VERSION ""

NS_ :

BS_:

BU_: CH DIPF DIPR ETH FC HVI HVS PARTY SDCV VEH VIRT

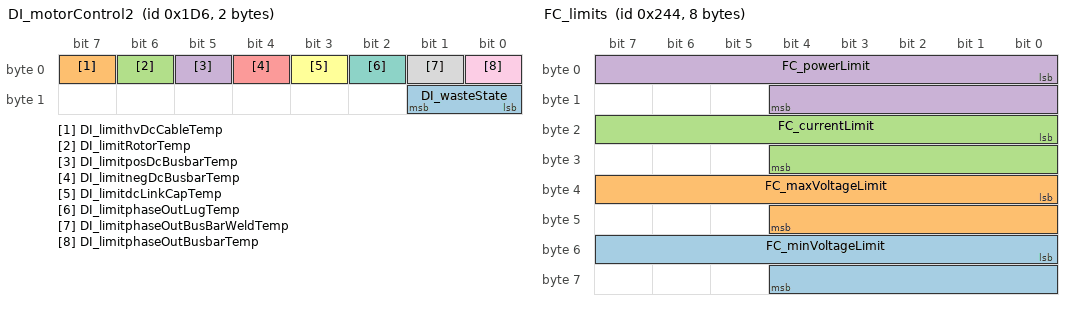
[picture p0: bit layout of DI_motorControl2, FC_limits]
BO_ 470 DI_motorControl2: 2 VEH
 SG_ DI_wasteState : 8|2@1+ (1,0) [0|2] ""  gtw
 SG_ DI_limithvDcCableTemp : 7|1@1+ (1,0) [0|1] ""  gtw
 SG_ DI_limitRotorTemp : 6|1@1+ (1,0) [0|1] ""  gtw
 SG_ DI_limitposDcBusbarTemp : 5|1@1+ (1,0) [0|1] ""  gtw
 SG_ DI_limitnegDcBusbarTemp : 4|1@1+ (1,0) [0|1] ""  gtw
 SG_ DI_limitdcLinkCapTemp : 3|1@1+ (1,0) [0|1] ""  gtw
 SG_ DI_limitphaseOutLugTemp : 2|1@1+ (1,0) [0|1] ""  gtw
 SG_ DI_limitphaseOutBusBarWeldTemp : 1|1@1+ (1,0) [0|1] ""  gtw
 SG_ DI_limitphaseOutBusbarTemp : 0|1@1+ (1,0) [0|1] ""  gtw

BO_ 580 FC_limits: 8 VEH
 SG_ FC_minVoltageLimit : 48|13@1+ (0.0732421875,0) [0|599.92675781] "V"  X
 SG_ FC_maxVoltageLimit : 32|13@1+ (0.07324218755,0) [0|599.92675822] "V"  X
 SG_ FC_currentLimit : 16|13@1+ (0.0732421875,0) [0|599.92675781] "A"  gtw
 SG_ FC_powerLimit : 0|13@1+ (0.062255859376,0) [0|509.93774415] "kW"  dbg

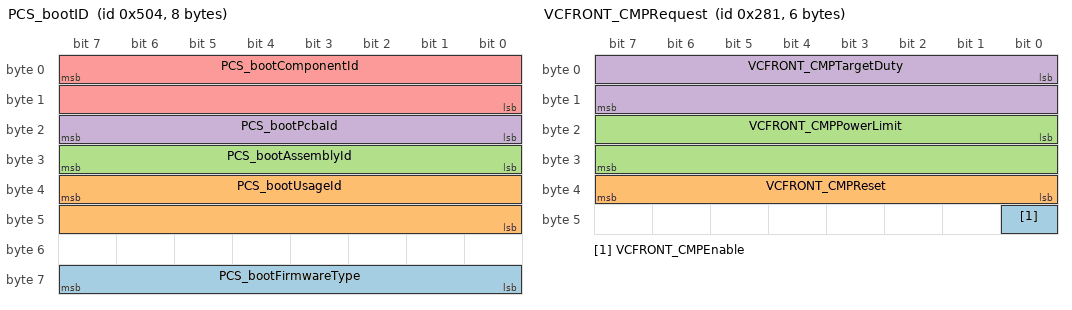
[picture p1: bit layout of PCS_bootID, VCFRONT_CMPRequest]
BO_ 1284 PCS_bootID: 8 VEH
 SG_ PCS_bootFirmwareType : 63|8@0+ (1,0) [0|255] ""  gtwu
 SG_ PCS_bootUsageId : 39|16@0+ (1,0) [0|65535] ""  gtwu
 SG_ PCS_bootAssemblyId : 31|8@0+ (1,0) [0|255] ""  gtwu
 SG_ PCS_bootPcbaId : 23|8@0+ (1,0) [0|255] ""  gtw
 SG_ PCS_bootComponentId : 7|16@0+ (1,0) [0|65535] ""  gtwu

BO_ 641 VCFRONT_CMPRequest: 6 VEH
 SG_ VCFRONT_CMPEnable : 40|1@1+ (1,0) [0|1] ""  cmp
 SG_ VCFRONT_CMPReset : 32|8@1+ (1,0) [0|255] ""  cmp
 SG_ VCFRONT_CMPPowerLimit : 16|16@1+ (1,0) [0|65534] "W"  cmp
 SG_ VCFRONT_CMPTargetDuty : 0|16@1+ (0.1,0) [0|100] "%"  cmp

BO_ 659 UI_chassisControl: 8 VEH
 SG_ UI_chassisControlChecksum : 56|8@1+ (1,0) [0|255] ""  epbl
 SG_ UI_chassisControlCounter : 52|4@1+ (1,0) [0|15] ""  epbl
 SG_ UI_selfParkTune : 48|4@1+ (1,0) [0|15] ""  das
 SG_ UI_redLightStopSignEnable : 46|2@1+ (1,0) [0|3] ""  das
 SG_ UI_pedalSafetyEnable : 44|2@1+ (1,0) [0|3] ""  das
 SG_ UI_ldwEnable : 42|2@1+ (1,0) [0|3] ""  das
 SG_ UI_latControlEnable : 40|2@1+ (1,0) [0|3] ""  das
 SG_ UI_fcwSensitivity : 38|2@1+ (1,0) [0|3] ""  das
 SG_ UI_fcwEnable : 36|2@1+ (1,0) [0|3] ""  das
 SG_ UI_bsdEnable : 34|2@1+ (1,0) [0|3] ""  das
 SG_ UI_autoLaneChangeEnable : 32|2@1+ (1,0) [0|3] ""  das
 SG_ UI_autoParkRequest : 28|4@1+ (1,0) [0|15] ""  das
 SG_ UI_rebootAutopilot : 27|1@1+ (1,0) [0|1] ""  X
 SG_ UI_ahlbEnable : 24|2@1+ (1,0) [0|3] ""  das
 SG_ UI_aesEnable : 22|2@1+ (1,0) [0|3] ""  das
 SG_ UI_aebEnable : 20|2@1+ (1,0) [0|3] ""  das
 SG_ UI_accOvertakeEnable : 18|2@1+ (1,0) [0|3] ""  das
 SG_ UI_dasDebugEnable : 17|1@1+ (1,0) [0|1] ""  das
 SG_ UI_distanceUnits : 16|1@1+ (1,0) [0|1] ""  di
 SG_ UI_suspensionLevelRequest : 13|3@1+ (1,0) [0|7] ""  X
 SG_ UI_trailerMode : 12|1@1+ (1,0) [0|1] ""  das
 SG_ UI_zeroSpeedConfirmed : 10|2@1+ (1,0) [0|3] ""  epbl
 SG_ UI_winchModeRequest : 8|2@1+ (1,0) [0|2] ""  epbl
 SG_ UI_narrowGarages : 7|1@1+ (1,0) [0|1] ""  das
 SG_ UI_parkBrakeRequest : 5|2@1+ (1,0) [0|3] ""  epbl
 SG_ UI_tractionControlMode : 2|3@1+ (1,0) [0|5] ""  di
 SG_ UI_steeringTuneRequest : 0|2@1+ (1,0) [0|2] ""  X

BO_ 504 VCLEFT_intrusionSensorStatus: 4 VEH
 SG_ VCLEFT_intrusionUltraTripped : 26|1@1+ (1,0) [0|1] ""  gtw
 SG_ VCLEFT_intrusionTiltTripped : 25|1@1+ (1,0) [0|1] ""  gtw
 SG_ VCLEFT_sirenMIA : 24|1@1+ (1,0) [0|1] ""  vcfront
 SG_ VCLEFT_DBG_System_Error : 23|1@1+ (1,0) [0|1] ""  gtw
 SG_ VCLEFT_DBG_LM_SelfTest_Status : 22|1@1+ (1,0) [0|1] ""  gtw
 SG_ VCLEFT_DBG_USS_SelfTest_Status : 21|1@1+ (1,0) [0|1] ""  gtw
 SG_ VCLEFT_DBG_Eeprom_ST_Status : 20|1@1+ (1,0) [0|1] ""  gtw
 SG_ VCLEFT_DBG_Reserved_08 : 19|1@1+ (1,0) [0|1] ""  X
 SG_ VCLEFT_DBG_Reserved_07 : 18|1@1+ (1,0) [0|1] ""  X
 SG_ VCLEFT_DBG_Siren_is_sounding : 17|1@1+ (1,0) [0|1] ""  gtw
 SG_ VCLEFT_DBG_Invalid_Parameter : 16|1@1+ (1,0) [0|1] ""  gtw
 SG_ VCLEFT_DBG_Siren_Int_Trigger : 15|1@1+ (1,0) [0|1] ""  gtw
 SG_ VCLEFT_DBG_Siren_ST_Status : 14|1@1+ (1,0) [0|1] ""  gtw
 SG_ VCLEFT_DBG_LM_Alarm_Status : 13|1@1+ (1,0) [0|1] ""  gtw
 SG_ VCLEFT_DBG_USS_Alarm_Status : 12|1@1+ (1,0) [0|1] ""  gtw
 SG_ VCLEFT_DBG_Veh_Settings_Status : 8|4@1+ (1,0) [0|15] ""  gtw
 SG_ VCLEFT_DBG_SelfTest_Status : 7|1@1+ (1,0) [0|1] ""  gtw
 SG_ VCLEFT_DBG_Suspensions_Status : 6|1@1+ (1,0) [0|1] ""  gtw
 SG_ VCLEFT_DBG_Window_Status : 5|1@1+ (1,0) [0|1] ""  gtw
 SG_ VCLEFT_DBG_Heater_Status : 4|1@1+ (1,0) [0|1] ""  gtw
 SG_ VCLEFT_DBG_Air_Cond_Status : 3|1@1+ (1,0) [0|1] ""  gtw
 SG_ VCLEFT_DBG_System_Status : 0|3@1+ (1,0) [0|7] ""  gtw

BO_ 895 FC_alertMatrix3: 8 VEH
 SG_ FC_a187_CA_evseConLockTimeout : 58|1@1+ (1,0) [0|1] ""  gtw
 SG_ FC_a186_CA_fcContOpenTimeout : 57|1@1+ (1,0) [0|1] ""  gtw
 SG_ FC_a185_CA_vehReadyDeasserted : 56|1@1+ (1,0) [0|1] ""  gtw
 SG_ FC_a184_CA_evseBatMalfunc : 55|1@1+ (1,0) [0|1] ""  gtw
 SG_ FC_a183_CA_evseBatIncompat : 54|1@1+ (1,0) [0|1] ""  gtw
 SG_ FC_a182_CA_evseChrMalfunc : 53|1@1+ (1,0) [0|1] ""  gtw
 SG_ FC_a181_CA_vRegBrownout : 52|1@1+ (1,0) [0|1] ""  gtw
 SG_ FC_a180_CA_chargingProblem : 51|1@1+ (1,0) [0|1] ""  gtw
 SG_ FC_a179_CA_startupProblem : 50|1@1+ (1,0) [0|1] ""  gtw
 SG_ FC_a178_CA_evseStartTimeout : 49|1@1+ (1,0) [0|1] ""  gtw
 SG_ FC_a177_CA_bmsCtrCloseTimeout : 48|1@1+ (1,0) [0|1] ""  gtw
 SG_ FC_a176_CA_chargingBusTimeout : 47|1@1+ (1,0) [0|1] ""  gtw
 SG_ FC_a175_CA_evseIsoTestTimeout : 46|1@1+ (1,0) [0|1] ""  gtw
 SG_ FC_a174_CA_vehReadyTimeout : 45|1@1+ (1,0) [0|1] ""  gtw
 SG_ FC_a173_CA_evseDataTimeout : 44|1@1+ (1,0) [0|1] ""  gtw
 SG_ FC_a172_CA_ss2LowTimeout : 43|1@1+ (1,0) [0|1] ""  gtw
 SG_ FC_a171_CA_vehConLockTimeout : 42|1@1+ (1,0) [0|1] ""  gtw
 SG_ FC_a170_CA_vehDataTimeout : 41|1@1+ (1,0) [0|1] ""  gtw
 SG_ FC_a169_CA_pilotAcceptTimeout : 40|1@1+ (1,0) [0|1] ""  gtw
 SG_ FC_a168_CA_proxTimeout : 39|1@1+ (1,0) [0|1] ""  gtw
 SG_ FC_a167_CA_isoVoltageLow : 38|1@1+ (1,0) [0|1] ""  gtw
 SG_ FC_a166_CA_vehConnUnlocked : 37|1@1+ (1,0) [0|1] ""  gtw
 SG_ FC_a165_CA_evseConnUnlocked : 36|1@1+ (1,0) [0|1] ""  gtw
 SG_ FC_a164_CA_proxDisconnected : 35|1@1+ (1,0) [0|1] ""  gtw
 SG_ FC_a163_CA_pcbTempHiFoldBk : 34|1@1+ (1,0) [0|1] ""  gtw
 SG_ FC_a162_CA_evseTempHiFoldBk : 33|1@1+ (1,0) [0|1] ""  gtw
 SG_ FC_a161_CA_vehTempHiFoldBk : 32|1@1+ (1,0) [0|1] ""  gtw
 SG_ FC_a160_CA_ss2Deasserted : 31|1@1+ (1,0) [0|1] ""  gtw
 SG_ FC_a159_CA_wdtExpired : 30|1@1+ (1,0) [0|1] ""  gtw
 SG_ FC_a158_CA_evseOverCurrent : 29|1@1+ (1,0) [0|1] ""  gtw
 SG_ FC_a157_CA_unused : 28|1@1+ (1,0) [0|1] ""  gtw
 SG_ FC_a156_CA_flybackRunTimeout : 27|1@1+ (1,0) [0|1] ""  gtw
 SG_ FC_a155_CA_evseToPcbDeltaLo : 26|1@1+ (1,0) [0|1] ""  gtw
 SG_ FC_a154_CA_vehToPcbDeltaLo : 25|1@1+ (1,0) [0|1] ""  gtw
 SG_ FC_a153_CA_evseToPcbDeltaHi : 24|1@1+ (1,0) [0|1] ""  gtw
 SG_ FC_a152_CA_vehToPcbDeltaHi : 23|1@1+ (1,0) [0|1] ""  gtw
 SG_ FC_a151_CA_vehToEvseDeltaLo : 22|1@1+ (1,0) [0|1] ""  gtw
 SG_ FC_a150_CA_vehToEvseDeltaHi : 21|1@1+ (1,0) [0|1] ""  gtw
 SG_ FC_a149_CA_pcb_UT : 20|1@1+ (1,0) [0|1] ""  gtw
 SG_ FC_a148_CA_evseConn_UT : 19|1@1+ (1,0) [0|1] ""  gtw
 SG_ FC_a147_CA_vehConn_UT : 18|1@1+ (1,0) [0|1] ""  gtw
 SG_ FC_a146_CA_flybackBusLoadHi : 17|1@1+ (1,0) [0|1] ""  gtw
 SG_ FC_a145_CA_flybackDataStale : 16|1@1+ (1,0) [0|1] ""  gtw
 SG_ FC_a144_CA_flybackUnstable : 15|1@1+ (1,0) [0|1] ""  gtw
 SG_ FC_a143_CA_pcb_OT : 14|1@1+ (1,0) [0|1] ""  gtw
 SG_ FC_a142_CA_evseConn_OT : 13|1@1+ (1,0) [0|1] ""  gtw
 SG_ FC_a141_CA_vehConn_OT : 12|1@1+ (1,0) [0|1] ""  gtw
 SG_ FC_a140_CA_bmsIncompatible : 11|1@1+ (1,0) [0|1] ""  gtw
 SG_ FC_a139_CA_ss2NotLow : 10|1@1+ (1,0) [0|1] ""  gtw
 SG_ FC_a138_CA_hwProxTrip : 9|1@1+ (1,0) [0|1] ""  gtw
 SG_ FC_a137_CA_evseRxBufOvf : 8|1@1+ (1,0) [0|1] ""  gtw
 SG_ FC_a136_CA_evseTxBufOvf : 7|1@1+ (1,0) [0|1] ""  gtw
 SG_ FC_a135_CA_vehRxBufOvf : 6|1@1+ (1,0) [0|1] ""  gtw
 SG_ FC_a134_CA_vehTxBufOvf : 5|1@1+ (1,0) [0|1] ""  gtw
 SG_ FC_a133_CA_evseMia : 4|1@1+ (1,0) [0|1] ""  gtw
 SG_ FC_a132_CA_bmsMia : 3|1@1+ (1,0) [0|1] ""  gtw
 SG_ FC_a131_CA_flyback_HW_OV : 2|1@1+ (1,0) [0|1] ""  gtw
 SG_ FC_a130_CA_flyback_SW_OV : 1|1@1+ (1,0) [0|1] ""  gtw
 SG_ FC_a129_CA_flyback_HW_OC : 0|1@1+ (1,0) [0|1] ""  gtw

BO_ 790 PM_info: 8 VEH
 SG_ PM_subUsageId m11 : 48|16@1+ (1,0) [0|65535] ""  gtw
 SG_ PM_componentId m10 : 48|16@1+ (1,0) [0|65535] ""  gtw
 SG_ PM_hardwareId m10 : 32|8@1+ (1,0) [0|252] ""  gtw
 SG_ PM_applicationCrc m13 : 32|32@1+ (1,0) [0|4294967295] ""  gtw
 SG_ PM_bootloaderCrc m20 : 32|32@1+ (1,0) [0|4294967295] ""  gtw
 SG_ PM_diNodeApplicationCrc m21 : 32|32@1+ (1,0) [0|4294967295] ""  gtw
 SG_ PM_usageId m11 : 32|16@1+ (1,0) [0|65535] ""  gtw
 SG_ PM_bootloaderSvnUrlHash m14 : 32|32@1+ (1,0) [0|4294967295] ""  gtw
 SG_ PM_assemblyId m11 : 24|8@1+ (1,0) [0|255] ""  gtw
 SG_ PM_buildConfigurationId m10 : 16|16@1+ (1,0) [0|65535] ""  gtw
 SG_ PM_pcbaId m11 : 16|8@1+ (1,0) [0|255] ""  gtw
 SG_ PM_diNodeBuildConfigurationId m21 : 16|16@1+ (1,0) [0|65535] ""  X
 SG_ PM_diNodeBuildType m21 : 8|8@1+ (1,0) [0|4] ""  gtw
 SG_ PM_bootloaderSvnRevision m14 : 8|24@1+ (1,0) [0|16777215] ""  gtw
 SG_ PM_udsProtocolVersion m20 : 8|8@1+ (1,0) [0|255] ""  gtw
 SG_ PM_appGitHash m17 : 8|56@1+ (1,0) [0|72057594037927935] ""  gtw
 SG_ PM_platformTyp m19 : 8|8@1+ (1,0) [0|255] ""  gtw
 SG_ PM_buildType m10 : 8|8@1+ (1,0) [0|4] ""  gtw
 SG_ PM_bootGitHash m18 : 8|56@1+ (1,0) [0|72057594037927935] ""  gtw
 SG_ PM_infoIndex M : 0|8@1+ (1,0) [0|255] ""  gtw

BO_ 1622 DI_info: 8 VEH
 SG_ DI_subUsageId m11 : 48|16@1+ (1,0) [0|65535] ""  gtw
 SG_ DI_componentId m10 : 48|16@1+ (1,0) [0|65535] ""  gtw
 SG_ DI_hardwareId m10 : 32|8@1+ (1,0) [0|252] ""  X
 SG_ DI_applicationCrc m13 : 32|32@1+ (1,0) [0|4294967295] ""  gtw
 SG_ DI_applicationSvnUrlHash m12 : 32|32@1+ (1,0) [0|4294967295] ""  gtw
 SG_ DI_bootloaderCrc m20 : 32|32@1+ (1,0) [0|4294967295] ""  gtw
 SG_ DI_usageId m11 : 32|16@1+ (1,0) [0|65535] ""  gtw
 SG_ DI_bootloaderSvnUrlHash m14 : 32|32@1+ (1,0) [0|4294967295] ""  gtw
 SG_ DI_assemblyId m11 : 24|8@1+ (1,0) [0|255] ""  gtw
 SG_ DI_buildConfigurationId m10 : 16|16@1+ (1,0) [0|65535] ""  gtw
 SG_ DI_oilPumpAppCrc m16 : 16|32@1+ (1,0) [0|4294967295] ""  gtw
 SG_ DI_pcbaId m11 : 16|8@1+ (1,0) [0|255] ""  gtw
 SG_ DI_applicationSvnRevision m12 : 8|24@1+ (1,0) [0|16777215] ""  X
 SG_ DI_bootloaderSvnRevision m14 : 8|24@1+ (1,0) [0|16777215] ""  gtw
 SG_ DI_infoBootLdUdsProtocolVersion m20 : 8|8@1+ (1,0) [0|255] ""  X
 SG_ DI_subcomponentGitHash m31 : 8|56@1+ (1,0) [0|72057594037927935] ""  X
 SG_ DI_oilPumpBuildType m16 : 8|3@1+ (1,0) [0|4] ""  gtw
 SG_ DI_appGitHash m17 : 8|56@1+ (1,0) [0|72057594037927935] ""  X
 SG_ DI_platformTyp m19 : 8|8@1+ (1,0) [0|255] ""  X
 SG_ DI_bootGitHash m18 : 8|56@1+ (1,0) [0|72057594037927935] ""  gtw
 SG_ DI_buildType m10 : 8|3@1+ (1,0) [0|4] ""  gtw
 SG_ DI_infoIndex M : 0|8@1+ (1,0) [0|255] ""  gtw

BO_ 738 VCLEFT_seatStatus2: 8 VEH
 SG_ VCLEFT_rearRightOccupancyVoltage m2 : 54|10@1+ (0.01,0) [0|10.23] "V"  gtw
 SG_ VCLEFT_frontSeatHeatPowered m0 : 45|1@1+ (1,0) [0|1] ""  X
 SG_ VCLEFT_rearLBackHeatPowered m1 : 45|1@1+ (1,0) [0|1] ""  X
 SG_ VCLEFT_frontSeatHeatInhibited m0 : 44|1@1+ (1,0) [0|1] ""  gtw
 SG_ VCLEFT_rearCenterOccupancyVoltag m2 : 44|10@1+ (0.01,0) [0|10.23] "V"  gtw
 SG_ VCLEFT_rearLBackHeatInhibited m1 : 44|1@1+ (1,0) [0|1] ""  gtw
 SG_ VCLEFT_rearLBackHeatTmpTarget m1 : 36|8@1- (0.5,0) [0|60] "degC"  gtw
 SG_ VCLEFT_frontSeatHeatTmpTarget m0 : 36|8@1- (0.5,0) [0|60] "degC"  gtw
 SG_ VCLEFT_rearLeftOccupancyVoltage m2 : 34|10@1+ (0.01,0) [0|10.23] "V"  gtw
 SG_ VCLEFT_frontSeatHeatTmp m0 : 24|12@1- (0.05,0) [-40|80] "degC"  gtw
 SG_ VCLEFT_rearLBackHeatTmp m1 : 24|12@1- (0.05,0) [-40|80] "degC"  X
 SG_ VCLEFT_rearLeftBuckleVoltage m2 : 24|10@1+ (0.01,0) [0|10.23] "V"  gtw
 SG_ VCLEFT_rearLBackHeatDuty m1 : 16|8@1+ (1,0) [0|255] "%"  gtw
 SG_ VCLEFT_frontSeatHeatDuty m0 : 16|8@1+ (1,0) [0|255] "%"  gtw
 SG_ VCLEFT_frontBuckleVoltage m2 : 14|10@1+ (0.01,0) [0|10.23] "V"  gtw
 SG_ VCLEFT_frontSeatHeatCurrent m0 : 4|12@1+ (0.01,0) [0|40.95] "A"  gtw
 SG_ VCLEFT_rearLBackHeatCurrent m1 : 4|12@1+ (0.01,0) [0|40.95] "A"  gtw
 SG_ VCLEFT_frontOccupancyVoltage m2 : 4|10@1+ (0.01,0) [0|10.23] "V"  gtw
 SG_ VCLEFT_seatStatus2Index M : 0|2@1+ (1,0) [0|3] ""  X

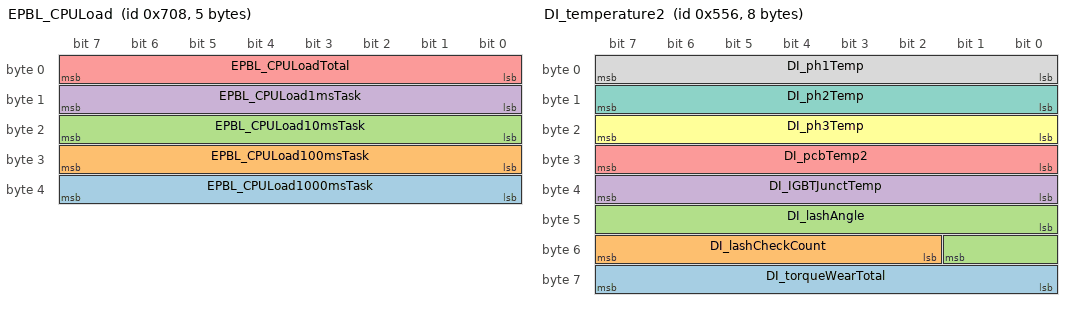
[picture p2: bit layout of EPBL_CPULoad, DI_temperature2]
BO_ 1800 EPBL_CPULoad: 5 VEH
 SG_ EPBL_CPULoad1000msTask : 32|8@1+ (1,0) [0|255] ""  X
 SG_ EPBL_CPULoad100msTask : 24|8@1+ (1,0) [0|255] ""  X
 SG_ EPBL_CPULoad10msTask : 16|8@1+ (1,0) [0|255] ""  X
 SG_ EPBL_CPULoad1msTask : 8|8@1+ (1,0) [0|255] ""  X
 SG_ EPBL_CPULoadTotal : 0|8@1+ (1,0) [0|255] ""  X

BO_ 922 VCSEC_RSSI: 8 VEH
 SG_ VCSEC_BLEDevicePresence3 m1 : 58|5@1+ (1,0) [0|31] ""  gtw
 SG_ VCSEC_BLEDevicePresence0 m0 : 58|5@1+ (1,0) [0|31] ""  gtw
 SG_ VCSEC_UnknownBLEDevicePresent m0 : 57|1@1+ (1,0) [0|1] ""  gtw
 SG_ VCSEC_BLEDevicePresence2 m1 : 53|5@1+ (1,0) [0|31] ""  gtw
 SG_ VCSEC_rearBLEAntennaRSSI1 m0 : 49|8@1- (1,0) [-127|0] ""  gtw
 SG_ VCSEC_BLEDevicePresence1 m1 : 48|5@1+ (1,0) [0|31] ""  gtw
 SG_ VCSEC_rightBLEAntennaRSSI1 m0 : 41|8@1- (1,0) [-127|0] ""  gtw
 SG_ VCSEC_centerBLEAntennaRSSI2 m1 : 40|8@1- (1,0) [-127|0] ""  gtw
 SG_ VCSEC_leftBLEAntennaRSSI1 m0 : 33|8@1- (1,0) [-127|0] ""  gtw
 SG_ VCSEC_rearBLEAntennaRSSI2 m1 : 32|8@1- (1,0) [-127|0] ""  gtw
 SG_ VCSEC_centerBLEAntennaRSSI0 m0 : 25|8@1- (1,0) [-127|0] ""  dbg
 SG_ VCSEC_rightBLEAntennaRSSI2 m1 : 24|8@1- (1,0) [-127|0] ""  gtw
 SG_ VCSEC_rearBLEAntennaRSSI0 m0 : 17|8@1- (1,0) [-127|0] ""  dbg
 SG_ VCSEC_leftBLEAntennaRSSI2 m1 : 16|8@1- (1,0) [-127|0] ""  gtw
 SG_ VCSEC_rightBLEAntennaRSSI0 m0 : 9|8@1- (1,0) [-127|0] ""  dbg
 SG_ VCSEC_centerBLEAntennaRSSI1 m1 : 8|8@1- (1,0) [-127|0] ""  gtw
 SG_ VCSEC_leftBLEAntennaRSSI0 m0 : 1|8@1- (1,0) [-127|0] ""  dbg
 SG_ VCSEC_RSSIChannelIndex M : 0|1@1+ (1,0) [0|1] ""  X

BO_ 1576 UDS_pcsRequest: 8 VEH
 SG_ UDS_pcsRequestData : 7|64@0+ (1,0) [0|18446744073709551615] ""  bms

BO_ 1366 DI_temperature2: 8 VEH
 SG_ DI_torqueWearTotal : 56|8@1+ (0.02,0) [0|5.08] "1"  X
 SG_ DI_lashCheckCount : 50|6@1+ (1,0) [0|63] ""  gtw
 SG_ DI_lashAngle : 40|10@1+ (0.06,0) [0|60] "Deg"  X
 SG_ DI_IGBTJunctTemp : 32|8@1+ (1,-40) [-40|200] "DegC"  X
 SG_ DI_pcbTemp2 : 24|8@1+ (1,-40) [-40|150] "DegC"  X
 SG_ DI_ph3Temp : 16|8@1+ (1,-40) [-40|120] "DegC"  X
 SG_ DI_ph2Temp : 8|8@1+ (1,-40) [-40|120] "DegC"  gtw
 SG_ DI_ph1Temp : 0|8@1+ (1,-40) [-40|120] "DegC"  gtw

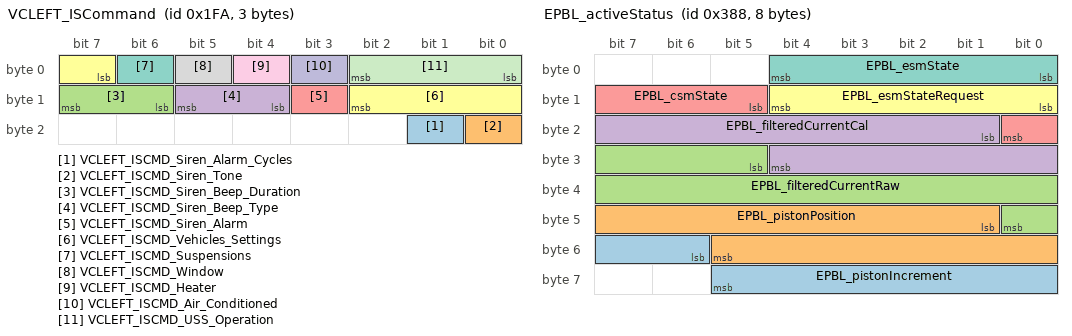
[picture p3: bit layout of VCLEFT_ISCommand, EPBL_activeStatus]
BO_ 506 VCLEFT_ISCommand: 3 VEH
 SG_ VCLEFT_ISCMD_Siren_Alarm_Cycles : 17|1@1+ (1,0) [0|1] ""  gtw
 SG_ VCLEFT_ISCMD_Siren_Tone : 16|1@1+ (1,0) [0|1] ""  gtw
 SG_ VCLEFT_ISCMD_Siren_Beep_Duration : 14|2@1+ (1,0) [0|3] ""  gtw
 SG_ VCLEFT_ISCMD_Siren_Beep_Type : 12|2@1+ (1,0) [0|3] ""  gtw
 SG_ VCLEFT_ISCMD_Siren_Alarm : 11|1@1+ (1,0) [0|1] ""  gtw
 SG_ VCLEFT_ISCMD_Vehicles_Settings : 7|4@1+ (1,0) [0|15] ""  gtw
 SG_ VCLEFT_ISCMD_Suspensions : 6|1@1+ (1,0) [0|1] ""  gtw
 SG_ VCLEFT_ISCMD_Window : 5|1@1+ (1,0) [0|1] ""  gtw
 SG_ VCLEFT_ISCMD_Heater : 4|1@1+ (1,0) [0|1] ""  gtw
 SG_ VCLEFT_ISCMD_Air_Conditioned : 3|1@1+ (1,0) [0|1] ""  gtw
 SG_ VCLEFT_ISCMD_USS_Operation : 0|3@1+ (1,0) [0|7] ""  gtw

BO_ 2024 EPBR_info: 8 VEH
 SG_ EPBR_infoComponentId m10 : 48|16@1+ (1,0) [0|65535] ""  gtw
 SG_ EPBR_infoSubUsageId m11 : 40|16@1+ (1,0) [0|65535] ""  gtw
 SG_ EPBR_infoHardwareId m10 : 32|16@1+ (1,0) [0|65535] ""  gtw
 SG_ EPBR_infoBootCrc m20 : 24|32@1+ (1,0) [0|4294967295] ""  gtw
 SG_ EPBR_infoUsageId m11 : 24|16@1+ (1,0) [0|65535] ""  gtw
 SG_ EPBR_infoAssemblyId m11 : 16|8@1+ (1,0) [0|255] ""  gtw
 SG_ EPBR_infoBuildConfigId m10 : 16|16@1+ (1,0) [0|65535] ""  gtw
 SG_ EPBR_infoPcbaId m11 : 8|8@1+ (1,0) [0|255] ""  gtw
 SG_ EPBR_infoPlatformType m19 : 8|8@1+ (1,0) [0|255] ""  gtw
 SG_ EPBR_infoBootUdsProtoVersion m20 : 8|16@1+ (1,0) [0|65535] ""  gtw
 SG_ EPBR_infoAppGitHash m17 : 8|56@1+ (1,0) [0|72057594037927935] ""  gtw
 SG_ EPBR_infoBuildType m10 : 8|3@1+ (1,0) [0|4] ""  gtw
 SG_ EPBR_infoBootGitHash m18 : 8|56@1+ (1,0) [0|72057594037927935] ""  gtw
 SG_ EPBR_infoAppCrc m13 : 8|32@1+ (1,0) [0|4294967295] ""  gtw
 SG_ EPBR_infoIndex M : 0|8@1+ (1,0) [0|255] ""  gtw

BO_ 533 FC_status2: 1 VEH
 SG_ FC_externalIsolationResistance : 0|8@1+ (40,0) [0|10200] "kOhm"  dbg

BO_ 1359 SCCM_alertMatrix: 8 VEH
 SG_ SCCM_a029_parkButtonMalfunction m0 : 32|1@1+ (1,0) [0|1] ""  gtw
 SG_ SCCM_a028_parkButtonShortToGroun m0 : 31|1@1+ (1,0) [0|1] ""  gtw
 SG_ SCCM_a027_parkButtonOpenCircuit m0 : 30|1@1+ (1,0) [0|1] ""  gtw
 SG_ SCCM_a026_parkButtonInvalidSigna m0 : 29|1@1+ (1,0) [0|1] ""  gtw
 SG_ SCCM_a025_runTimeError m0 : 28|1@1+ (1,0) [0|1] ""  gtw
 SG_ SCCM_a024_gearStalkGenErr m0 : 27|1@1+ (1,0) [0|1] ""  gtw
 SG_ SCCM_a023_gearStalkShortCircuit m0 : 26|1@1+ (1,0) [0|1] ""  gtw
 SG_ SCCM_a022_gearStalkOpenCircuit m0 : 25|1@1+ (1,0) [0|1] ""  gtw
 SG_ SCCM_a021_gearStalkSignalInvalid m0 : 24|1@1+ (1,0) [0|1] ""  gtw
 SG_ SCCM_a020_angleInternalError m0 : 23|1@1+ (1,0) [0|1] ""  gtw
 SG_ SCCM_a019_angleSpeedAboveLimit m0 : 22|1@1+ (1,0) [0|1] ""  gtw
 SG_ SCCM_a018_angleSpeedOutOfRange m0 : 21|1@1+ (1,0) [0|1] ""  gtw
 SG_ SCCM_a017_memoryError m0 : 20|1@1+ (1,0) [0|1] ""  gtw
 SG_ SCCM_a016_hardwareError m0 : 19|1@1+ (1,0) [0|1] ""  gtw
 SG_ SCCM_a015_softwareError m0 : 18|1@1+ (1,0) [0|1] ""  gtw
 SG_ SCCM_a014_voltageLow m0 : 17|1@1+ (1,0) [0|1] ""  gtw
 SG_ SCCM_a013_voltageHigh m0 : 16|1@1+ (1,0) [0|1] ""  gtw
 SG_ SCCM_a012_turnGenErr m0 : 15|1@1+ (1,0) [0|1] ""  gtw
 SG_ SCCM_a011_turnIndHWErr m0 : 14|1@1+ (1,0) [0|1] ""  gtw
 SG_ SCCM_a010_turnIndShortToGnd m0 : 13|1@1+ (1,0) [0|1] ""  gtw
 SG_ SCCM_a009_turnIndOpen m0 : 12|1@1+ (1,0) [0|1] ""  gtw
 SG_ SCCM_a008_turnIndInvalidTrans m0 : 11|1@1+ (1,0) [0|1] ""  gtw
 SG_ SCCM_a007_turnIndComInfo m0 : 10|1@1+ (1,0) [0|1] ""  gtw
 SG_ SCCM_a006_tipWipeShortToGND m0 : 9|1@1+ (1,0) [0|1] ""  gtw
 SG_ SCCM_a005_tipWipeOpen m0 : 8|1@1+ (1,0) [0|1] ""  gtw
 SG_ SCCM_a004_highBeamShortToGND m0 : 7|1@1+ (1,0) [0|1] ""  gtw
 SG_ SCCM_a003_highBeamOpen m0 : 6|1@1+ (1,0) [0|1] ""  gtw
 SG_ SCCM_a002_CANTOut m0 : 5|1@1+ (1,0) [0|1] ""  gtw
 SG_ SCCM_a001_CANBusOff m0 : 4|1@1+ (1,0) [0|1] ""  gtw
 SG_ SCCM_matrixIndex M : 0|4@1+ (1,0) [0|15] ""  gtw

BO_ 904 EPBL_activeStatus: 8 VEH
 SG_ EPBL_pistonIncrement : 54|8@1- (0.05,2.0) [0|4] "vCounts"  X
 SG_ EPBL_pistonPosition : 41|13@1- (9.768009768009769,0.0) [-20000|20000] "vCounts"  X
 SG_ EPBL_filteredCurrentRaw : 29|12@1+ (0.01,0) [0|40.95] "A"  gtw
 SG_ EPBL_filteredCurrentCal : 17|12@1+ (0.01,0) [0|40.95] "A"  gtw
 SG_ EPBL_csmState : 13|4@1+ (1,0) [0|14] ""  gtw
 SG_ EPBL_esmStateRequest : 8|5@1+ (1,0) [0|19] ""  gtw
 SG_ EPBL_esmState : 0|5@1+ (1,0) [0|19] ""  gtw

BO_ 708 PCS_logging: 8 VEH
 SG_ PCS_chg5VL1Enable m5 : 61|1@1+ (1,0) [0|1] ""  gtw
 SG_ PCS_chgPhManOptimalPhsToUse m5 : 59|2@1+ (1,0) [0|3] ""  gtw
 SG_ PCS_chgNgPllLocked m5 : 58|1@1+ (1,0) [0|1] ""  X
 SG_ PCS_chgL1L2PllLocked m5 : 57|1@1+ (1,0) [0|1] ""  gtw
 SG_ PCS_numAlertsSet m9 : 56|7@1+ (1,0) [0|127] ""  X
 SG_ PCS_chgL3NPllLocked m5 : 56|1@1+ (1,0) [0|1] ""  gtw
 SG_ PCS_chgL2NPllLocked m5 : 55|1@1+ (1,0) [0|1] ""  gtw
 SG_ PCS_chgPhBTransientRetryCount m11 : 55|9@1+ (0.1,0) [0|51.1] "-"  gtw
 SG_ PCS_chgPhCTransientRetryCount m12 : 55|9@1+ (0.1,0) [0|51.1] "-"  gtw
 SG_ PCS_chgPhATransientRetryCount m10 : 55|9@1+ (0.1,0) [0|51.1] "-"  gtw
 SG_ PCS_chgL1NPllLocked m5 : 54|1@1+ (1,0) [0|1] ""  gtw
 SG_ PCS_chgInputNGVrms m3 : 53|9@1+ (1,0) [0|511] "V"  gtw
 SG_ PCS_dcdcLvOutputCurrentTempLimit m6 : 52|12@1+ (0.1,0) [0|400] "A"  gtw
 SG_ PCS_chgPhCInputFreqWobble m13 : 48|8@1+ (0.001,0) [0|0.255] "Hz"  gtw
 SG_ PCS_dcdcIntervalMaxLvOutputCurr m18 : 48|12@1+ (1,0) [0|400] "A"  gtw
 SG_ PCS_dcdcIntervalMinLvOutputCurr m19 : 48|12@1+ (1,0) [0|400] "A"  gtw
 SG_ PCS_dLogPhCChannel1Data m14 : 48|16@1- (0.02,0) [-655.36|655.34] "-"  X
 SG_ PCS_dLogPhCChannel4Data m17 : 48|16@1- (0.02,0) [-655.36|655.34] "-"  X
 SG_ PCS_dcdcClaCurrentFreq m7 : 48|12@1+ (0.09765625,0) [0|400] "kHz"  gtw
 SG_ PCS_dLogPhCChannel2Data m15 : 48|16@1- (0.02,0) [-655.36|655.34] "-"  X
 SG_ PCS_chgOutputV m4 : 48|12@1+ (0.146484375,0) [0|600] "V"  gtw
 SG_ PCS_dLogPhCChannel3Data m16 : 48|16@1- (0.02,0) [-655.36|655.34] "-"  X
 SG_ PCS_chgInputNGVdc m21 : 46|10@1- (1,0) [-512|511] "V"  gtw
 SG_ PCS_chgPhManCurrentToDist m5 : 44|10@1+ (0.1,0) [0|100] "A"  gtw
 SG_ PCS_chgInternalPhaseConfig m4 : 44|4@1+ (1,0) [0|8] ""  gtw
 SG_ PCS_1V2Max10s m9 : 43|11@1+ (0.001,0) [0|2.047] "V"  gtw
 SG_ PCS_dcdcPwmEnableLineErrorCount m22 : 42|10@1+ (1,0) [0|1023] ""  gtw
 SG_ PCS_chgRetryCount m5 : 41|3@1+ (1,0) [0|7] ""  gtw
 SG_ PCS_chgInputL1L2Vrms m3 : 41|12@1+ (0.2,0) [0|819] "V"  gtw
 SG_ PCS_chgPhBInputFreqWobble m13 : 40|8@1+ (0.001,0) [0|0.255] "Hz"  gtw
 SG_ PCS_dcdcCurrentLimit m6 : 40|12@1+ (0.1,0) [0|400] "A"  gtw
 SG_ PCS_dcdcHalfPeriodUs m8 : 40|16@1+ (0.00048828125,0) [0|32] "us"  X
 SG_ PCS_chgPhCRetryCount m5 : 38|3@1+ (1,0) [0|7] ""  gtw
 SG_ PCS_dcdcIntervalMaxLvBusVolt m18 : 37|9@1+ (0.1,0) [0|40] "V"  gtw
 SG_ PCS_dcdcTankVoltageTarget m7 : 37|10@1+ (1,0) [0|1024] "V"  gtw
 SG_ PCS_dcdcIntervalMinLvBusVolt m19 : 37|9@1+ (0.1,0) [0|40] "V"  gtw
 SG_ PCS_chgInputL1L2Vdc m21 : 36|10@1- (1,0) [-512|511] "V"  gtw
 SG_ PCS_chgPhBRetryCount m5 : 35|3@1+ (1,0) [0|7] ""  gtw
 SG_ PCS_chgPhARetryCount m5 : 32|3@1+ (1,0) [0|7] ""  gtw
 SG_ PCS_dLogPhBChannel1Data m14 : 32|16@1- (0.02,0) [-655.36|655.34] "-"  X
 SG_ PCS_chgPhCOutputI m2 : 32|8@1+ (0.1,0) [0|25.5] "A"  gtw
 SG_ PCS_chgInputFrequencyL3N m4 : 32|12@1+ (0.01,40) [40|80.95] "Hz"  gtw
 SG_ PCS_chgPwmEnableLineErrorCount m22 : 32|10@1+ (1,0) [0|1023] ""  gtw
 SG_ PCS_chgPhAInputFreqWobble m13 : 32|8@1+ (0.001,0) [0|0.255] "Hz"  gtw
 SG_ PCS_dLogPhBChannel3Data m16 : 32|16@1- (0.02,0) [-655.36|655.34] "-"  X
 SG_ PCS_dLogPhBChannel4Data m17 : 32|16@1- (0.02,0) [-655.36|655.34] "-"  X
 SG_ PCS_1V2Min10s m9 : 32|11@1+ (0.001,0) [0|2.047] "V"  gtw
 SG_ PCS_chgPhBOutputI m1 : 32|8@1+ (0.1,0) [0|25.5] "A"  gtw
 SG_ PCS_chgPhAOutputI m0 : 32|8@1+ (0.1,0) [0|25.5] "A"  gtw
 SG_ PCS_dLogPhBChannel2Data m15 : 32|16@1- (0.02,0) [-655.36|655.34] "-"  X
 SG_ PCS_chgPhBLifetimekWh m11 : 31|24@1+ (0.01,0) [0|167772.15] "kWh"  gtw
 SG_ PCS_chgPhCLifetimekWh m12 : 31|24@1+ (0.01,0) [0|167772.15] "kWh"  gtw
 SG_ PCS_chgPhALifetimekWh m10 : 31|24@1+ (0.01,0) [0|167772.15] "kWh"  gtw
 SG_ PCS_chgInputL3NVrms m3 : 29|12@1+ (0.2,0) [0|819] "V"  gtw
 SG_ PCS_dcdcMaxLvOutputCurrent m6 : 28|12@1+ (0.1,0) [0|400] "A"  gtw
 SG_ PCS_chgPhCLastShutdownReason m5 : 27|5@1+ (1,0) [0|17] ""  gtw
 SG_ PCS_chgInputL3NVdc m21 : 26|10@1- (1,0) [-512|511] "V"  gtw
 SG_ PCS_dcdcTankVoltage m7 : 26|11@1- (1,0) [-1024|1023] "V"  gtw
 SG_ PCS_dcdcIntervalMinHvBusVolt m19 : 24|13@1+ (0.1,0) [0|600] "V"  gtw
 SG_ PCS_dcdcShortTimeUs m8 : 24|16@1+ (0.00048828125,0) [0|32] "us"  X
 SG_ PCS_dcdcIntervalMaxHvBusVolt m18 : 24|13@1+ (0.1,0) [0|600] "V"  gtw
 SG_ PCS_chgPhBIntBusVTarget m1 : 23|9@1+ (1,0) [0|511] "V"  gtw
 SG_ PCS_chgPhAPchgVoltDeltaMax10s m10 : 23|8@1+ (0.5,0) [0|127.5] "V"  gtw
 SG_ PCS_chgPhCNoFlowBucket m20 : 23|9@1+ (0.01,0) [0|5.11] "-"  gtw
 SG_ PCS_chgPhBPchgVoltDeltaMax10s m11 : 23|8@1+ (0.5,0) [0|127.5] "V"  gtw
 SG_ PCS_chgPhAIntBusVTarget m0 : 23|9@1+ (1,0) [0|511] "V"  gtw
 SG_ PCS_chgInputL3NVPeak10s m13 : 23|9@1+ (1,0) [0|511] "V"  gtw
 SG_ PCS_chgPhCPchgVoltDeltaMax10s m12 : 23|8@1+ (0.5,0) [0|127.5] "V"  gtw
 SG_ PCS_chgPhCIntBusVTarget m2 : 23|9@1+ (1,0) [0|511] "V"  gtw
 SG_ PCS_chgPhBLastShutdownReason m5 : 22|5@1+ (1,0) [0|17] ""  gtw
 SG_ PCS_chgInputFrequencyL2N m4 : 20|12@1+ (0.01,40) [40|80.95] "Hz"  gtw
 SG_ PCS_1V5Max10s m9 : 19|11@1+ (0.001,0) [0|2.047] "V"  gtw
 SG_ PCS_chgInputL2NVrms m3 : 17|12@1+ (0.2,0) [0|819] "V"  gtw
 SG_ PCS_chgPhALastShutdownReason m5 : 17|5@1+ (1,0) [0|17] ""  gtw
 SG_ PCS_dLogPhAChannel4Data m17 : 16|16@1- (0.02,0) [-655.36|655.34] "-"  X
 SG_ PCS_dcdcPchgStartHvBusVolt m24 : 16|12@1+ (0.146484375,0) [0|600] "V"  gtw
 SG_ PCS_dcdcCLAControllerOutput m7 : 16|10@1+ (0.001,0) [0|1] "1"  gtw
 SG_ PCS_dLogPhAChannel2Data m15 : 16|16@1- (0.02,0) [-655.36|655.34] "-"  X
 SG_ PCS_dcdcHvBusEstimated_R_kOhm m25 : 16|10@1+ (0.04887585532746823,0) [0|50] "kOhm"  gtw
 SG_ PCS_chgInputL2NVdc m21 : 16|10@1- (1,0) [-512|511] "V"  gtw
 SG_ PCS_dLogPhAChannel3Data m16 : 16|16@1- (0.02,0) [-655.36|655.34] "-"  X
 SG_ PCS_dLogPhAChannel1Data m14 : 16|16@1- (0.02,0) [-655.36|655.34] "-"  X
 SG_ PCS_dcdcHvBusVolt m6 : 16|12@1+ (0.146484375,0) [0|600] "V"  gtw
 SG_ PCS_chgPhCIntBusV m2 : 14|9@1+ (1,0) [0|511] "V"  gtw
 SG_ PCS_chgInputL2NVPeak10s m13 : 14|9@1+ (1,0) [0|511] "V"  gtw
 SG_ PCS_chgPhAIntBusVMax10s m10 : 14|9@1+ (1,0) [0|511] "V"  gtw
 SG_ PCS_chgPhBNoFlowBucket m20 : 14|9@1+ (0.01,0) [0|5.11] "-"  gtw
 SG_ PCS_chgPhBIntBusVMax10s m11 : 14|9@1+ (1,0) [0|511] "V"  gtw
 SG_ PCS_chgPhAIntBusV m0 : 14|9@1+ (1,0) [0|511] "V"  gtw
 SG_ PCS_chgPhBIntBusV m1 : 14|9@1+ (1,0) [0|511] "V"  gtw
 SG_ PCS_chgPhCIntBusVMax10s m12 : 14|9@1+ (1,0) [0|511] "V"  gtw
 SG_ PCS_chgPhCState m5 : 13|4@1+ (1,0) [0|6] ""  gtw
 SG_ PCS_dLogPhCChannel4Content m17 : 10|2@1+ (1,0) [0|3] ""  X
 SG_ PCS_dLogPhCChannel1Content m14 : 10|2@1+ (1,0) [0|3] ""  X
 SG_ PCS_dLogPhCChannel2Content m15 : 10|2@1+ (1,0) [0|3] ""  X
 SG_ PCS_dLogPhCChannel3Content m16 : 10|2@1+ (1,0) [0|3] ""  X
 SG_ PCS_chgPhBState m5 : 9|4@1+ (1,0) [0|6] ""  gtw
 SG_ PCS_dcdcIntervalMinFrequency m19 : 8|12@1+ (1,0) [0|400] "kHz"  gtw
 SG_ PCS_dLogPhBChannel1Content m14 : 8|2@1+ (1,0) [0|3] ""  X
 SG_ PCS_dcdcIntervalMaxFrequency m18 : 8|12@1+ (1,0) [0|400] "kHz"  gtw
 SG_ PCS_chgInputFrequencyL1N m4 : 8|12@1+ (0.01,40) [40|80.95] "Hz"  gtw
 SG_ PCS_dLogPhBChannel3Content m16 : 8|2@1+ (1,0) [0|3] ""  X
 SG_ PCS_dcdcTCommMeasured m8 : 8|16@1- (0.001953125,0) [-64|64] "us"  X
 SG_ PCS_dLogPhBChannel4Content m17 : 8|2@1+ (1,0) [0|3] ""  X
 SG_ PCS_1V5Min10s m9 : 8|11@1+ (0.001,0) [0|2.047] "V"  gtw
 SG_ PCS_dLogPhBChannel2Content m15 : 8|2@1+ (1,0) [0|3] ""  X
 SG_ PCS_dcdc12vSupportLifetimekWh m22 : 8|24@1+ (0.01,0) [0|167772.15] "kWh"  gtw
 SG_ PCS_acChargeSelfTestState m9 : 7|1@1+ (1,0) [0|1] ""  X
 SG_ PCS_chgPhAInputIrms m0 : 5|9@1+ (0.1,0) [0|51.1] "A"  gtw
 SG_ PCS_chgPhCIntBusVMin10s m12 : 5|9@1+ (1,0) [0|511] "V"  gtw
 SG_ PCS_dLogPhAChannel2Content m15 : 5|2@1+ (1,0) [0|3] ""  X
 SG_ PCS_dcdcLvBusVolt m6 : 5|10@1+ (0.0390625,0) [0|40] "V"  gtw
 SG_ PCS_chgPhAState m5 : 5|4@1+ (1,0) [0|6] ""  gtw
 SG_ PCS_cpu2BootState m9 : 5|2@1+ (1,0) [0|3] ""  dbg
 SG_ PCS_chgPhBInputIrms m1 : 5|9@1+ (0.1,0) [0|51.1] "A"  gtw
 SG_ PCS_dLogPhAChannel3Content m16 : 5|2@1+ (1,0) [0|3] ""  X
 SG_ PCS_dcdcHvBusEstimated_C_uF m25 : 5|10@1+ (7.820136852394917,0) [0|8000] "uF"  gtw
 SG_ PCS_chgInputL1NVrms m3 : 5|12@1+ (0.2,0) [0|819] "V"  gtw
 SG_ PCS_dcdcUnifiedCommand m7 : 5|10@1+ (0.001,0) [0|1] "1"  X
 SG_ PCS_chgPhCInputIrms m2 : 5|9@1+ (0.1,0) [0|51.1] "A"  gtw
 SG_ PCS_chgPhAIntBusVMin10s m10 : 5|9@1+ (1,0) [0|511] "V"  gtw
 SG_ PCS_dLogPhAChannel4Content m17 : 5|2@1+ (1,0) [0|3] ""  X
 SG_ PCS_chgPhBIntBusVMin10s m11 : 5|9@1+ (1,0) [0|511] "V"  gtw
 SG_ PCS_chgInputL1NVPeak10s m13 : 5|9@1+ (1,0) [0|511] "V"  gtw
 SG_ PCS_dLogPhAChannel1Content m14 : 5|2@1+ (1,0) [0|3] ""  X
 SG_ PCS_chgInputL1NVdc m21 : 5|10@1- (1,0) [-512|511] "V"  gtw
 SG_ PCS_chgPhANoFlowBucket m20 : 5|9@1+ (0.01,0) [0|5.11] "-"  gtw
 SG_ PCS_dcdcPchgStartLvBusVolt m24 : 5|10@1+ (0.0390625,0) [0|40] "V"  gtw
 SG_ PCS_logMessageSelect M : 0|5@1+ (1,0) [0|26] ""  X

BO_ 864 VCLEFT_alertMatrix: 8 VEH
 SG_ VCLEFT_a180_frontDoorLatchRehome m2 : 63|1@1+ (1,0) [0|1] ""  gtw
 SG_ VCLEFT_a300_swcUnderVoltage m4 : 63|1@1+ (1,0) [0|1] ""  gtw
 SG_ VCLEFT_a240_seatHeatShortFront m3 : 63|1@1+ (1,0) [0|1] ""  gtw
 SG_ VCLEFT_a060_engineeringBuild m0 : 63|1@1+ (1,0) [0|1] ""  gtw
 SG_ VCLEFT_a120_DI_DRIVE_MIA m1 : 63|1@1+ (1,0) [0|1] ""  gtw
 SG_ VCLEFT_a239_seatHeatIFront m3 : 62|1@1+ (1,0) [0|1] ""  gtw
 SG_ VCLEFT_a059_inputResistanceHigh m0 : 62|1@1+ (1,0) [0|1] ""  gtw
 SG_ VCLEFT_a119_SCCM_MIA m1 : 62|1@1+ (1,0) [0|1] ""  gtw
 SG_ VCLEFT_a118_VCFRONT_MIA m1 : 61|1@1+ (1,0) [0|1] ""  gtw
 SG_ VCLEFT_a238_lumbarValveMIA m3 : 61|1@1+ (1,0) [0|1] ""  gtw
 SG_ VCLEFT_a117_VCLEFT_MIA m1 : 60|1@1+ (1,0) [0|1] ""  gtw
 SG_ VCLEFT_a237_lumbarOverPresB m3 : 60|1@1+ (1,0) [0|1] ""  gtw
 SG_ VCLEFT_a116_VCRIGHT_MIA m1 : 59|1@1+ (1,0) [0|1] ""  gtw
 SG_ VCLEFT_a236_lumbarOverPresA m3 : 59|1@1+ (1,0) [0|1] ""  gtw
 SG_ VCLEFT_a115_VCSEC_MIA m1 : 58|1@1+ (1,0) [0|1] ""  gtw
 SG_ VCLEFT_a235_seatCurrUnderLift m3 : 58|1@1+ (1,0) [0|1] ""  gtw
 SG_ VCLEFT_a295_buckleFaultedRearL m4 : 58|1@1+ (1,0) [0|1] ""  gtw
 SG_ VCLEFT_a234_seatCurrUnderTilt m3 : 57|1@1+ (1,0) [0|1] ""  gtw
 SG_ VCLEFT_a294_occupancyFaultedRear m4 : 57|1@1+ (1,0) [0|1] ""  gtw
 SG_ VCLEFT_a114_ESP_MIA m1 : 57|1@1+ (1,0) [0|1] ""  gtw
 SG_ VCLEFT_a233_seatCurrUnderBack m3 : 56|1@1+ (1,0) [0|1] ""  gtw
 SG_ VCLEFT_a113_UI_MIA m1 : 56|1@1+ (1,0) [0|1] ""  gtw
 SG_ VCLEFT_a293_occupancyFaultedRear m4 : 56|1@1+ (1,0) [0|1] ""  gtw
 SG_ VCLEFT_a172_SPI_MIA m2 : 55|1@1+ (1,0) [0|1] ""  gtw
 SG_ VCLEFT_a292_occupancyFaultedRear m4 : 55|1@1+ (1,0) [0|1] ""  gtw
 SG_ VCLEFT_a112_EPBL_MIA m1 : 55|1@1+ (1,0) [0|1] ""  gtw
 SG_ VCLEFT_a232_seatCurrUnderTrack m3 : 55|1@1+ (1,0) [0|1] ""  gtw
 SG_ VCLEFT_a291_buckleFaultedFront m4 : 54|1@1+ (1,0) [0|1] ""  gtw
 SG_ VCLEFT_a111_EPBR_MIA m1 : 54|1@1+ (1,0) [0|1] ""  gtw
 SG_ VCLEFT_a231_seatEncOverLift m3 : 54|1@1+ (1,0) [0|1] ""  gtw
 SG_ VCLEFT_a110_GTW_MIA m1 : 53|1@1+ (1,0) [0|1] ""  gtw
 SG_ VCLEFT_a290_occupancyFaultedFron m4 : 53|1@1+ (1,0) [0|1] ""  gtw
 SG_ VCLEFT_a170_windowCurrentPeakR m2 : 53|1@1+ (1,0) [0|1] ""  gtw
 SG_ VCLEFT_a230_seatEncOverTilt m3 : 53|1@1+ (1,0) [0|1] ""  gtw
 SG_ VCLEFT_a109_RCM_MIA m1 : 52|1@1+ (1,0) [0|1] ""  gtw
 SG_ VCLEFT_a229_seatEncOverBack m3 : 52|1@1+ (1,0) [0|1] ""  gtw
 SG_ VCLEFT_a169_windowCurrentPeakF m2 : 52|1@1+ (1,0) [0|1] ""  gtw
 SG_ VCLEFT_a168_windowDebugPinchR m2 : 51|1@1+ (1,0) [0|1] ""  gtw
 SG_ VCLEFT_a228_seatEncOverTrack m3 : 51|1@1+ (1,0) [0|1] ""  gtw
 SG_ VCLEFT_a108_DIS_MIA m1 : 51|1@1+ (1,0) [0|1] ""  gtw
 SG_ VCLEFT_a167_windowDebugPinchF m2 : 50|1@1+ (1,0) [0|1] ""  gtw
 SG_ VCLEFT_a227_seatEncStallLift m3 : 50|1@1+ (1,0) [0|1] ""  gtw
 SG_ VCLEFT_a287_windowSpeedInvalidR m4 : 50|1@1+ (1,0) [0|1] ""  gtw
 SG_ VCLEFT_a107_BMS_MIA m1 : 50|1@1+ (1,0) [0|1] ""  gtw
 SG_ VCLEFT_a226_seatEncStallTilt m3 : 49|1@1+ (1,0) [0|1] ""  gtw
 SG_ VCLEFT_a166_windowDebug m2 : 49|1@1+ (1,0) [0|1] ""  gtw
 SG_ VCLEFT_a286_windowSpeedInvalidF m4 : 49|1@1+ (1,0) [0|1] ""  gtw
 SG_ VCLEFT_a106_PCS_MIA m1 : 49|1@1+ (1,0) [0|1] ""  gtw
 SG_ VCLEFT_a046_Task1000msError m0 : 49|1@1+ (1,0) [0|1] ""  gtw
 SG_ VCLEFT_a165_windowFactoryTest2 m2 : 48|1@1+ (1,0) [0|1] ""  gtw
 SG_ VCLEFT_a105_TAS_MIA m1 : 48|1@1+ (1,0) [0|1] ""  gtw
 SG_ VCLEFT_a285_blowerChipComms m4 : 48|1@1+ (1,0) [0|1] ""  gtw
 SG_ VCLEFT_a225_seatEncStallBack m3 : 48|1@1+ (1,0) [0|1] ""  gtw
 SG_ VCLEFT_a045_Task100msError m0 : 48|1@1+ (1,0) [0|1] ""  gtw
 SG_ VCLEFT_a224_seatEncStallTrack m3 : 47|1@1+ (1,0) [0|1] ""  gtw
 SG_ VCLEFT_a044_Task10msError m0 : 47|1@1+ (1,0) [0|1] ""  gtw
 SG_ VCLEFT_a164_windowFactoryTest m2 : 47|1@1+ (1,0) [0|1] ""  gtw
 SG_ VCLEFT_a104_DAS_MIA m1 : 47|1@1+ (1,0) [0|1] ""  gtw
 SG_ VCLEFT_a284_blowerFbkSanity m4 : 47|1@1+ (1,0) [0|1] ""  gtw
 SG_ VCLEFT_a223_seatCurrStallLift m3 : 46|1@1+ (1,0) [0|1] ""  gtw
 SG_ VCLEFT_a043_Task1msError m0 : 46|1@1+ (1,0) [0|1] ""  gtw
 SG_ VCLEFT_a103_CP_MIA m1 : 46|1@1+ (1,0) [0|1] ""  gtw
 SG_ VCLEFT_a283_latchUnexpectedArmR m4 : 46|1@1+ (1,0) [0|1] ""  gtw
 SG_ VCLEFT_a163_windowEncoderStallR m2 : 46|1@1+ (1,0) [0|1] ""  gtw
 SG_ VCLEFT_a282_latchUnexpectedArmF m4 : 45|1@1+ (1,0) [0|1] ""  gtw
 SG_ VCLEFT_a162_windowEncoderStallF m2 : 45|1@1+ (1,0) [0|1] ""  gtw
 SG_ VCLEFT_a042_HighStackUsage m0 : 45|1@1+ (1,0) [0|1] ""  gtw
 SG_ VCLEFT_a102_PTC_MIA m1 : 45|1@1+ (1,0) [0|1] ""  gtw
 SG_ VCLEFT_a222_seatCurrStallTilt m3 : 45|1@1+ (1,0) [0|1] ""  gtw
 SG_ VCLEFT_a281_latchDidNotDisarmR m4 : 44|1@1+ (1,0) [0|1] ""  gtw
 SG_ VCLEFT_a041_HighCPULoad m0 : 44|1@1+ (1,0) [0|1] ""  gtw
 SG_ VCLEFT_a161_windowUndercurrentR m2 : 44|1@1+ (1,0) [0|1] ""  gtw
 SG_ VCLEFT_a221_seatCurrStallBack m3 : 44|1@1+ (1,0) [0|1] ""  gtw
 SG_ VCLEFT_a101_PM_MIA m1 : 44|1@1+ (1,0) [0|1] ""  gtw
 SG_ VCLEFT_a280_latchDidNotDisarmF m4 : 43|1@1+ (1,0) [0|1] ""  gtw
 SG_ VCLEFT_a220_seatCurrStallTrack m3 : 43|1@1+ (1,0) [0|1] ""  gtw
 SG_ VCLEFT_a160_windowUndercurrentF m2 : 43|1@1+ (1,0) [0|1] ""  gtw
 SG_ VCLEFT_a100_CANbus_MIA m1 : 43|1@1+ (1,0) [0|1] ""  gtw
 SG_ VCLEFT_a279_VCSECUnderVoltage m4 : 42|1@1+ (1,0) [0|1] ""  gtw
 SG_ VCLEFT_a159_windowPinchOverideR m2 : 42|1@1+ (1,0) [0|1] ""  gtw
 SG_ VCLEFT_a219_motorCurrentDropout m3 : 42|1@1+ (1,0) [0|1] ""  gtw
 SG_ VCLEFT_a099_PARK_MIA m1 : 42|1@1+ (1,0) [0|1] ""  gtw
 SG_ VCLEFT_a218_motorDriverFault m3 : 41|1@1+ (1,0) [0|1] ""  gtw
 SG_ VCLEFT_a098_DI_THERMAL_MIA m1 : 41|1@1+ (1,0) [0|1] ""  gtw
 SG_ VCLEFT_a278_BLERearUnderVoltage m4 : 41|1@1+ (1,0) [0|1] ""  gtw
 SG_ VCLEFT_a158_windowPinchOverideF m2 : 41|1@1+ (1,0) [0|1] ""  gtw
 SG_ VCLEFT_a157_windowNoInputRear m2 : 40|1@1+ (1,0) [0|1] ""  gtw
 SG_ VCLEFT_a097_CMP_MIA m1 : 40|1@1+ (1,0) [0|1] ""  gtw
 SG_ VCLEFT_a217_SPI_MIA_debugData2 m3 : 40|1@1+ (1,0) [0|1] ""  gtw
 SG_ VCLEFT_a277_BLELeftUnderVoltage m4 : 40|1@1+ (1,0) [0|1] ""  gtw
 SG_ VCLEFT_a216_SPI_MIA_debugData1 m3 : 39|1@1+ (1,0) [0|1] ""  gtw
 SG_ VCLEFT_a156_windowNoInputFront m2 : 39|1@1+ (1,0) [0|1] ""  gtw
 SG_ VCLEFT_a276_mirrorDebug m4 : 39|1@1+ (1,0) [0|1] ""  gtw
 SG_ VCLEFT_a155_windowThermalRear m2 : 38|1@1+ (1,0) [0|1] ""  gtw
 SG_ VCLEFT_a275_leftTurnLightFault m4 : 38|1@1+ (1,0) [0|1] ""  gtw
 SG_ VCLEFT_a215_currentDesyncWarning m3 : 38|1@1+ (1,0) [0|1] ""  gtw
 SG_ VCLEFT_a154_windowThermalFront m2 : 37|1@1+ (1,0) [0|1] ""  gtw
 SG_ VCLEFT_a274_handleStuckActiveR m4 : 37|1@1+ (1,0) [0|1] ""  gtw
 SG_ VCLEFT_a214_epbmOverIDynNew m3 : 37|1@1+ (1,0) [0|1] ""  gtw
 SG_ VCLEFT_a213_epbmUnderIDynNew m3 : 36|1@1+ (1,0) [0|1] ""  gtw
 SG_ VCLEFT_a273_handleStuckActiveF m4 : 36|1@1+ (1,0) [0|1] ""  gtw
 SG_ VCLEFT_a153_windowUncalRear m2 : 36|1@1+ (1,0) [0|1] ""  gtw
 SG_ VCLEFT_a212_epbmOverIStaticNew m3 : 35|1@1+ (1,0) [0|1] ""  gtw
 SG_ VCLEFT_a272_vhclPwrStateMsmtch m4 : 35|1@1+ (1,0) [0|1] ""  gtw
 SG_ VCLEFT_a152_windowUncalFront m2 : 35|1@1+ (1,0) [0|1] ""  gtw
 SG_ VCLEFT_a031_UDSActive m0 : 34|1@1+ (1,0) [0|1] ""  gtw
 SG_ VCLEFT_a211_epbmUnderIStaticNew m3 : 34|1@1+ (1,0) [0|1] ""  gtw
 SG_ VCLEFT_a151_windowPinchRear m2 : 34|1@1+ (1,0) [0|1] ""  gtw
 SG_ VCLEFT_a270_seatLiftHCEncStlDbg m4 : 33|1@1+ (1,0) [0|1] ""  gtw
 SG_ VCLEFT_a030_ECULogUploadRequest m0 : 33|1@1+ (1,0) [0|1] ""  gtw
 SG_ VCLEFT_a210_epbStateTime m3 : 33|1@1+ (1,0) [0|1] ""  gtw
 SG_ VCLEFT_a150_windowPinchFront m2 : 33|1@1+ (1,0) [0|1] ""  gtw
 SG_ VCLEFT_a209_epbStateMisTime m3 : 32|1@1+ (1,0) [0|1] ""  gtw
 SG_ VCLEFT_a269_seatTiltHCEncStlDbg m4 : 32|1@1+ (1,0) [0|1] ""  gtw
 SG_ VCLEFT_a208_epbFaulted m3 : 31|1@1+ (1,0) [0|1] ""  gtw
 SG_ VCLEFT_a268_seatBackHCEncStlDbg m4 : 31|1@1+ (1,0) [0|1] ""  gtw
 SG_ VCLEFT_a267_seatTrackHCEncStlDbg m4 : 30|1@1+ (1,0) [0|1] ""  gtw
 SG_ VCLEFT_a207_epbmEnableWrong m3 : 30|1@1+ (1,0) [0|1] ""  gtw
 SG_ VCLEFT_a266_seatLiftStallDebug m4 : 29|1@1+ (1,0) [0|1] ""  gtw
 SG_ VCLEFT_a206_epbWrongDirection m3 : 29|1@1+ (1,0) [0|1] ""  gtw
 SG_ VCLEFT_a265_seatTiltStallDebug m4 : 28|1@1+ (1,0) [0|1] ""  gtw
 SG_ VCLEFT_a205_epbmOverIDyn m3 : 28|1@1+ (1,0) [0|1] ""  gtw
 SG_ VCLEFT_a324_mirrorHeatFault m5 : 27|1@1+ (1,0) [0|1] ""  gtw
 SG_ VCLEFT_a204_epbmUnderIDyn m3 : 27|1@1+ (1,0) [0|1] ""  gtw
 SG_ VCLEFT_a264_seatBackStallDebug m4 : 27|1@1+ (1,0) [0|1] ""  gtw
 SG_ VCLEFT_a263_seatTrackStallDebug m4 : 26|1@1+ (1,0) [0|1] ""  gtw
 SG_ VCLEFT_a143_mirrorManuallyFolded m2 : 26|1@1+ (1,0) [0|1] ""  gtw
 SG_ VCLEFT_a323_windowPwrDeriv2RDBG m5 : 26|1@1+ (1,0) [0|1] ""  gtw
 SG_ VCLEFT_a203_epbmOverIStatic m3 : 26|1@1+ (1,0) [0|1] ""  gtw
 SG_ VCLEFT_a022_TaskInitError m0 : 25|1@1+ (1,0) [0|1] ""  gtw
 SG_ VCLEFT_a322_windowPwrDerivRDBG m5 : 25|1@1+ (1,0) [0|1] ""  gtw
 SG_ VCLEFT_a202_epbmUnderIStatic m3 : 25|1@1+ (1,0) [0|1] ""  gtw
 SG_ VCLEFT_a021_TaskSchedulerError m0 : 24|1@1+ (1,0) [0|1] ""  gtw
 SG_ VCLEFT_a201_motorDutyEncDisabl m3 : 24|1@1+ (1,0) [0|1] ""  gtw
 SG_ VCLEFT_a141_12VAuxPowerTrip m2 : 24|1@1+ (1,0) [0|1] ""  gtw
 SG_ VCLEFT_a321_windowPwrDeriv2FDBG m5 : 24|1@1+ (1,0) [0|1] ""  gtw
 SG_ VCLEFT_a140_BLELeftPowerCycled m2 : 23|1@1+ (1,0) [0|1] ""  gtw
 SG_ VCLEFT_a200_motorPhantomEncoder m3 : 23|1@1+ (1,0) [0|1] ""  gtw
 SG_ VCLEFT_a260_latchDisarmDelayR m4 : 23|1@1+ (1,0) [0|1] ""  gtw
 SG_ VCLEFT_a320_windowPwrDerivFDBG m5 : 23|1@1+ (1,0) [0|1] ""  gtw
 SG_ VCLEFT_a259_latchDisarmDelayF m4 : 22|1@1+ (1,0) [0|1] ""  gtw
 SG_ VCLEFT_a139_BLERearPowerCycled m2 : 22|1@1+ (1,0) [0|1] ""  gtw
 SG_ VCLEFT_a138_consoleDoorAssist m2 : 21|1@1+ (1,0) [0|1] ""  gtw
 SG_ VCLEFT_a137_VCSECPowerCycled m2 : 20|1@1+ (1,0) [0|1] ""  gtw
 SG_ VCLEFT_a197_VEHCANUndertrminate m3 : 20|1@1+ (1,0) [0|1] ""  gtw
 SG_ VCLEFT_a196_VEHCANOverterminate m3 : 19|1@1+ (1,0) [0|1] ""  gtw
 SG_ VCLEFT_a136_brakeSwitchMismatch m2 : 19|1@1+ (1,0) [0|1] ""  gtw
 SG_ VCLEFT_a135_SteerColInOutUnCal m2 : 18|1@1+ (1,0) [0|1] ""  gtw
 SG_ VCLEFT_a015_NVMMAlert m0 : 18|1@1+ (1,0) [0|1] ""  gtw
 SG_ VCLEFT_a134_SteerColUpDownUnCal m2 : 17|1@1+ (1,0) [0|1] ""  gtw
 SG_ VCLEFT_a254_seatUncalLift m4 : 17|1@1+ (1,0) [0|1] ""  gtw
 SG_ VCLEFT_a253_seatUncalTilt m4 : 16|1@1+ (1,0) [0|1] ""  gtw
 SG_ VCLEFT_a133_blowerLowRPMCBang m2 : 16|1@1+ (1,0) [0|1] ""  gtw
 SG_ VCLEFT_a013_AlertManagerFault m0 : 16|1@1+ (1,0) [0|1] ""  gtw
 SG_ VCLEFT_a132_blowerSoftStall m2 : 15|1@1+ (1,0) [0|1] ""  gtw
 SG_ VCLEFT_a252_seatUncalBack m4 : 15|1@1+ (1,0) [0|1] ""  gtw
 SG_ VCLEFT_a012_CPUReset m0 : 15|1@1+ (1,0) [0|1] ""  gtw
 SG_ VCLEFT_a251_seatUncalTrack m4 : 14|1@1+ (1,0) [0|1] ""  gtw
 SG_ VCLEFT_a191_TLCOvercurrent m3 : 14|1@1+ (1,0) [0|1] ""  gtw
 SG_ VCLEFT_a131_blowerICTransFault m2 : 14|1@1+ (1,0) [0|1] ""  gtw
 SG_ VCLEFT_a190_eFuseMgmtVbatFused m3 : 13|1@1+ (1,0) [0|1] ""  gtw
 SG_ VCLEFT_a310_mirrorFoldStall m5 : 13|1@1+ (1,0) [0|1] ""  gtw
 SG_ VCLEFT_a010_ExtSupplyVoltError m0 : 13|1@1+ (1,0) [0|1] ""  gtw
 SG_ VCLEFT_a130_blowerICWarning m2 : 13|1@1+ (1,0) [0|1] ""  gtw
 SG_ VCLEFT_a309_brakeSwitchFaulted m5 : 12|1@1+ (1,0) [0|1] ""  gtw
 SG_ VCLEFT_a129_blowerICLatchFault m2 : 12|1@1+ (1,0) [0|1] ""  gtw
 SG_ VCLEFT_a189_latchUnableToRearmR m3 : 12|1@1+ (1,0) [0|1] ""  gtw
 SG_ VCLEFT_a188_latchUnableToRearmF m3 : 11|1@1+ (1,0) [0|1] ""  gtw
 SG_ VCLEFT_a308_sirenMIA m5 : 11|1@1+ (1,0) [0|1] ""  gtw
 SG_ VCLEFT_a187_latchReleaseFailedR m3 : 10|1@1+ (1,0) [0|1] ""  gtw
 SG_ VCLEFT_a307_handleDisconnectedR m5 : 10|1@1+ (1,0) [0|1] ""  gtw
 SG_ VCLEFT_a186_latchReleaseFailedF m3 : 9|1@1+ (1,0) [0|1] ""  gtw
 SG_ VCLEFT_a306_handleDisconnectedF m5 : 9|1@1+ (1,0) [0|1] ""  gtw
 SG_ VCLEFT_a185_summonAborted m3 : 8|1@1+ (1,0) [0|1] ""  gtw
 SG_ VCLEFT_a305_rearIntHandleShorted m5 : 8|1@1+ (1,0) [0|1] ""  gtw
 SG_ VCLEFT_a304_frontIntHandleShorte m5 : 7|1@1+ (1,0) [0|1] ""  gtw
 SG_ VCLEFT_a064_busSleepReqTimeout m1 : 7|1@1+ (1,0) [0|1] ""  gtw
 SG_ VCLEFT_a244_seatHeatMIARearL m4 : 7|1@1+ (1,0) [0|1] ""  gtw
 SG_ VCLEFT_a003_SWAssertion m0 : 6|1@1+ (1,0) [0|1] ""  gtw
 SG_ VCLEFT_a063_SwitchFault m1 : 6|1@1+ (1,0) [0|1] ""  gtw
 SG_ VCLEFT_a303_eFuseMgmtWindowLift m5 : 6|1@1+ (1,0) [0|1] ""  gtw
 SG_ VCLEFT_a183_doorStateFactoryTest m3 : 6|1@1+ (1,0) [0|1] ""  gtw
 SG_ VCLEFT_a243_seatHeatShortRearL m4 : 6|1@1+ (1,0) [0|1] ""  gtw
 SG_ VCLEFT_a302_blowerGeneralFault m5 : 5|1@1+ (1,0) [0|1] ""  gtw
 SG_ VCLEFT_a182_emergencyLatchRel m3 : 5|1@1+ (1,0) [0|1] ""  gtw
 SG_ VCLEFT_a002_PowerLossReset m0 : 5|1@1+ (1,0) [0|1] ""  gtw
 SG_ VCLEFT_a242_seatHeatIRearL m4 : 5|1@1+ (1,0) [0|1] ""  gtw
 SG_ VCLEFT_a062_XCPWasConnected m1 : 5|1@1+ (1,0) [0|1] ""  gtw
 SG_ VCLEFT_a001_WatchdogReset m0 : 4|1@1+ (1,0) [0|1] ""  gtw
 SG_ VCLEFT_a241_seatHeatMIAFront m4 : 4|1@1+ (1,0) [0|1] ""  gtw
 SG_ VCLEFT_a061_XCPConnected m1 : 4|1@1+ (1,0) [0|1] ""  gtw
 SG_ VCLEFT_a301_swcOverVoltage m5 : 4|1@1+ (1,0) [0|1] ""  gtw
 SG_ VCLEFT_a181_rearDoorLatchRehome m3 : 4|1@1+ (1,0) [0|1] ""  gtw
 SG_ VCLEFT_matrixIndex M : 0|4@1+ (1,0) [0|15] ""  gtw

BO_ 1930 HVP_pyroDeviceDbg: 8 VEH
 SG_ HVP_pyroAoutVst2 m1 : 48|16@1+ (0.001,0) [0|65.535] "V"  dbg
 SG_ HVP_pyroAoutIGH1 m4 : 48|16@1+ (0.001,0) [0|65.535] "V"  dbg
 SG_ HVP_pyroAoutEr2 m3 : 48|16@1+ (0.001,0) [0|65.535] "V"  dbg
 SG_ HVP_pyroAoutRmVoltage m7 : 48|16@1+ (0.001,0) [0|65.535] "V"  dbg
 SG_ HVP_pyroAoutIGL1 m5 : 48|16@1+ (0.001,0) [0|65.535] "V"  dbg
 SG_ HVP_pyroAoutRrefVoltage m8 : 48|16@1+ (0.001,0) [0|65.535] "V"  dbg
 SG_ HVP_pyroAoutVst1 m0 : 48|16@1+ (0.001,0) [0|65.535] "V"  dbg
 SG_ HVP_pyroAoutGnd m6 : 48|16@1+ (0.001,0) [0|65.535] "V"  dbg
 SG_ HVP_pyroAoutEr1 m2 : 48|16@1+ (0.001,0) [0|65.535] "V"  dbg
 SG_ HVP_pyroAoutMultiplexer M : 36|4@1+ (1,0) [0|8] ""  dbg
 SG_ HVP_pyroFiringHandle : 32|4@1+ (1,0) [1|12] ""  dbg
 SG_ HVP_pyroSquibResistance : 16|16@1+ (0.001,0) [0|65.535] "Ohm"  dbg
 SG_ HVP_pyroSquibFired : 9|1@1+ (1,0) [0|1] ""  dbg
 SG_ HVP_pyroTestSquibLeakFailed : 8|1@1+ (1,0) [0|1] ""  dbg
 SG_ HVP_pyroTestLowSideLeakFailed : 7|1@1+ (1,0) [0|1] ""  dbg
 SG_ HVP_pyroTestHighSideLeakFailed : 6|1@1+ (1,0) [0|1] ""  dbg
 SG_ HVP_pyroTestVstFailed : 5|1@1+ (1,0) [0|1] ""  dbg
 SG_ HVP_pyroTestErFailed : 4|1@1+ (1,0) [0|1] ""  dbg
 SG_ HVP_pyroTestSquibResFailed : 3|1@1+ (1,0) [0|1] ""  dbg
 SG_ HVP_pyroTestRefCurrentFailed : 2|1@1+ (1,0) [0|1] ""  dbg
 SG_ HVP_pyroStatus : 0|2@1+ (1,0) [0|3] ""  dbg

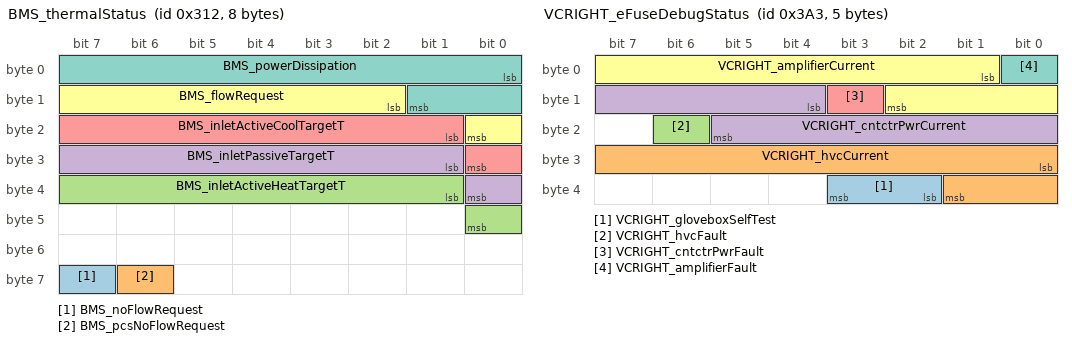
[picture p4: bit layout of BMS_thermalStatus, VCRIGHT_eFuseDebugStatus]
BO_ 786 BMS_thermalStatus: 8 VEH
 SG_ BMS_noFlowRequest : 63|1@1+ (1,0) [0|1] ""  vcfront
 SG_ BMS_pcsNoFlowRequest : 62|1@1+ (1,0) [0|1] ""  vcfront
 SG_ BMS_inletActiveHeatTargetT : 33|8@1+ (0.25,-25) [-25|38.75] "DegC"  gtw
 SG_ BMS_inletPassiveTargetT : 25|8@1+ (0.25,0) [0|63.75] "DegC"  gtw
 SG_ BMS_inletActiveCoolTargetT : 17|8@1+ (0.25,10) [10|73.75] "DegC"  gtw
 SG_ BMS_flowRequest : 10|7@1+ (0.3,0) [0|30] "LPM"  gtw
 SG_ BMS_powerDissipation : 0|10@1+ (0.02,0) [0|20] "kW"  gtw

BO_ 1931 EPBL_xcpResponse: 8 VEH
 SG_ EPBL_xcpResponse : 7|64@0+ (1,0) [0|18446744073709551615] ""  X

BO_ 931 VCRIGHT_eFuseDebugStatus: 5 VEH
 SG_ VCRIGHT_gloveboxSelfTest : 34|2@1+ (1,0) [0|3] ""  gtw
 SG_ VCRIGHT_hvcCurrent : 24|10@1+ (0.1,0) [0|102.3] "A"  X
 SG_ VCRIGHT_hvcFault : 22|1@1+ (1,0) [0|1] ""  X
 SG_ VCRIGHT_cntctrPwrCurrent : 12|10@1+ (0.1,0) [0|102.3] "A"  X
 SG_ VCRIGHT_cntctrPwrFault : 11|1@1+ (1,0) [0|1] ""  X
 SG_ VCRIGHT_amplifierCurrent : 1|10@1+ (0.1,0) [0|102.3] "A"  X
 SG_ VCRIGHT_amplifierFault : 0|1@1+ (1,0) [0|1] ""  X

BO_ 12 UI_status: 7 VEH
 SG_ UI_cameraActive : 49|1@1+ (1,0) [0|1] ""  X
 SG_ UI_developmentCar : 48|1@1+ (1,0) [0|1] ""  bms
 SG_ UI_falseTouchCounter : 40|8@1+ (1,0) [0|255] "1"  X
 SG_ UI_cellReceiverPower : 32|8@1+ (1,-128) [-128|127] "dB"  X
 SG_ UI_cellSignalBars : 24|3@1+ (1,0) [0|7] ""  X
 SG_ UI_cellNetworkTechnology : 19|4@1+ (1,0) [0|15] ""  X
 SG_ UI_radioActive : 18|1@1+ (1,0) [0|1] ""  X
 SG_ UI_screenshotActive : 17|1@1+ (1,0) [0|1] ""  X
 SG_ UI_gpsActive : 16|1@1+ (1,0) [0|1] ""  X
 SG_ UI_factoryReset : 14|2@1+ (1,0) [0|3] ""  X
 SG_ UI_autopilotTrial : 12|2@1+ (1,0) [0|3] ""  X
 SG_ UI_vpnActive : 11|1@1+ (1,0) [0|1] ""  X
 SG_ UI_cellConnected : 10|1@1+ (1,0) [0|1] ""  X
 SG_ UI_readyForDrive : 9|1@1+ (1,0) [0|1] ""  X
 SG_ UI_systemActive : 8|1@1+ (1,0) [0|1] ""  X
 SG_ UI_wifiConnected : 7|1@1+ (1,0) [0|1] ""  X
 SG_ UI_wifiActive : 6|1@1+ (1,0) [0|1] ""  X
 SG_ UI_displayOn : 5|1@1+ (1,0) [0|1] ""  X
 SG_ UI_displayReady : 4|1@1+ (1,0) [0|1] ""  X
 SG_ UI_cellActive : 3|1@1+ (1,0) [0|1] ""  X
 SG_ UI_bluetoothActive : 2|1@1+ (1,0) [0|1] ""  X
 SG_ UI_audioActive : 1|1@1+ (1,0) [0|1] ""  X
 SG_ UI_touchActive : 0|1@1+ (1,0) [0|1] ""  X

BO_ 1023 APS_selfTest: 8 VEH
 SG_ APS_selfTestReserved : 0|64@1+ (1,0) [0|18446744073709551615] ""  X

BO_ 960 VCRIGHT_alertMatrix: 8 VEH
 SG_ VCRIGHT_a180_frontDoorLatchRehom m2 : 63|1@1+ (1,0) [0|1] ""  gtw
 SG_ VCRIGHT_a060_engineeringBuild m0 : 63|1@1+ (1,0) [0|1] ""  gtw
 SG_ VCRIGHT_a120_DI_DRIVE_MIA m1 : 63|1@1+ (1,0) [0|1] ""  gtw
 SG_ VCRIGHT_a240_seatHeatShortFront m3 : 63|1@1+ (1,0) [0|1] ""  gtw
 SG_ VCRIGHT_a059_inputResistanceHigh m0 : 62|1@1+ (1,0) [0|1] ""  gtw
 SG_ VCRIGHT_a239_seatHeatIFront m3 : 62|1@1+ (1,0) [0|1] ""  gtw
 SG_ VCRIGHT_a119_SCCM_MIA m1 : 62|1@1+ (1,0) [0|1] ""  gtw
 SG_ VCRIGHT_a238_lumbarValveMIA m3 : 61|1@1+ (1,0) [0|1] ""  gtw
 SG_ VCRIGHT_a118_VCFRONT_MIA m1 : 61|1@1+ (1,0) [0|1] ""  gtw
 SG_ VCRIGHT_a237_lumbarOverPresB m3 : 60|1@1+ (1,0) [0|1] ""  gtw
 SG_ VCRIGHT_a117_VCLEFT_MIA m1 : 60|1@1+ (1,0) [0|1] ""  gtw
 SG_ VCRIGHT_a116_VCRIGHT_MIA m1 : 59|1@1+ (1,0) [0|1] ""  gtw
 SG_ VCRIGHT_a236_lumbarOverPresA m3 : 59|1@1+ (1,0) [0|1] ""  gtw
 SG_ VCRIGHT_a235_seatCurrUnderLift m3 : 58|1@1+ (1,0) [0|1] ""  gtw
 SG_ VCRIGHT_a115_VCSEC_MIA m1 : 58|1@1+ (1,0) [0|1] ""  gtw
 SG_ VCRIGHT_a174_BLERightPowerCycled m2 : 57|1@1+ (1,0) [0|1] ""  gtw
 SG_ VCRIGHT_a114_ESP_MIA m1 : 57|1@1+ (1,0) [0|1] ""  gtw
 SG_ VCRIGHT_a234_seatCurrUnderTilt m3 : 57|1@1+ (1,0) [0|1] ""  gtw
 SG_ VCRIGHT_a293_buckleFaultedRearR m4 : 56|1@1+ (1,0) [0|1] ""  gtw
 SG_ VCRIGHT_a113_UI_MIA m1 : 56|1@1+ (1,0) [0|1] ""  gtw
 SG_ VCRIGHT_a233_seatCurrUnderBack m3 : 56|1@1+ (1,0) [0|1] ""  gtw
 SG_ VCRIGHT_a232_seatCurrUnderTrack m3 : 55|1@1+ (1,0) [0|1] ""  gtw
 SG_ VCRIGHT_a112_EPBL_MIA m1 : 55|1@1+ (1,0) [0|1] ""  gtw
 SG_ VCRIGHT_a172_SPI_MIA m2 : 55|1@1+ (1,0) [0|1] ""  gtw
 SG_ VCRIGHT_a292_buckleFaultedRearC m4 : 55|1@1+ (1,0) [0|1] ""  gtw
 SG_ VCRIGHT_a291_buckleFaultedFront m4 : 54|1@1+ (1,0) [0|1] ""  gtw
 SG_ VCRIGHT_a231_seatEncOverLift m3 : 54|1@1+ (1,0) [0|1] ""  gtw
 SG_ VCRIGHT_a111_EPBR_MIA m1 : 54|1@1+ (1,0) [0|1] ""  gtw
 SG_ VCRIGHT_a290_occupancyFaultedFro m4 : 53|1@1+ (1,0) [0|1] ""  gtw
 SG_ VCRIGHT_a230_seatEncOverTilt m3 : 53|1@1+ (1,0) [0|1] ""  gtw
 SG_ VCRIGHT_a170_windowCurrentPeakR m2 : 53|1@1+ (1,0) [0|1] ""  gtw
 SG_ VCRIGHT_a110_GTW_MIA m1 : 53|1@1+ (1,0) [0|1] ""  gtw
 SG_ VCRIGHT_a169_windowCurrentPeakF m2 : 52|1@1+ (1,0) [0|1] ""  gtw
 SG_ VCRIGHT_a229_seatEncOverBack m3 : 52|1@1+ (1,0) [0|1] ""  gtw
 SG_ VCRIGHT_a109_RCM_MIA m1 : 52|1@1+ (1,0) [0|1] ""  gtw
 SG_ VCRIGHT_a108_DIS_MIA m1 : 51|1@1+ (1,0) [0|1] ""  gtw
 SG_ VCRIGHT_a228_seatEncOverTrack m3 : 51|1@1+ (1,0) [0|1] ""  gtw
 SG_ VCRIGHT_a168_windowDebugPinchR m2 : 51|1@1+ (1,0) [0|1] ""  gtw
 SG_ VCRIGHT_a287_windowSpeedInvalidR m4 : 50|1@1+ (1,0) [0|1] ""  gtw
 SG_ VCRIGHT_a227_seatEncStallLift m3 : 50|1@1+ (1,0) [0|1] ""  gtw
 SG_ VCRIGHT_a107_BMS_MIA m1 : 50|1@1+ (1,0) [0|1] ""  gtw
 SG_ VCRIGHT_a167_windowDebugPinchF m2 : 50|1@1+ (1,0) [0|1] ""  gtw
 SG_ VCRIGHT_a106_PCS_MIA m1 : 49|1@1+ (1,0) [0|1] ""  gtw
 SG_ VCRIGHT_a226_seatEncStallTilt m3 : 49|1@1+ (1,0) [0|1] ""  gtw
 SG_ VCRIGHT_a046_Task1000msError m0 : 49|1@1+ (1,0) [0|1] ""  gtw
 SG_ VCRIGHT_a166_windowDebug m2 : 49|1@1+ (1,0) [0|1] ""  gtw
 SG_ VCRIGHT_a286_windowSpeedInvalidF m4 : 49|1@1+ (1,0) [0|1] ""  gtw
 SG_ VCRIGHT_a165_windowFactoryTest2 m2 : 48|1@1+ (1,0) [0|1] ""  gtw
 SG_ VCRIGHT_a045_Task100msError m0 : 48|1@1+ (1,0) [0|1] ""  gtw
 SG_ VCRIGHT_a225_seatEncStallBack m3 : 48|1@1+ (1,0) [0|1] ""  gtw
 SG_ VCRIGHT_a105_TAS_MIA m1 : 48|1@1+ (1,0) [0|1] ""  gtw
 SG_ VCRIGHT_a044_Task10msError m0 : 47|1@1+ (1,0) [0|1] ""  gtw
 SG_ VCRIGHT_a164_windowFactoryTest m2 : 47|1@1+ (1,0) [0|1] ""  gtw
 SG_ VCRIGHT_a104_DAS_MIA m1 : 47|1@1+ (1,0) [0|1] ""  gtw
 SG_ VCRIGHT_a224_seatEncStallTrack m3 : 47|1@1+ (1,0) [0|1] ""  gtw
 SG_ VCRIGHT_a043_Task1msError m0 : 46|1@1+ (1,0) [0|1] ""  gtw
 SG_ VCRIGHT_a103_CP_MIA m1 : 46|1@1+ (1,0) [0|1] ""  gtw
 SG_ VCRIGHT_a163_windowEncoderStallR m2 : 46|1@1+ (1,0) [0|1] ""  gtw
 SG_ VCRIGHT_a283_latchUnexpectedArmR m4 : 46|1@1+ (1,0) [0|1] ""  gtw
 SG_ VCRIGHT_a223_seatCurrStallLift m3 : 46|1@1+ (1,0) [0|1] ""  gtw
 SG_ VCRIGHT_a222_seatCurrStallTilt m3 : 45|1@1+ (1,0) [0|1] ""  gtw
 SG_ VCRIGHT_a102_PTC_MIA m1 : 45|1@1+ (1,0) [0|1] ""  gtw
 SG_ VCRIGHT_a042_HighStackUsage m0 : 45|1@1+ (1,0) [0|1] ""  gtw
 SG_ VCRIGHT_a162_windowEncoderStallF m2 : 45|1@1+ (1,0) [0|1] ""  gtw
 SG_ VCRIGHT_a282_latchUnexpectedArmF m4 : 45|1@1+ (1,0) [0|1] ""  gtw
 SG_ VCRIGHT_a281_latchDidNotDisarmR m4 : 44|1@1+ (1,0) [0|1] ""  gtw
 SG_ VCRIGHT_a101_PM_MIA m1 : 44|1@1+ (1,0) [0|1] ""  gtw
 SG_ VCRIGHT_a161_windowUndercurrentR m2 : 44|1@1+ (1,0) [0|1] ""  gtw
 SG_ VCRIGHT_a221_seatCurrStallBack m3 : 44|1@1+ (1,0) [0|1] ""  gtw
 SG_ VCRIGHT_a041_HighCPULoad m0 : 44|1@1+ (1,0) [0|1] ""  gtw
 SG_ VCRIGHT_a160_windowUndercurrentF m2 : 43|1@1+ (1,0) [0|1] ""  gtw
 SG_ VCRIGHT_a280_latchDidNotDisarmF m4 : 43|1@1+ (1,0) [0|1] ""  gtw
 SG_ VCRIGHT_a220_seatCurrStallTrack m3 : 43|1@1+ (1,0) [0|1] ""  gtw
 SG_ VCRIGHT_a100_CANbus_MIA m1 : 43|1@1+ (1,0) [0|1] ""  gtw
 SG_ VCRIGHT_a099_PARK_MIA m1 : 42|1@1+ (1,0) [0|1] ""  gtw
 SG_ VCRIGHT_a219_motorCurrentDropout m3 : 42|1@1+ (1,0) [0|1] ""  gtw
 SG_ VCRIGHT_a159_windowPinchOverideR m2 : 42|1@1+ (1,0) [0|1] ""  gtw
 SG_ VCRIGHT_a278_hvacPtcHeatingUnava m4 : 41|1@1+ (1,0) [0|1] ""  gtw
 SG_ VCRIGHT_a218_motorDriverFault m3 : 41|1@1+ (1,0) [0|1] ""  gtw
 SG_ VCRIGHT_a158_windowPinchOverideF m2 : 41|1@1+ (1,0) [0|1] ""  gtw
 SG_ VCRIGHT_a098_DI_THERMAL_MIA m1 : 41|1@1+ (1,0) [0|1] ""  gtw
 SG_ VCRIGHT_a097_CMP_MIA m1 : 40|1@1+ (1,0) [0|1] ""  gtw
 SG_ VCRIGHT_a277_BLERightUnderVoltag m4 : 40|1@1+ (1,0) [0|1] ""  gtw
 SG_ VCRIGHT_a217_SPI_MIA_debugData2 m3 : 40|1@1+ (1,0) [0|1] ""  gtw
 SG_ VCRIGHT_a157_windowNoInputRear m2 : 40|1@1+ (1,0) [0|1] ""  gtw
 SG_ VCRIGHT_a156_windowNoInputFront m2 : 39|1@1+ (1,0) [0|1] ""  gtw
 SG_ VCRIGHT_a216_SPI_MIA_debugData1 m3 : 39|1@1+ (1,0) [0|1] ""  gtw
 SG_ VCRIGHT_a276_mirrorDebug m4 : 39|1@1+ (1,0) [0|1] ""  gtw
 SG_ VCRIGHT_a155_windowThermalRear m2 : 38|1@1+ (1,0) [0|1] ""  gtw
 SG_ VCRIGHT_a275_rightTurnLightFault m4 : 38|1@1+ (1,0) [0|1] ""  gtw
 SG_ VCRIGHT_a215_currentDesyncWarnin m3 : 38|1@1+ (1,0) [0|1] ""  gtw
 SG_ VCRIGHT_a274_handleStuckActiveR m4 : 37|1@1+ (1,0) [0|1] ""  gtw
 SG_ VCRIGHT_a154_windowThermalFront m2 : 37|1@1+ (1,0) [0|1] ""  gtw
 SG_ VCRIGHT_a214_epbmOverIDynNew m3 : 37|1@1+ (1,0) [0|1] ""  gtw
 SG_ VCRIGHT_a273_handleStuckActiveF m4 : 36|1@1+ (1,0) [0|1] ""  gtw
 SG_ VCRIGHT_a213_epbmUnderIDynNew m3 : 36|1@1+ (1,0) [0|1] ""  gtw
 SG_ VCRIGHT_a153_windowUncalRear m2 : 36|1@1+ (1,0) [0|1] ""  gtw
 SG_ VCRIGHT_a272_vhclPwrStateMsmtch m4 : 35|1@1+ (1,0) [0|1] ""  gtw
 SG_ VCRIGHT_a212_epbmOverIStaticNew m3 : 35|1@1+ (1,0) [0|1] ""  gtw
 SG_ VCRIGHT_a152_windowUncalFront m2 : 35|1@1+ (1,0) [0|1] ""  gtw
 SG_ VCRIGHT_a271_THSSensorFault m4 : 34|1@1+ (1,0) [0|1] ""  gtw
 SG_ VCRIGHT_a211_epbmUnderIStaticNew m3 : 34|1@1+ (1,0) [0|1] ""  gtw
 SG_ VCRIGHT_a031_UDSActive m0 : 34|1@1+ (1,0) [0|1] ""  gtw
 SG_ VCRIGHT_a151_windowPinchRear m2 : 34|1@1+ (1,0) [0|1] ""  gtw
 SG_ VCRIGHT_a030_ECULogUploadRequest m0 : 33|1@1+ (1,0) [0|1] ""  gtw
 SG_ VCRIGHT_a150_windowPinchFront m2 : 33|1@1+ (1,0) [0|1] ""  gtw
 SG_ VCRIGHT_a210_epbStateTime m3 : 33|1@1+ (1,0) [0|1] ""  gtw
 SG_ VCRIGHT_a270_seatLiftHCEncStlDbg m4 : 33|1@1+ (1,0) [0|1] ""  gtw
 SG_ VCRIGHT_a149_incarDeepTempSns m2 : 32|1@1+ (1,0) [0|1] ""  gtw
 SG_ VCRIGHT_a269_seatTiltHCEncStlDbg m4 : 32|1@1+ (1,0) [0|1] ""  gtw
 SG_ VCRIGHT_a209_epbStateMisTime m3 : 32|1@1+ (1,0) [0|1] ""  gtw
 SG_ VCRIGHT_a268_seatBackHCEncStlDbg m4 : 31|1@1+ (1,0) [0|1] ""  gtw
 SG_ VCRIGHT_a208_epbFaulted m3 : 31|1@1+ (1,0) [0|1] ""  gtw
 SG_ VCRIGHT_a148_incarMidTempSns m2 : 31|1@1+ (1,0) [0|1] ""  gtw
 SG_ VCRIGHT_a267_seatTrackHCEncStlDb m4 : 30|1@1+ (1,0) [0|1] ""  gtw
 SG_ VCRIGHT_a147_incarProbeTempSns m2 : 30|1@1+ (1,0) [0|1] ""  gtw
 SG_ VCRIGHT_a207_epbmEnableWrong m3 : 30|1@1+ (1,0) [0|1] ""  gtw
 SG_ VCRIGHT_a206_epbWrongDirection m3 : 29|1@1+ (1,0) [0|1] ""  gtw
 SG_ VCRIGHT_a146_ductRightTempSns m2 : 29|1@1+ (1,0) [0|1] ""  gtw
 SG_ VCRIGHT_a266_seatLiftStallDebug m4 : 29|1@1+ (1,0) [0|1] ""  gtw
 SG_ VCRIGHT_a205_epbmOverIDyn m3 : 28|1@1+ (1,0) [0|1] ""  gtw
 SG_ VCRIGHT_a265_seatTiltStallDebug m4 : 28|1@1+ (1,0) [0|1] ""  gtw
 SG_ VCRIGHT_a145_ductLeftTempSns m2 : 28|1@1+ (1,0) [0|1] ""  gtw
 SG_ VCRIGHT_a204_epbmUnderIDyn m3 : 27|1@1+ (1,0) [0|1] ""  gtw
 SG_ VCRIGHT_a264_seatBackStallDebug m4 : 27|1@1+ (1,0) [0|1] ""  gtw
 SG_ VCRIGHT_a144_evaporatorTempSns m2 : 27|1@1+ (1,0) [0|1] ""  gtw
 SG_ VCRIGHT_a324_mirrorHeatFault m5 : 27|1@1+ (1,0) [0|1] ""  gtw
 SG_ VCRIGHT_a203_epbmOverIStatic m3 : 26|1@1+ (1,0) [0|1] ""  gtw
 SG_ VCRIGHT_a323_windowPwrDeriv2RDBG m5 : 26|1@1+ (1,0) [0|1] ""  gtw
 SG_ VCRIGHT_a143_mirrorManuallyFolde m2 : 26|1@1+ (1,0) [0|1] ""  gtw
 SG_ VCRIGHT_a263_seatTrackStallDebug m4 : 26|1@1+ (1,0) [0|1] ""  gtw
 SG_ VCRIGHT_a322_windowPwrDerivRDBG m5 : 25|1@1+ (1,0) [0|1] ""  gtw
 SG_ VCRIGHT_a262_PTCFaulted m4 : 25|1@1+ (1,0) [0|1] ""  gtw
 SG_ VCRIGHT_a022_TaskInitError m0 : 25|1@1+ (1,0) [0|1] ""  gtw
 SG_ VCRIGHT_a142_hvacLowerModeFault m2 : 25|1@1+ (1,0) [0|1] ""  gtw
 SG_ VCRIGHT_a202_epbmUnderIStatic m3 : 25|1@1+ (1,0) [0|1] ""  gtw
 SG_ VCRIGHT_a201_motorDutyEncDisabl m3 : 24|1@1+ (1,0) [0|1] ""  gtw
 SG_ VCRIGHT_a321_windowPwrDeriv2FDBG m5 : 24|1@1+ (1,0) [0|1] ""  gtw
 SG_ VCRIGHT_a021_TaskSchedulerError m0 : 24|1@1+ (1,0) [0|1] ""  gtw
 SG_ VCRIGHT_a141_hvacUpperModeFault m2 : 24|1@1+ (1,0) [0|1] ""  gtw
 SG_ VCRIGHT_a140_hvacRHVaneFault m2 : 23|1@1+ (1,0) [0|1] ""  gtw
 SG_ VCRIGHT_a200_motorPhantomEncoder m3 : 23|1@1+ (1,0) [0|1] ""  gtw
 SG_ VCRIGHT_a260_latchDisarmDelayR m4 : 23|1@1+ (1,0) [0|1] ""  gtw
 SG_ VCRIGHT_a320_windowPwrDerivFDBG m5 : 23|1@1+ (1,0) [0|1] ""  gtw
 SG_ VCRIGHT_a199_PRVCANUndertrminate m3 : 22|1@1+ (1,0) [0|1] ""  gtw
 SG_ VCRIGHT_a139_hvacLHVaneFault m2 : 22|1@1+ (1,0) [0|1] ""  gtw
 SG_ VCRIGHT_a259_latchDisarmDelayF m4 : 22|1@1+ (1,0) [0|1] ""  gtw
 SG_ VCRIGHT_a198_PRVCANOverterminate m3 : 21|1@1+ (1,0) [0|1] ""  gtw
 SG_ VCRIGHT_a258_PTCStuckInBoot m4 : 21|1@1+ (1,0) [0|1] ""  gtw
 SG_ VCRIGHT_a138_hvacRHBleedFault m2 : 21|1@1+ (1,0) [0|1] ""  gtw
 SG_ VCRIGHT_a137_hvacLHBleedFault m2 : 20|1@1+ (1,0) [0|1] ""  gtw
 SG_ VCRIGHT_a197_VEHCANUndertrminate m3 : 20|1@1+ (1,0) [0|1] ""  gtw
 SG_ VCRIGHT_a257_THSMIA m4 : 20|1@1+ (1,0) [0|1] ""  gtw
 SG_ VCRIGHT_a256_PTCCurrentDrawNoReq m4 : 19|1@1+ (1,0) [0|1] ""  gtw
 SG_ VCRIGHT_a196_VEHCANOverterminate m3 : 19|1@1+ (1,0) [0|1] ""  gtw
 SG_ VCRIGHT_a136_hvacIntakeFault m2 : 19|1@1+ (1,0) [0|1] ""  gtw
 SG_ VCRIGHT_a135_hvacLowrModeUncalib m2 : 18|1@1+ (1,0) [0|1] ""  gtw
 SG_ VCRIGHT_a015_NVMMAlert m0 : 18|1@1+ (1,0) [0|1] ""  gtw
 SG_ VCRIGHT_a195_hvcEFuseFault m3 : 18|1@1+ (1,0) [0|1] ""  gtw
 SG_ VCRIGHT_a255_PTCOverTemp m4 : 18|1@1+ (1,0) [0|1] ""  gtw
 SG_ VCRIGHT_a254_seatUncalLift m4 : 17|1@1+ (1,0) [0|1] ""  gtw
 SG_ VCRIGHT_a194_cntctrPwrEFuseFault m3 : 17|1@1+ (1,0) [0|1] ""  gtw
 SG_ VCRIGHT_a134_hvacUpprModeUncalib m2 : 17|1@1+ (1,0) [0|1] ""  gtw
 SG_ VCRIGHT_a013_AlertManagerFault m0 : 16|1@1+ (1,0) [0|1] ""  gtw
 SG_ VCRIGHT_a133_hvacRHVaneUncalib m2 : 16|1@1+ (1,0) [0|1] ""  gtw
 SG_ VCRIGHT_a253_seatUncalTilt m4 : 16|1@1+ (1,0) [0|1] ""  gtw
 SG_ VCRIGHT_a193_amplifierEFuseFault m3 : 16|1@1+ (1,0) [0|1] ""  gtw
 SG_ VCRIGHT_a132_hvacLHVaneUncalib m2 : 15|1@1+ (1,0) [0|1] ""  gtw
 SG_ VCRIGHT_a252_seatUncalBack m4 : 15|1@1+ (1,0) [0|1] ""  gtw
 SG_ VCRIGHT_a192_gloveboxLatchRel m3 : 15|1@1+ (1,0) [0|1] ""  gtw
 SG_ VCRIGHT_a012_CPUReset m0 : 15|1@1+ (1,0) [0|1] ""  gtw
 SG_ VCRIGHT_a251_seatUncalTrack m4 : 14|1@1+ (1,0) [0|1] ""  gtw
 SG_ VCRIGHT_a191_gloveboxPower m3 : 14|1@1+ (1,0) [0|1] ""  gtw
 SG_ VCRIGHT_a131_hvacRHBleedUncalib m2 : 14|1@1+ (1,0) [0|1] ""  gtw
 SG_ VCRIGHT_a010_ExtSupplyVoltError m0 : 13|1@1+ (1,0) [0|1] ""  gtw
 SG_ VCRIGHT_a250_seatHeatMIARearR m4 : 13|1@1+ (1,0) [0|1] ""  gtw
 SG_ VCRIGHT_a310_mirrorFoldStall m5 : 13|1@1+ (1,0) [0|1] ""  gtw
 SG_ VCRIGHT_a190_eFuseMgmtVbatFused m3 : 13|1@1+ (1,0) [0|1] ""  gtw
 SG_ VCRIGHT_a130_hvacLHBleedUncalib m2 : 13|1@1+ (1,0) [0|1] ""  gtw
 SG_ VCRIGHT_a189_latchUnableToRearmR m3 : 12|1@1+ (1,0) [0|1] ""  gtw
 SG_ VCRIGHT_a249_seatHeatShortRearR m4 : 12|1@1+ (1,0) [0|1] ""  gtw
 SG_ VCRIGHT_a129_hvacIntakeUncalib m2 : 12|1@1+ (1,0) [0|1] ""  gtw
 SG_ VCRIGHT_a248_seatHeatIRearR m4 : 11|1@1+ (1,0) [0|1] ""  gtw
 SG_ VCRIGHT_a188_latchUnableToRearmF m3 : 11|1@1+ (1,0) [0|1] ""  gtw
 SG_ VCRIGHT_a307_handleDisconnectedR m5 : 10|1@1+ (1,0) [0|1] ""  gtw
 SG_ VCRIGHT_a187_latchReleaseFailedR m3 : 10|1@1+ (1,0) [0|1] ""  gtw
 SG_ VCRIGHT_a247_seatHeatMIARearC m4 : 10|1@1+ (1,0) [0|1] ""  gtw
 SG_ VCRIGHT_a186_latchReleaseFailedF m3 : 9|1@1+ (1,0) [0|1] ""  gtw
 SG_ VCRIGHT_a246_seatHeatShortRearC m4 : 9|1@1+ (1,0) [0|1] ""  gtw
 SG_ VCRIGHT_a306_handleDisconnectedF m5 : 9|1@1+ (1,0) [0|1] ""  gtw
 SG_ VCRIGHT_a185_summonAborted m3 : 8|1@1+ (1,0) [0|1] ""  gtw
 SG_ VCRIGHT_a245_seatHeatIRearC m4 : 8|1@1+ (1,0) [0|1] ""  gtw
 SG_ VCRIGHT_a305_rearIntHandleShorte m5 : 8|1@1+ (1,0) [0|1] ""  gtw
 SG_ VCRIGHT_a064_busSleepReqTimeout m1 : 7|1@1+ (1,0) [0|1] ""  gtw
 SG_ VCRIGHT_a244_seatHeatMIARearL m4 : 7|1@1+ (1,0) [0|1] ""  gtw
 SG_ VCRIGHT_a304_frontIntHandleShort m5 : 7|1@1+ (1,0) [0|1] ""  gtw
 SG_ VCRIGHT_a184_trunkFailedOpening m3 : 7|1@1+ (1,0) [0|1] ""  gtw
 SG_ VCRIGHT_a183_doorStateFactoryTes m3 : 6|1@1+ (1,0) [0|1] ""  gtw
 SG_ VCRIGHT_a003_SWAssertion m0 : 6|1@1+ (1,0) [0|1] ""  gtw
 SG_ VCRIGHT_a063_SwitchFault m1 : 6|1@1+ (1,0) [0|1] ""  gtw
 SG_ VCRIGHT_a243_seatHeatShortRearL m4 : 6|1@1+ (1,0) [0|1] ""  gtw
 SG_ VCRIGHT_a062_XCPWasConnected m1 : 5|1@1+ (1,0) [0|1] ""  gtw
 SG_ VCRIGHT_a002_PowerLossReset m0 : 5|1@1+ (1,0) [0|1] ""  gtw
 SG_ VCRIGHT_a242_seatHeatIRearL m4 : 5|1@1+ (1,0) [0|1] ""  gtw
 SG_ VCRIGHT_a182_emergencyLatchRel m3 : 5|1@1+ (1,0) [0|1] ""  gtw
 SG_ VCRIGHT_a001_WatchdogReset m0 : 4|1@1+ (1,0) [0|1] ""  gtw
 SG_ VCRIGHT_a061_XCPConnected m1 : 4|1@1+ (1,0) [0|1] ""  gtw
 SG_ VCRIGHT_a181_rearDoorLatchRehome m3 : 4|1@1+ (1,0) [0|1] ""  gtw
 SG_ VCRIGHT_a241_seatHeatMIAFront m4 : 4|1@1+ (1,0) [0|1] ""  gtw
 SG_ VCRIGHT_matrixIndex M : 0|4@1+ (1,0) [0|15] ""  gtw

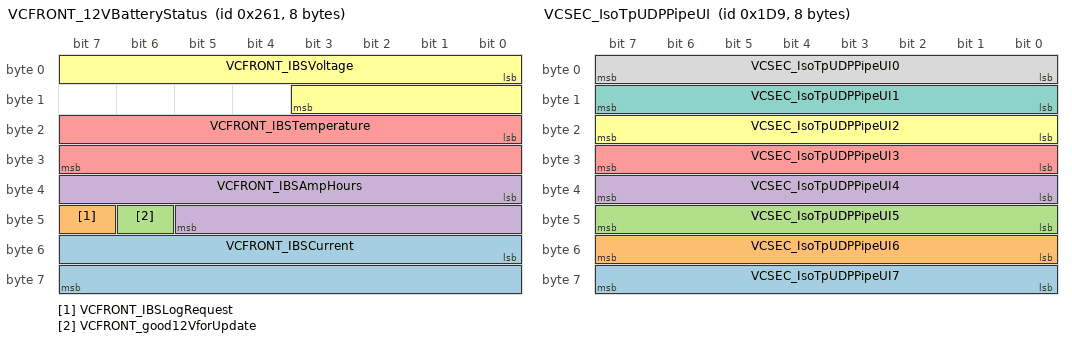
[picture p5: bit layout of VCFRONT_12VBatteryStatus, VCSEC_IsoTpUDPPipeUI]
BO_ 609 VCFRONT_12VBatteryStatus: 8 VEH
 SG_ VCFRONT_IBSCurrent : 48|16@1- (0.005,0) [-163.84|163.835] "A"  gtw
 SG_ VCFRONT_IBSLogRequest : 47|1@1+ (1,0) [0|1] ""  gtw
 SG_ VCFRONT_good12VforUpdate : 46|1@1+ (1,0) [0|1] ""  gtw
 SG_ VCFRONT_IBSAmpHours : 32|14@1- (0.01,0) [-81.92|81.91] "Ah"  gtw
 SG_ VCFRONT_IBSTemperature : 16|16@1- (0.01,0) [-327.68|327.66] "degC"  gtw
 SG_ VCFRONT_IBSVoltage : 0|12@1+ (0.005443676098,0) [0|22.29185] "V"  gtw

BO_ 530 BMS_status: 8 VEH
 SG_ BMS_minPackTemperature : 56|8@1+ (0.5,-40) [-40|87.5] "DegC"  di
 SG_ BMS_smStateRequest : 52|4@1+ (1,0) [0|9] ""  dbg
 SG_ BMS_chargeRetryCount : 49|3@1+ (1,0) [0|7] ""  gtw
 SG_ BMS_chgPowerAvailable : 38|11@1+ (0.125,0) [0|255.75] "kW"  gtw
 SG_ BMS_okToShipByLand : 37|1@1+ (1,0) [0|1] ""  X
 SG_ BMS_okToShipByAir : 36|1@1+ (1,0) [0|1] ""  X
 SG_ BMS_diLimpRequest : 35|1@1+ (1,0) [0|1] ""  di
 SG_ BMS_state : 31|4@1+ (1,0) [0|9] ""  dbg
 SG_ BMS_keepWarmRequest : 30|1@1+ (1,0) [0|1] ""  vcfront
 SG_ BMS_chargeRequest : 29|1@1+ (1,0) [0|1] ""  gtw
 SG_ BMS_isolationResistance : 19|10@1+ (10,0) [0|10000] "kOhm"  gtw
 SG_ BMS_hvState : 16|3@1+ (1,0) [0|6] ""  di
 SG_ BMS_ecuLogUploadRequest : 14|2@1+ (1,0) [0|3] ""  gtw
 SG_ BMS_uiChargeStatus : 11|3@1+ (1,0) [0|5] ""  gtw
 SG_ BMS_contactorState : 8|3@1+ (1,0) [0|6] ""  gtw
 SG_ BMS_pcsPwmEnabled : 7|1@1+ (1,0) [0|1] ""  X
 SG_ BMS_cpMiaOnHvs : 6|1@1+ (1,0) [0|1] ""  gtw
 SG_ BMS_activeHeatingWorthwhile : 5|1@1+ (1,0) [0|1] ""  gtw
 SG_ BMS_updateAllowed : 4|1@1+ (1,0) [0|1] ""  gtw
 SG_ BMS_preconditionAllowed : 3|1@1+ (1,0) [0|1] ""  X
 SG_ BMS_notEnoughPowerForSupport : 2|1@1+ (1,0) [0|1] ""  gtw
 SG_ BMS_notEnoughPowerForDrive : 1|1@1+ (1,0) [0|1] ""  gtw
 SG_ BMS_hvacPowerRequest : 0|1@1+ (1,0) [0|1] ""  vcfront

BO_ 473 VCSEC_IsoTpUDPPipeUI: 8 VEH
 SG_ VCSEC_IsoTpUDPPipeUI7 : 56|8@1+ (1,0) [0|255] ""  gtw
 SG_ VCSEC_IsoTpUDPPipeUI6 : 48|8@1+ (1,0) [0|255] ""  gtw
 SG_ VCSEC_IsoTpUDPPipeUI5 : 40|8@1+ (1,0) [0|255] ""  gtw
 SG_ VCSEC_IsoTpUDPPipeUI4 : 32|8@1+ (1,0) [0|255] ""  gtw
 SG_ VCSEC_IsoTpUDPPipeUI3 : 24|8@1+ (1,0) [0|255] ""  gtw
 SG_ VCSEC_IsoTpUDPPipeUI2 : 16|8@1+ (1,0) [0|255] ""  gtw
 SG_ VCSEC_IsoTpUDPPipeUI1 : 8|8@1+ (1,0) [0|255] ""  gtw
 SG_ VCSEC_IsoTpUDPPipeUI0 : 0|8@1+ (1,0) [0|255] ""  gtw

BO_ 739 VCRIGHT_seatStatus2: 6 VEH
 SG_ VCRIGHT_frontSeatHeatPowered m0 : 45|1@1+ (1,0) [0|1] ""  X
 SG_ VCRIGHT_rearCSeatHeatPowered m2 : 45|1@1+ (1,0) [0|1] ""  X
 SG_ VCRIGHT_rearLSeatHeatPowered m1 : 45|1@1+ (1,0) [0|1] ""  X
 SG_ VCRIGHT_rearRSeatHeatPowered m3 : 45|1@1+ (1,0) [0|1] ""  X
 SG_ VCRIGHT_rearLSeatHeatInhibited m1 : 44|1@1+ (1,0) [0|1] ""  gtw
 SG_ VCRIGHT_rearCSeatHeatInhibited m2 : 44|1@1+ (1,0) [0|1] ""  gtw
 SG_ VCRIGHT_frontSeatHeatInhibited m0 : 44|1@1+ (1,0) [0|1] ""  gtw
 SG_ VCRIGHT_rearRSeatHeatInhibited m3 : 44|1@1+ (1,0) [0|1] ""  gtw
 SG_ VCRIGHT_rearCSeatHeatTmpTarget m2 : 36|8@1- (0.5,0) [0|60] "degC"  gtw
 SG_ VCRIGHT_frontSeatHeatTmpTarget m0 : 36|8@1- (0.5,0) [0|60] "degC"  gtw
 SG_ VCRIGHT_rearRSeatHeatTmpTarget m3 : 36|8@1- (0.5,0) [0|60] "degC"  gtw
 SG_ VCRIGHT_rearLSeatHeatTmpTarget m1 : 36|8@1- (0.5,0) [0|60] "degC"  gtw
 SG_ VCRIGHT_rearRightBuckleVoltage m4 : 34|10@1+ (0.01,0) [0|10.23] "V"  gtw
 SG_ VCRIGHT_rearRSeatHeatTmp m3 : 24|12@1- (0.05,0) [-40|80] "degC"  gtw
 SG_ VCRIGHT_rearLSeatHeatTmp m1 : 24|12@1- (0.05,0) [-40|80] "degC"  gtw
 SG_ VCRIGHT_rearCSeatHeatTmp m2 : 24|12@1- (0.05,0) [-40|80] "degC"  gtw
 SG_ VCRIGHT_rearCenterBuckleVoltage m4 : 24|10@1+ (0.01,0) [0|10.23] "V"  gtw
 SG_ VCRIGHT_frontSeatHeatTmp m0 : 24|12@1- (0.05,0) [-40|80] "degC"  gtw
 SG_ VCRIGHT_rearRSeatHeatDuty m3 : 16|8@1+ (1,0) [0|255] "%"  gtw
 SG_ VCRIGHT_rearCSeatHeatDuty m2 : 16|8@1+ (1,0) [0|255] "%"  gtw
 SG_ VCRIGHT_rearLSeatHeatDuty m1 : 16|8@1+ (1,0) [0|255] "%"  gtw
 SG_ VCRIGHT_frontSeatHeatDuty m0 : 16|8@1+ (1,0) [0|255] "%"  gtw
 SG_ VCRIGHT_frontBuckleVoltage m4 : 14|10@1+ (0.01,0) [0|10.23] "V"  gtw
 SG_ VCRIGHT_rearRSeatHeatCurrent m3 : 4|12@1+ (0.01,0) [0|40.95] "A"  gtw
 SG_ VCRIGHT_frontOccupancyVoltage m4 : 4|10@1+ (0.01,0) [0|10.23] "V"  gtw
 SG_ VCRIGHT_rearLSeatHeatCurrent m1 : 4|12@1+ (0.01,0) [0|40.95] "A"  gtw
 SG_ VCRIGHT_rearCSeatHeatCurrent m2 : 4|12@1+ (0.01,0) [0|40.95] "A"  gtw
 SG_ VCRIGHT_frontSeatHeatCurrent m0 : 4|12@1+ (0.01,0) [0|40.95] "A"  gtw
 SG_ VCRIGHT_seatStatus2Index M : 0|3@1+ (1,0) [0|5] ""  X

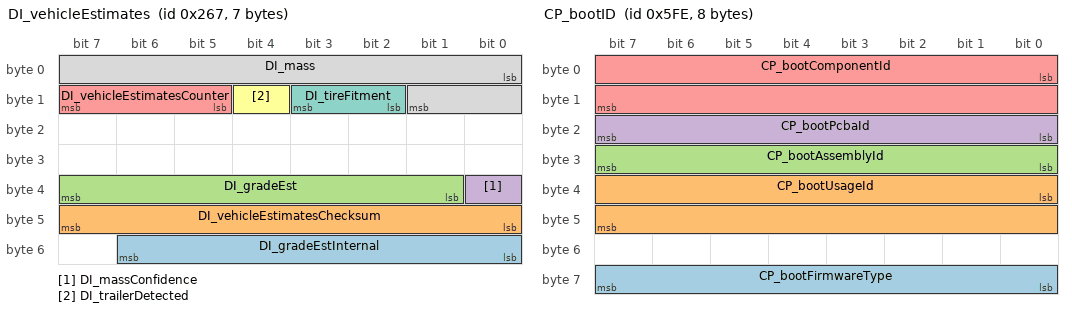
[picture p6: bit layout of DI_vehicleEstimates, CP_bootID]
BO_ 615 DI_vehicleEstimates: 7 VEH
 SG_ DI_gradeEstInternal : 48|7@1- (1,0) [-40|40] "%"  gtw
 SG_ DI_vehicleEstimatesChecksum : 40|8@1+ (1,0) [0|255] ""  X
 SG_ DI_gradeEst : 33|7@1- (1,0) [-40|40] "%"  gtw
 SG_ DI_massConfidence : 32|1@1+ (1,0) [0|1] ""  X
 SG_ DI_vehicleEstimatesCounter : 13|3@1+ (1,0) [0|7] ""  X
 SG_ DI_trailerDetected : 12|1@1+ (1,0) [0|1] ""  X
 SG_ DI_tireFitment : 10|2@1+ (1,0) [0|3] ""  X
 SG_ DI_mass : 0|10@1+ (5,1900) [1900|7010] "kg"  gtw

BO_ 1534 CP_bootID: 8 VEH
 SG_ CP_bootFirmwareType : 56|8@1+ (1,0) [0|255] ""  gtwu
 SG_ CP_bootUsageId : 32|16@1+ (1,0) [0|65535] ""  gtwu
 SG_ CP_bootAssemblyId : 24|8@1+ (1,0) [0|255] ""  gtwu
 SG_ CP_bootPcbaId : 16|8@1+ (1,0) [0|255] ""  gtwu
 SG_ CP_bootComponentId : 0|16@1+ (1,0) [0|65535] ""  gtwu

BO_ 1314 VCLEFT_alertCleared: 2 VEH
 SG_ VCLEFT_alertClearedID : 0|9@1+ (1,0) [0|324] ""  X

BO_ 784 HVP_info: 8 VEH
 SG_ HVP_componentId m10 : 48|16@1+ (1,0) [0|65535] ""  gtw
 SG_ HVP_subUsageId m11 : 48|16@1+ (1,0) [0|65535] ""  gtw
 SG_ HVP_usageId m11 : 32|16@1+ (1,0) [0|65535] ""  gtw
 SG_ HVP_bootCrc m20 : 32|32@1+ (1,0) [0|4294967295] ""  gtw
 SG_ HVP_hardwareId m10 : 32|16@1+ (1,0) [0|65535] ""  gtw
 SG_ HVP_appCrc m13 : 32|32@1+ (1,0) [0|4294967295] ""  gtw
 SG_ HVP_assemblyId m11 : 24|8@1+ (1,0) [0|255] ""  gtw
 SG_ HVP_buildConfigId m10 : 16|16@1+ (1,0) [0|65535] ""  gtw
 SG_ HVP_pcbaId m11 : 16|8@1+ (1,0) [0|255] ""  gtw
 SG_ HVP_bootGitHash m18 : 8|56@1+ (1,0) [0|72057594037927935] ""  gtw
 SG_ HVP_buildType m10 : 8|3@1+ (1,0) [0|4] ""  gtw
 SG_ HVP_bootUdsProtoVersion m20 : 8|8@1+ (1,0) [0|255] ""  gtw
 SG_ HVP_platformType m13 : 8|8@1+ (1,0) [0|255] ""  gtw
 SG_ HVP_appGitHash m17 : 8|56@1+ (1,0) [0|72057594037927935] ""  gtw
 SG_ HVP_infoIndex M : 0|8@1+ (1,0) [0|255] ""  gtw

BO_ 962 VCLEFT_switchStatus: 8 VEH
 SG_ VCLEFT_rearHVACButtonPressed m0 : 61|1@1+ (1,0) [0|1] ""  gtw
 SG_ VCLEFT_brakePressed m0 : 60|1@1+ (1,0) [0|1] ""  di
 SG_ VCLEFT_rearRightOccupancySwitch m0 : 58|2@1+ (1,0) [0|3] ""  gtw
 SG_ VCLEFT_rearLeftOccupancySwitch m0 : 56|2@1+ (1,0) [0|3] ""  gtw
 SG_ VCLEFT_rearCenterOccupancySwitch m0 : 54|2@1+ (1,0) [0|3] ""  gtw
 SG_ VCLEFT_rearLeftBuckleSwitch m0 : 52|2@1+ (1,0) [0|3] ""  gtw
 SG_ VCLEFT_frontOccupancySwitch m0 : 50|2@1+ (1,0) [0|3] ""  gtw
 SG_ VCLEFT_frontBuckleSwitch m0 : 48|2@1+ (1,0) [0|3] ""  gtw
 SG_ VCLEFT_btnWindowSwPackAutoDownRR m0 : 47|1@1+ (1,0) [0|1] ""  gtw
 SG_ VCLEFT_btnWindowSwPackDownRR m0 : 46|1@1+ (1,0) [0|1] ""  gtw
 SG_ VCLEFT_btnWindowSwPackAutoUpRR m0 : 45|1@1+ (1,0) [0|1] ""  gtw
 SG_ VCLEFT_btnWindowSwPackUpRR m0 : 44|1@1+ (1,0) [0|1] ""  gtw
 SG_ VCLEFT_btnWindowSwPackAutoDownRF m0 : 43|1@1+ (1,0) [0|1] ""  gtw
 SG_ VCLEFT_btnWindowSwPackDownRF m0 : 42|1@1+ (1,0) [0|1] ""  gtw
 SG_ VCLEFT_btnWindowSwPackAutoUpRF m0 : 41|1@1+ (1,0) [0|1] ""  gtw
 SG_ VCLEFT_btnWindowSwPackUpRF m0 : 40|1@1+ (1,0) [0|1] ""  gtw
 SG_ VCLEFT_btnWindowSwPackAutoDownLR m0 : 39|1@1+ (1,0) [0|1] ""  gtw
 SG_ VCLEFT_btnWindowSwPackDownLR m0 : 38|1@1+ (1,0) [0|1] ""  gtw
 SG_ VCLEFT_btnWindowSwPackAutoUpLR m0 : 37|1@1+ (1,0) [0|1] ""  gtw
 SG_ VCLEFT_btnWindowSwPackUpLR m0 : 36|1@1+ (1,0) [0|1] ""  gtw
 SG_ VCLEFT_btnWindowAutoDownLR m1 : 35|1@1+ (1,0) [0|1] ""  gtw
 SG_ VCLEFT_btnWindowSwPackAutoDownLF m0 : 35|1@1+ (1,0) [0|1] ""  gtw
 SG_ VCLEFT_btnWindowDownLR m1 : 34|1@1+ (1,0) [0|1] ""  gtw
 SG_ VCLEFT_btnWindowSwPackDownLF m0 : 34|1@1+ (1,0) [0|1] ""  gtw
 SG_ VCLEFT_btnWindowAutoUpLR m1 : 33|1@1+ (1,0) [0|1] ""  gtw
 SG_ VCLEFT_btnWindowSwPackAutoUpLF m0 : 33|1@1+ (1,0) [0|1] ""  gtw
 SG_ VCLEFT_btnWindowUpLR m1 : 32|1@1+ (1,0) [0|1] ""  gtw
 SG_ VCLEFT_btnWindowSwPackUpLF m0 : 32|1@1+ (1,0) [0|1] ""  gtw
 SG_ VCLEFT_frontSeatLumbarOut m0 : 30|2@1+ (1,0) [0|3] ""  gtw
 SG_ VCLEFT_frontSeatLumbarIn m0 : 28|2@1+ (1,0) [0|3] ""  gtw
 SG_ VCLEFT_frontSeatLumbarUp m0 : 26|2@1+ (1,0) [0|3] ""  gtw
 SG_ VCLEFT_swcRightScrollTicks m1 : 24|6@1- (1,0) [-32|31] ""  das
 SG_ VCLEFT_frontSeatLumbarDown m0 : 24|2@1+ (1,0) [0|3] ""  gtw
 SG_ VCLEFT_frontSeatBackrestForward m0 : 22|2@1+ (1,0) [0|3] ""  gtw
 SG_ VCLEFT_frontSeatBackrestBack m0 : 20|2@1+ (1,0) [0|3] ""  gtw
 SG_ VCLEFT_frontSeatLiftUp m0 : 18|2@1+ (1,0) [0|3] ""  gtw
 SG_ VCLEFT_frontSeatLiftDown m0 : 16|2@1+ (1,0) [0|3] ""  gtw
 SG_ VCLEFT_swcLeftScrollTicks m1 : 16|6@1- (1,0) [-32|31] ""  das
 SG_ VCLEFT_frontSeatTiltUp m0 : 14|2@1+ (1,0) [0|3] ""  gtw
 SG_ VCLEFT_swcLeftTiltLeft m1 : 14|2@1+ (1,0) [0|3] ""  das
 SG_ VCLEFT_swcRightPressed m1 : 12|2@1+ (1,0) [0|3] ""  das
 SG_ VCLEFT_frontSeatTiltDown m0 : 12|2@1+ (1,0) [0|3] ""  gtw
 SG_ VCLEFT_frontSeatTrackForward m0 : 10|2@1+ (1,0) [0|3] ""  gtw
 SG_ VCLEFT_swcRightTiltRight m1 : 10|2@1+ (1,0) [0|3] ""  das
 SG_ VCLEFT_swcRightTiltLeft m1 : 8|2@1+ (1,0) [0|3] ""  das
 SG_ VCLEFT_frontSeatTrackBack m0 : 8|2@1+ (1,0) [0|3] ""  gtw
 SG_ VCLEFT_swcLeftPressed m1 : 5|2@1+ (1,0) [0|3] ""  das
 SG_ VCLEFT_rightMirrorTilt m0 : 5|3@1+ (1,0) [0|4] ""  vcright
 SG_ VCLEFT_driverPresent m0 : 4|1@1+ (1,0) [0|1] ""  das
 SG_ VCLEFT_hazardButtonPressed m0 : 3|1@1+ (1,0) [0|1] ""  gtw
 SG_ VCLEFT_swcLeftTiltRight m1 : 3|2@1+ (1,0) [0|3] ""  das
 SG_ VCLEFT_hornSwitchPressed m0 : 2|1@1+ (1,0) [0|1] ""  app
 SG_ VCLEFT_switchStatusIndex M : 0|2@1+ (1,0) [0|2] ""  X

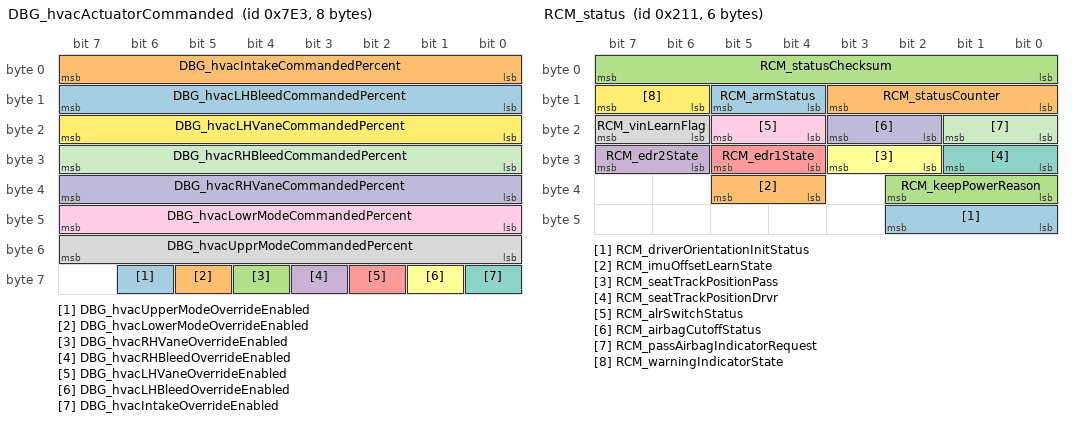
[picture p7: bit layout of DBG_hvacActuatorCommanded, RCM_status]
BO_ 2019 DBG_hvacActuatorCommanded: 8 VEH
 SG_ DBG_hvacUpperModeOverrideEnabled : 62|1@1+ (1,0) [0|1] ""  vcright
 SG_ DBG_hvacLowerModeOverrideEnabled : 61|1@1+ (1,0) [0|1] ""  vcright
 SG_ DBG_hvacRHVaneOverrideEnabled : 60|1@1+ (1,0) [0|1] ""  vcright
 SG_ DBG_hvacRHBleedOverrideEnabled : 59|1@1+ (1,0) [0|1] ""  vcright
 SG_ DBG_hvacLHVaneOverrideEnabled : 58|1@1+ (1,0) [0|1] ""  vcright
 SG_ DBG_hvacLHBleedOverrideEnabled : 57|1@1+ (1,0) [0|1] ""  vcright
 SG_ DBG_hvacIntakeOverrideEnabled : 56|1@1+ (1,0) [0|1] ""  vcright
 SG_ DBG_hvacUpprModeCommandedPercent : 48|8@1+ (0.4,0) [0|100] "%"  vcright
 SG_ DBG_hvacLowrModeCommandedPercent : 40|8@1+ (0.4,0) [0|100] "%"  vcright
 SG_ DBG_hvacRHVaneCommandedPercent : 32|8@1+ (0.4,0) [0|100] "%"  vcright
 SG_ DBG_hvacRHBleedCommandedPercent : 24|8@1+ (0.4,0) [0|100] "%"  vcright
 SG_ DBG_hvacLHVaneCommandedPercent : 16|8@1+ (0.4,0) [0|100] "%"  vcright
 SG_ DBG_hvacLHBleedCommandedPercent : 8|8@1+ (0.4,0) [0|100] "%"  vcright
 SG_ DBG_hvacIntakeCommandedPercent : 0|8@1+ (0.4,0) [0|100] "%"  vcright

BO_ 965 DIS_alertMatrix3: 8 VEH
 SG_ DIS_a161_epas3pMIA : 32|1@1+ (1,0) [0|1] ""  gtw
 SG_ DIS_a160_busVoltageAnomaly : 31|1@1+ (1,0) [0|1] ""  gtw
 SG_ DIS_a158_ibstMIA : 29|1@1+ (1,0) [0|1] ""  gtw
 SG_ DIS_a157_rcmMIA : 28|1@1+ (1,0) [0|1] ""  gtw
 SG_ DIS_a156_currentObserver : 27|1@1+ (1,0) [0|1] ""  gtw
 SG_ DIS_a155_vcfrontMIA : 26|1@1+ (1,0) [0|1] ""  gtw
 SG_ DIS_a154_resolver : 25|1@1+ (1,0) [0|1] ""  gtw
 SG_ DIS_a153_oilPump : 24|1@1+ (1,0) [0|1] ""  gtw
 SG_ DIS_a152_linError : 23|1@1+ (1,0) [0|1] ""  gtw
 SG_ DIS_a151_shockTorqueLimiter : 22|1@1+ (1,0) [0|1] ""  gtw
 SG_ DIS_a150_busVD : 21|1@1+ (1,0) [0|1] ""  gtw
 SG_ DIS_a149_oilPumpFailure : 20|1@1+ (1,0) [0|1] ""  gtw
 SG_ DIS_a148_overtorqueUsed : 19|1@1+ (1,0) [0|1] ""  gtw
 SG_ DIS_a147_highTorqueWearLimit : 18|1@1+ (1,0) [0|1] ""  gtw
 SG_ DIS_a144_configMismatch : 15|1@1+ (1,0) [0|1] ""  gtw
 SG_ DIS_a143_mcuLimitActive : 14|1@1+ (1,0) [0|1] ""  gtw
 SG_ DIS_a142_highLashAngle : 13|1@1+ (1,0) [0|1] ""  gtw
 SG_ DIS_a136_spiError : 7|1@1+ (1,0) [0|1] ""  gtw
 SG_ DIS_a134_wheelSpeedIrrational : 5|1@1+ (1,0) [0|1] ""  gtw
 SG_ DIS_a133_capacitorOT : 4|1@1+ (1,0) [0|1] ""  gtw
 SG_ DIS_a131_highSpeedWearLimit : 2|1@1+ (1,0) [0|1] ""  gtw
 SG_ DIS_a129_epbNotApplied : 0|1@1+ (1,0) [0|1] ""  gtw

BO_ 816 SCCM_info: 8 VEH
 SG_ SCCM_infoSubUsageId m11 : 48|16@1+ (1,0) [0|65535] ""  gtw
 SG_ SCCM_infoComponentId m10 : 48|16@1+ (1,0) [0|65535] ""  X
 SG_ SCCM_infoBootCrc m20 : 32|32@1+ (1,0) [0|4294967295] ""  gtw
 SG_ SCCM_infoUsageId m11 : 32|16@1+ (1,0) [0|65535] ""  gtw
 SG_ SCCM_infoHardwareId m10 : 32|16@1+ (1,0) [0|65535] ""  gtw
 SG_ SCCM_infoBootSvnUrlHash m14 : 32|32@1+ (1,0) [0|4294967295] ""  gtw
 SG_ SCCM_infoAppCrc m13 : 39|32@0+ (1,0) [0|4294967295] ""  gtw
 SG_ SCCM_infoAssemblyId m11 : 24|8@1+ (1,0) [0|255] ""  gtw
 SG_ SCCM_infoPcbaId m11 : 16|8@1+ (1,0) [0|255] ""  gtw
 SG_ SCCM_infoBuildConfigId m10 : 16|16@1+ (1,0) [0|65535] ""  gtw
 SG_ SCCM_infoSubcomponent1Version m16 : 16|32@1+ (1,0) [0|4294967295] ""  gtw
 SG_ SCCM_infoBuildType m10 : 8|8@1+ (1,0) [0|4] ""  gtw
 SG_ SCCM_infoUdsProtoVersion m20 : 8|8@1+ (1,0) [0|255] ""  X
 SG_ SCCM_infoBootSvnRev m14 : 8|24@1+ (1,0) [0|16777215] ""  gtw
 SG_ SCCM_infoPlatformType m13 : 8|8@1+ (1,0) [0|255] ""  gtw
 SG_ SCCM_infoAppSvnHash m17 : 8|56@1+ (1,0) [0|72057594037927935] ""  gtw
 SG_ SCCM_infoBootSvnHash m18 : 8|56@1+ (1,0) [0|72057594037927935] ""  gtw
 SG_ SCCM_infoIndex M : 0|8@1+ (1,0) [10|255] ""  gtw

BO_ 529 RCM_status: 6 VEH
 SG_ RCM_driverOrientationInitStatus : 40|3@1+ (1,0) [0|7] ""  X
 SG_ RCM_imuOffsetLearnState : 36|2@1+ (1,0) [0|3] ""  X
 SG_ RCM_keepPowerReason : 32|3@1+ (1,0) [0|7] ""  vcfront
 SG_ RCM_edr2State : 30|2@1+ (1,0) [0|3] ""  X
 SG_ RCM_edr1State : 28|2@1+ (1,0) [0|3] ""  X
 SG_ RCM_seatTrackPositionPass : 26|2@1+ (1,0) [0|3] ""  X
 SG_ RCM_seatTrackPositionDrvr : 24|2@1+ (1,0) [0|3] ""  X
 SG_ RCM_vinLearnFlag : 22|2@1+ (1,0) [0|3] ""  X
 SG_ RCM_alrSwitchStatus : 20|2@1+ (1,0) [0|3] ""  X
 SG_ RCM_airbagCutoffStatus : 18|2@1+ (1,0) [0|3] ""  X
 SG_ RCM_passAirbagIndicatorRequest : 16|2@1+ (1,0) [0|3] ""  X
 SG_ RCM_warningIndicatorState : 14|2@1+ (1,0) [0|3] ""  X
 SG_ RCM_armStatus : 12|2@1+ (1,0) [0|3] ""  X
 SG_ RCM_statusCounter : 8|4@1+ (1,0) [0|15] ""  X
 SG_ RCM_statusChecksum : 0|8@1+ (1,0) [0|255] ""  X

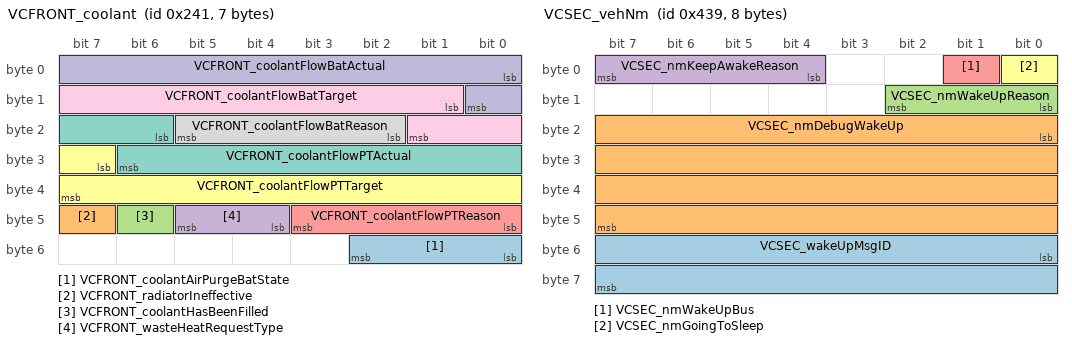
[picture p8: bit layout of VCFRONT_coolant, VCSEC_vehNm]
BO_ 577 VCFRONT_coolant: 7 VEH
 SG_ VCFRONT_coolantAirPurgeBatState : 48|3@1+ (1,0) [0|4] ""  das
 SG_ VCFRONT_radiatorIneffective : 47|1@1+ (1,0) [0|1] ""  gtw
 SG_ VCFRONT_coolantHasBeenFilled : 46|1@1+ (1,0) [0|1] ""  gtw
 SG_ VCFRONT_wasteHeatRequestType : 44|2@1+ (1,0) [0|2] ""  bms
 SG_ VCFRONT_coolantFlowPTReason : 40|4@1+ (1,0) [0|13] ""  gtw
 SG_ VCFRONT_coolantFlowPTTarget : 31|9@1+ (0.1,0) [0|40] "LPM"  gtw
 SG_ VCFRONT_coolantFlowPTActual : 22|9@1+ (0.1,0) [0|40] "LPM"  di
 SG_ VCFRONT_coolantFlowBatReason : 18|4@1+ (1,0) [0|13] ""  gtw
 SG_ VCFRONT_coolantFlowBatTarget : 9|9@1+ (0.1,0) [0|40] "LPM"  gtw
 SG_ VCFRONT_coolantFlowBatActual : 0|9@1+ (0.1,0) [0|40] "LPM"  bms

BO_ 770 VCLEFT_info: 8 VEH
 SG_ VCLEFT_infoComponentId m10 : 48|16@1+ (1,0) [0|65535] ""  gtw
 SG_ VCLEFT_infoSubUsageId m11 : 40|16@1+ (1,0) [0|65535] ""  gtw
 SG_ VCLEFT_infoCBCAppCRC m31 : 32|32@1+ (1,0) [0|4294967295] ""  gtw
 SG_ VCLEFT_infoSubcomponent3 m24 : 32|32@1+ (1,0) [0|4294967295] ""  X
 SG_ VCLEFT_infoHardwareId m10 : 32|16@1+ (1,0) [0|65535] ""  gtw
 SG_ VCLEFT_infoSubcomponent1 m16 : 32|32@1+ (1,0) [0|4294967295] ""  X
 SG_ VCLEFT_swcAppCRC m23 : 32|32@1+ (1,0) [0|4294967295] ""  gtw
 SG_ VCLEFT_infoBootCrc m20 : 24|32@1+ (1,0) [0|4294967295] ""  gtw
 SG_ VCLEFT_infoUsageId m11 : 24|16@1+ (1,0) [0|65535] ""  gtw
 SG_ VCLEFT_infoAssemblyId m11 : 16|8@1+ (1,0) [0|255] ""  gtw
 SG_ VCLEFT_infoBuildConfigId m10 : 16|16@1+ (1,0) [0|65535] ""  gtw
 SG_ VCLEFT_infoBuildType m10 : 8|3@1+ (1,0) [0|4] ""  gtw
 SG_ VCLEFT_infoBootGitHash m18 : 8|56@1+ (1,0) [0|72057594037927935] ""  gtw
 SG_ VCLEFT_infoAppGitHash m17 : 8|56@1+ (1,0) [0|72057594037927935] ""  gtw
 SG_ VCLEFT_infoPlatformType m19 : 8|8@1+ (1,0) [0|255] ""  gtw
 SG_ VCLEFT_infoPcbaId m11 : 8|8@1+ (1,0) [0|255] ""  gtw
 SG_ VCLEFT_infoBootUdsProtoVersion m20 : 8|16@1+ (1,0) [0|65535] ""  gtw
 SG_ VCLEFT_infoAppCrc m13 : 8|32@1+ (1,0) [0|4294967295] ""  gtw
 SG_ VCLEFT_infoIndex M : 0|8@1+ (1,0) [0|255] ""  gtw

BO_ 1572 UDS_epblRequest: 8 VEH
 SG_ UDS_epblRequestData_L : 39|32@0+ (1,0) [0|4294967295] ""  epbl
 SG_ UDS_epblRequestData_H : 7|32@0+ (1,0) [0|4294967295] ""  epbl

BO_ 1081 VCSEC_vehNm: 8 VEH
 SG_ VCSEC_wakeUpMsgID : 48|16@1+ (1,0) [0|65535] ""  gtw
 SG_ VCSEC_nmDebugWakeUp : 16|32@1+ (1,0) [0|4294967295] ""  gtw
 SG_ VCSEC_nmWakeUpReason : 8|3@1+ (1,0) [0|7] ""  gtw
 SG_ VCSEC_nmKeepAwakeReason : 4|4@1+ (1,0) [0|15] ""  gtw
 SG_ VCSEC_nmWakeUpBus : 1|1@1+ (1,0) [0|1] ""  X
 SG_ VCSEC_nmGoingToSleep : 0|1@1+ (1,0) [0|1] ""  X

BO_ 22 DI_bmsRequest: 1 VEH
 SG_ DI_bmsOpenContactorsRequest : 4|1@1+ (1,0) [0|1] ""  bms
 SG_ DI_bmsRequestInterfaceVersion : 0|4@1+ (1,0) [0|15] ""  X

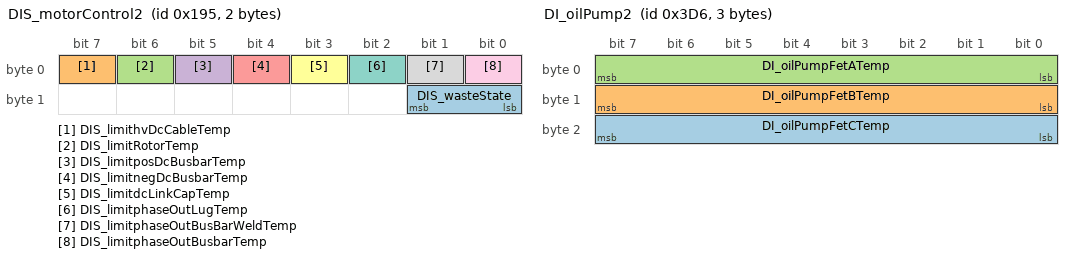
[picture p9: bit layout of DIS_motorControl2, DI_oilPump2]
BO_ 405 DIS_motorControl2: 2 VEH
 SG_ DIS_wasteState : 8|2@1+ (1,0) [0|2] ""  gtw
 SG_ DIS_limithvDcCableTemp : 7|1@1+ (1,0) [0|1] ""  gtw
 SG_ DIS_limitRotorTemp : 6|1@1+ (1,0) [0|1] ""  gtw
 SG_ DIS_limitposDcBusbarTemp : 5|1@1+ (1,0) [0|1] ""  gtw
 SG_ DIS_limitnegDcBusbarTemp : 4|1@1+ (1,0) [0|1] ""  gtw
 SG_ DIS_limitdcLinkCapTemp : 3|1@1+ (1,0) [0|1] ""  gtw
 SG_ DIS_limitphaseOutLugTemp : 2|1@1+ (1,0) [0|1] ""  gtw
 SG_ DIS_limitphaseOutBusBarWeldTemp : 1|1@1+ (1,0) [0|1] ""  gtw
 SG_ DIS_limitphaseOutBusbarTemp : 0|1@1+ (1,0) [0|1] ""  gtw

BO_ 982 DI_oilPump2: 3 VEH
 SG_ DI_oilPumpFetCTemp : 16|8@1+ (1,-40) [-40|214] "DegC"  gtw
 SG_ DI_oilPumpFetBTemp : 8|8@1+ (1,-40) [-40|214] "DegC"  gtw
 SG_ DI_oilPumpFetATemp : 0|8@1+ (1,-40) [-40|214] "DegC"  gtw

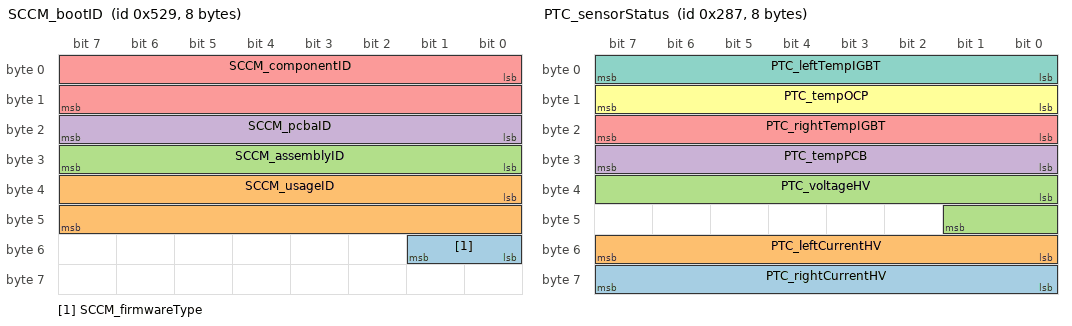
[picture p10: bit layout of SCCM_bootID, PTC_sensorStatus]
BO_ 1321 SCCM_bootID: 8 VEH
 SG_ SCCM_firmwareType : 48|2@1+ (1,0) [0|2] ""  gtwu
 SG_ SCCM_usageID : 32|16@1+ (1,0) [0|65535] ""  gtwu
 SG_ SCCM_assemblyID : 24|8@1+ (1,0) [0|255] ""  gtwu
 SG_ SCCM_pcbaID : 16|8@1+ (1,0) [0|255] ""  gtwu
 SG_ SCCM_componentID : 0|16@1+ (1,0) [0|65535] ""  gtwu

BO_ 647 PTC_sensorStatus: 8 VEH
 SG_ PTC_rightCurrentHV : 56|8@1+ (0.2,0) [0|50] "A"  bms
 SG_ PTC_leftCurrentHV : 48|8@1+ (0.2,0) [0|50] "A"  bms
 SG_ PTC_voltageHV : 32|10@1+ (0.5,0) [0|511.5] "V"  gtw
 SG_ PTC_tempPCB : 24|8@1+ (1,-40) [-40|200] "degC"  gtw
 SG_ PTC_rightTempIGBT : 16|8@1+ (1,-40) [-40|200] "degC"  gtw
 SG_ PTC_tempOCP : 8|8@1+ (1,-40) [-40|200] "degC"  gtw
 SG_ PTC_leftTempIGBT : 0|8@1+ (1,-40) [-40|200] "degC"  gtw

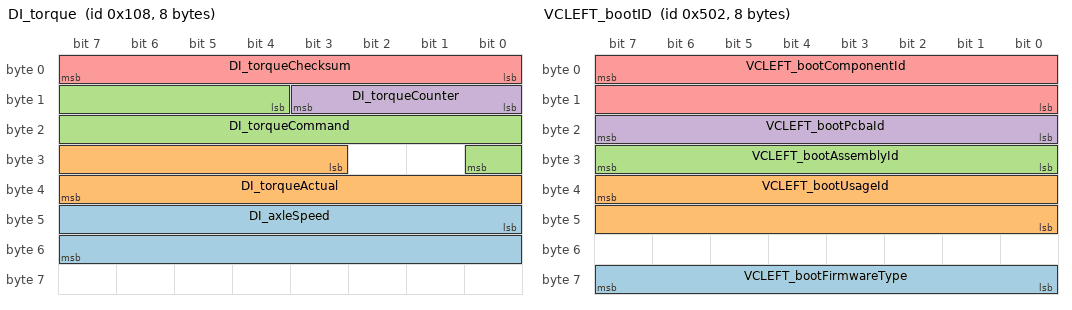
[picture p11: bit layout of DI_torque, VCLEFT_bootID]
BO_ 264 DI_torque: 8 VEH
 SG_ DI_axleSpeed : 40|16@1- (0.1,0.0) [-2750|2750] "RPM"  epbl
 SG_ DI_torqueActual : 27|13@1- (2,0) [-7500|7500] "Nm"  epbl
 SG_ DI_torqueCommand : 12|13@1- (2,0) [-7500|7500] "Nm"  X
 SG_ DI_torqueCounter : 8|4@1+ (1,0) [0|15] ""  X
 SG_ DI_torqueChecksum : 0|8@1+ (1,0) [0|255] ""  X

BO_ 691 VCRIGHT_logging1Hz: 8 VEH
 SG_ VCRIGHT_defrostAirflowBlocked m3 : 57|1@1+ (1,0) [0|1] ""  gtw
 SG_ VCRIGHT_hvacIntakeVoltage m6 : 56|8@1+ (0.02,0) [0|5] "V"  gtw
 SG_ VCRIGHT_floorAirflowBlocked m3 : 56|1@1+ (1,0) [0|1] ""  gtw
 SG_ VCRIGHT_cabinTempBreathLevel m1 : 56|8@1+ (0.5,-40) [-40|80] "degC"  gtw
 SG_ VCRIGHT_solarLoadOnVehicle m4 : 56|8@1+ (4,0) [0|1020] "W/m2"  gtw
 SG_ VCRIGHT_hvacIntakeZeroStop m8 : 56|8@1+ (0.02,0) [0|5] "V"  gtw
 SG_ VCRIGHT_ptcHeaterPwrDemandRight m2 : 56|8@1+ (20,0) [0|5000] "W"  gtw
 SG_ VCRIGHT_cabinTempInteriorSunnyL2 m0 : 56|8@1+ (0.6,-40) [-40|100] "degC"  gtw
 SG_ VCRIGHT_hvacIntakeEndStop m7 : 56|8@1+ (0.02,0) [0|5] "V"  gtw
 SG_ VCRIGHT_RHPanelAirflowBlocked m3 : 55|1@1+ (1,0) [0|1] ""  gtw
 SG_ VCRIGHT_LHPanelAirflowBlocked m3 : 54|1@1+ (1,0) [0|1] ""  gtw
 SG_ VCRIGHT_evapLoadInRecirc m5 : 53|8@1+ (35,0) [0|8000] "W"  gtw
 SG_ VCRIGHT_hvacQdotLimitedRight m3 : 53|1@1+ (1,0) [0|1] ""  gtw
 SG_ VCRIGHT_hvacQdotLimitedLeft m3 : 52|1@1+ (1,0) [0|1] ""  gtw
 SG_ VCRIGHT_cabinTempTopPadAir m9 : 52|8@1+ (0.6,-40) [-40|100] "degC"  gtw
 SG_ VCRIGHT_hvacLowerModeEndStop m7 : 48|8@1+ (0.02,0) [0|5] "V"  gtw
 SG_ VCRIGHT_ptcHeaterPwrDemandLeft m2 : 48|8@1+ (20,0) [0|5000] "W"  gtw
 SG_ VCRIGHT_cabinTempSideGlassRight m1 : 48|8@1+ (0.5,-40) [-40|80] "degC"  gtw
 SG_ VCRIGHT_solarLoadLeftOccupant m4 : 48|7@1+ (2,0) [0|256] "W/m2"  gtw
 SG_ VCRIGHT_cabinTempInteriorL2 m0 : 48|8@1+ (0.5,-40) [-40|80] "degC"  gtw
 SG_ VCRIGHT_hvacLowerModeZeroStop m8 : 48|8@1+ (0.02,0) [0|5] "V"  gtw
 SG_ VCRIGHT_hvacAirflowReason m3 : 48|4@1+ (1,0) [0|13] ""  gtw
 SG_ VCRIGHT_hvacLowerModeVoltage m6 : 48|8@1+ (0.02,0) [0|5] "V"  gtw
 SG_ VCRIGHT_evapLoadInFresh m5 : 45|8@1+ (35,0) [0|8000] "W"  gtw
 SG_ VCRIGHT_cabinTempInteriorSunnyL3 m9 : 44|8@1+ (0.6,-40) [-40|100] "degC"  gtw
 SG_ VCRIGHT_hvacMassflowTarget m3 : 40|8@1+ (1,0) [0|200] "g/s"  gtw
 SG_ VCRIGHT_hvacUpperModeEndStop m7 : 40|8@1+ (0.02,0) [0|5] "V"  gtw
 SG_ VCRIGHT_solarLoadRightOccupant m4 : 40|7@1+ (2,0) [0|256] "W/m2"  gtw
 SG_ VCRIGHT_cabinTempSideGlassLeft m1 : 40|8@1+ (0.5,-40) [-40|80] "degC"  gtw
 SG_ VCRIGHT_hvacUpperModeVoltage m6 : 40|8@1+ (0.02,0) [0|5] "V"  gtw
 SG_ VCRIGHT_hvacUpperModeZeroStop m8 : 40|8@1+ (0.02,0) [0|5] "V"  gtw
 SG_ VCRIGHT_tempIncarCabinDeep m0 : 40|8@1+ (0.5,-40) [-40|85] "degC"  gtw
 SG_ VCRIGHT_wattsHeaterRightTotal m2 : 38|10@1+ (5,0) [0|4000] "W"  gtw
 SG_ VCRIGHT_cabinTempInteriorL3 m9 : 36|8@1+ (0.5,-40) [-40|80] "degC"  gtw
 SG_ VCRIGHT_convectionDeliveredRight m4 : 32|8@1+ (2,-254) [-254|256] "W/m2"  gtw
 SG_ VCRIGHT_hvacAirFlowModeRow2 m3 : 32|3@1+ (1,0) [0|7] ""  gtw
 SG_ VCRIGHT_hvacRHVaneVoltage m6 : 32|8@1+ (0.02,0) [0|5] "V"  gtw
 SG_ VCRIGHT_cabinTempInteriorSunny m1 : 32|8@1+ (0.6,-40) [-40|100] "degC"  gtw
 SG_ VCRIGHT_tempIncarCabinMid m0 : 32|8@1+ (0.5,-40) [-40|85] "degC"  gtw
 SG_ VCRIGHT_hvacRHVaneZeroStop m8 : 32|8@1+ (0.02,0) [0|5] "V"  gtw
 SG_ VCRIGHT_hvacRHVaneEndStop m7 : 32|8@1+ (0.02,0) [0|5] "V"  gtw
 SG_ VCRIGHT_tempHtrSurfaceModeledR m10 : 31|9@1+ (0.3,-40) [-40|105] "degC"  gtw
 SG_ VCRIGHT_hvacQdotFeedforward m5 : 29|16@1+ (1,-32767) [-32767|32767] "W"  gtw
 SG_ VCRIGHT_hvacAirFlowModeRow1 m3 : 29|3@1+ (1,0) [0|7] ""  gtw
 SG_ VCRIGHT_cloudinessProbability m9 : 29|7@1+ (1,0) [0|100] "%"  gtw
 SG_ VCRIGHT_wattsHeaterLeftTotal m2 : 28|10@1+ (5,0) [0|4000] "W"  gtw
 SG_ VCRIGHT_hvacCabOvrheatProtAllowe m9 : 28|1@1+ (1,0) [0|1] ""  gtw
 SG_ VCRIGHT_hvacCabinPurgeAllowed m9 : 27|1@1+ (1,0) [0|1] ""  gtw
 SG_ VCRIGHT_hvacCabOvrheatProtActive m9 : 26|1@1+ (1,0) [0|1] ""  gtw
 SG_ VCRIGHT_hvacCabinPurgeActive m9 : 25|1@1+ (1,0) [0|1] ""  gtw
 SG_ VCRIGHT_hvacLHVaneEndStop m7 : 24|8@1+ (0.02,0) [0|5] "V"  gtw
 SG_ VCRIGHT_hvacAutoTransitionReason m3 : 24|5@1+ (1,0) [0|17] ""  gtw
 SG_ VCRIGHT_hvacLHVaneZeroStop m8 : 24|8@1+ (0.02,0) [0|5] "V"  gtw
 SG_ VCRIGHT_cabinTempInterior m1 : 24|8@1+ (0.5,-40) [-40|80] "degC"  gtw
 SG_ VCRIGHT_convectionDeliveredLeft m4 : 24|8@1+ (2,-254) [-254|256] "W/m2"  gtw
 SG_ VCRIGHT_hvacLHVaneVoltage m6 : 24|8@1+ (0.02,0) [0|5] "V"  gtw
 SG_ VCRIGHT_tempIncarCabinProbe m0 : 24|8@1+ (0.5,-40) [-40|85] "degC"  gtw
 SG_ VCRIGHT_tempHtrSurfaceModeledL m10 : 22|9@1+ (0.3,-40) [-40|105] "degC"  gtw
 SG_ VCRIGHT_hvacDuctTargetRight m5 : 21|8@1+ (0.5,-40) [-40|80] "degC"  gtw
 SG_ VCRIGHT_solarLoadOnVehFiltered m9 : 17|8@1+ (4,0) [0|1020] "W/m2"  gtw
 SG_ VCRIGHT_hvacRHBleedEndStop m7 : 16|8@1+ (0.02,0) [0|5] "V"  gtw
 SG_ VCRIGHT_cabinTempWindshield m1 : 16|8@1+ (0.5,-40) [-40|80] "degC"  gtw
 SG_ VCRIGHT_hvacRHBleedZeroStop m8 : 16|8@1+ (0.02,0) [0|5] "V"  gtw
 SG_ VCRIGHT_hvacSetTempActualRight m3 : 16|8@1+ (0.1,15) [15|28] "degC"  gtw
 SG_ VCRIGHT_convectionTargetRight m4 : 16|8@1+ (2,-254) [-254|256] "W/m2"  gtw
 SG_ VCRIGHT_hvacRHBleedVoltage m6 : 16|8@1+ (0.02,0) [0|5] "V"  gtw
 SG_ VCRIGHT_tempDuctModeledRight m10 : 13|9@1+ (0.3,-40) [-40|105] "degC"  gtw
 SG_ VCRIGHT_tempDuctRight m0 : 13|9@1+ (0.3,-40) [-40|105] "degC"  gtw
 SG_ VCRIGHT_hvacDuctTargetLeft m5 : 13|8@1+ (0.5,-40) [-40|80] "degC"  gtw
 SG_ VCRIGHT_ptcHeaterReqAirpathBlock m5 : 12|1@1+ (1,0) [0|1] ""  gtw
 SG_ VCRIGHT_ptcHeaterRAirPathBlocked m5 : 11|1@1+ (1,0) [0|1] ""  gtw
 SG_ VCRIGHT_ptcHeaterLAirPathBlocked m5 : 10|1@1+ (1,0) [0|1] ""  gtw
 SG_ VCRIGHT_ptcHeaterNoHighVoltage m5 : 9|1@1+ (1,0) [0|1] ""  gtw
 SG_ VCRIGHT_convectionTargetLeft m4 : 8|8@1+ (2,-254) [-254|256] "W/m2"  gtw
 SG_ VCRIGHT_hvacLHBleedVoltage m6 : 8|8@1+ (0.02,0) [0|5] "V"  gtw
 SG_ VCRIGHT_ptcHeaterNoUiRequest m5 : 8|1@1+ (1,0) [0|1] ""  gtw
 SG_ VCRIGHT_hvacSetTempActualLeft m3 : 8|8@1+ (0.1,15) [15|28] "degC"  gtw
 SG_ VCRIGHT_hvacLHBleedZeroStop m8 : 8|8@1+ (0.02,0) [0|5] "V"  gtw
 SG_ VCRIGHT_cabinTempGlassRoof m1 : 8|8@1+ (0.5,-40) [-40|80] "degC"  gtw
 SG_ VCRIGHT_hvacLHBleedEndStop m7 : 8|8@1+ (0.02,0) [0|5] "V"  gtw
 SG_ VCRIGHT_ptcHeaterHvacActNotReady m5 : 7|1@1+ (1,0) [0|1] ""  gtw
 SG_ VCRIGHT_ptcHeaterNoAirflow m5 : 6|1@1+ (1,0) [0|1] ""  gtw
 SG_ VCRIGHT_ptcHeaterTempDuctFault m5 : 5|1@1+ (1,0) [0|1] ""  gtw
 SG_ VCRIGHT_ptcHeaterTempDuctHigh m5 : 4|1@1+ (1,0) [0|1] ""  gtw
 SG_ VCRIGHT_tempDuctLeft m0 : 4|9@1+ (0.3,-40) [-40|105] "degC"  gtw
 SG_ VCRIGHT_tempDuctModeledLeft m10 : 4|9@1+ (0.3,-40) [-40|105] "degC"  gtw
 SG_ VCRIGHT_logging1HzIndex M : 0|4@1+ (1,0) [0|11] ""  X

BO_ 1282 VCLEFT_bootID: 8 VEH
 SG_ VCLEFT_bootFirmwareType : 63|8@0+ (1,0) [0|255] ""  X
 SG_ VCLEFT_bootUsageId : 39|16@0+ (1,0) [0|65535] ""  X
 SG_ VCLEFT_bootAssemblyId : 31|8@0+ (1,0) [0|255] ""  X
 SG_ VCLEFT_bootPcbaId : 23|8@0+ (1,0) [0|255] ""  X
 SG_ VCLEFT_bootComponentId : 7|16@0+ (1,0) [0|65535] ""  X

BO_ 1736 EPBL_statsOutput: 8 VEH
 SG_ EPBL_staticApplyCountsVeryCold m0 : 44|20@1+ (1,0) [0|1048575] ""  X
 SG_ EPBL_staticApplyCountsCold m0 : 24|20@1+ (1,0) [0|1048575] ""  X
 SG_ EPBL_dynamicApplyCounts m1 : 8|32@1+ (1,0) [0|4294967295] ""  X
 SG_ EPBL_staticApplyCounts m0 : 2|20@1+ (1,0) [0|1048575] ""  X
 SG_ EPBL_statsOutput M : 0|2@1+ (1,0) [0|2] ""  X

BO_ 1029 GTW_vin: 8 VEH
 SG_ GTW_vinHigh m16 : 47|24@0+ (1,0) [0|16777215] ""  bms
 SG_ GTW_vinLow m18 : 15|56@0+ (1,0) [0|72057594037927935] ""  bms
 SG_ GTW_vinMid m17 : 15|56@0+ (1,0) [0|72057594037927935] ""  bms
 SG_ GTW_vinIndex M : 7|8@0+ (1,0) [16|18] ""  vcleft

BO_ 1928 EPBL_debugOutput: 8 VEH
 SG_ EPBL_filteredCurrentCalSP m1 : 52|12@1+ (0.01,0) [0|40.95] "A"  X
 SG_ EPBL_pid_error m1 : 40|12@1+ (0.016997132,-37.55274262) [-37.55274|32.05051] "A"  X
 SG_ EPBL_currentVariance m0 : 40|14@1- (3.0517578125e-05,0) [-0.25|0.24997] "A"  X
 SG_ EPBL_atEndStop m0 : 37|1@1+ (1,0) [0|1] ""  X
 SG_ EPBL_learnedBrakeHWType m0 : 35|2@1+ (1,0) [0|2] ""  X
 SG_ EPBL_diBrakeActive m0 : 34|1@1+ (1,0) [0|1] ""  X
 SG_ EPBL_diStandStill m0 : 33|1@1+ (1,0) [0|1] ""  X
 SG_ EPBL_nFault m0 : 32|1@1+ (1,0) [0|1] ""  X
 SG_ EPBL_brakeDiscWipeAccumul m2 : 32|28@1+ (1,0) [0|268435455] ""  X
 SG_ EPBL_ramp m1 : 32|8@1+ (0.392157,0) [0|100.00004] "%"  X
 SG_ EPBL_lockoutCommandDI m2 : 29|1@1+ (1,0) [0|1] ""  gtw
 SG_ EPBL_caliperState m0 : 29|3@1+ (1,0) [0|5] ""  X
 SG_ EPBL_lockoutOutputDI m2 : 28|1@1+ (1,0) [0|1] ""  gtw
 SG_ EPBL_pid_duty m1 : 22|10@1- (0.2,0) [-102.4|102.2] "%"  X
 SG_ EPBL_pvFilt m0 : 20|9@1+ (0.043549408784,0) [0|22.25375] "V"  X
 SG_ EPBL_filteredCurrentPeak m2 : 16|12@1+ (0.01,0) [0|40.95] "A"  gtw
 SG_ EPBL_pid_uI m1 : 12|10@1- (0.2,0) [-102.4|102.2] "A"  X
 SG_ EPBL_nvFilt m0 : 11|9@1+ (0.043549408784,0) [0|22.25375] "V"  X
 SG_ EPBL_currentOffset m2 : 2|12@1+ (0.016997132,-37.55274262) [-37.55274|32.05051] "A"  X
 SG_ EPBL_12VFilt_SW m0 : 2|9@1+ (0.043549408784,0) [0|22.25375] "V"  X
 SG_ EPBL_pid_uP m1 : 2|10@1- (0.2,0) [-102.4|102.2] "A"  X
 SG_ EPBL_debugOutput M : 0|2@1+ (1,0) [0|2] ""  X

BO_ 1552 UDS_hvpRequest: 8 VEH
 SG_ UDS_hvpRequestData : 7|64@0+ (1,0) [0|18446744073709551615] ""  bms

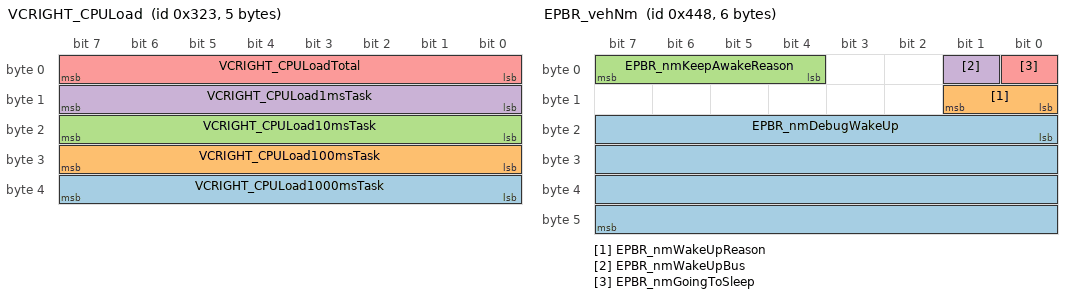
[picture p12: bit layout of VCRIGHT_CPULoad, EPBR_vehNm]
BO_ 803 VCRIGHT_CPULoad: 5 VEH
 SG_ VCRIGHT_CPULoad1000msTask : 32|8@1+ (1,0) [0|255] ""  X
 SG_ VCRIGHT_CPULoad100msTask : 24|8@1+ (1,0) [0|255] ""  X
 SG_ VCRIGHT_CPULoad10msTask : 16|8@1+ (1,0) [0|255] ""  X
 SG_ VCRIGHT_CPULoad1msTask : 8|8@1+ (1,0) [0|255] ""  X
 SG_ VCRIGHT_CPULoadTotal : 0|8@1+ (1,0) [0|255] ""  X

BO_ 1554 BMS_udsResponse: 8 VEH
 SG_ BMS_udsResponseData : 7|64@0+ (1,0) [0|18446744073709551615] ""  gtw

BO_ 1342 CP_info: 8 VEH
 SG_ CP_componentId m10 : 48|16@1+ (1,0) [0|65535] ""  gtw
 SG_ CP_subUsageId m11 : 48|16@1+ (1,0) [0|65535] ""  gtw
 SG_ CP_hardwareId m10 : 32|16@1+ (1,0) [0|65535] ""  gtw
 SG_ CP_bootCrc m20 : 32|32@1+ (1,0) [0|4294967295] ""  gtw
 SG_ CP_appCrc m13 : 32|32@1+ (1,0) [0|4294967295] ""  gtw
 SG_ CP_usageId m11 : 32|16@1+ (1,0) [0|65535] ""  gtw
 SG_ CP_assemblyId m11 : 24|8@1+ (1,0) [0|255] ""  gtw
 SG_ CP_pcbaId m11 : 16|8@1+ (1,0) [0|255] ""  gtw
 SG_ CP_buildConfigId m10 : 16|16@1+ (1,0) [0|65535] ""  gtw
 SG_ CP_platformType m13 : 8|8@1+ (1,0) [0|255] ""  gtw
 SG_ CP_bootUdsProtoVersion m20 : 8|8@1+ (1,0) [0|255] ""  gtw
 SG_ CP_appGitHash m17 : 8|56@1+ (1,0) [0|72057594037927935] ""  gtw
 SG_ CP_buildType m10 : 8|3@1+ (1,0) [0|4] ""  gtw
 SG_ CP_bootGitHash m18 : 8|56@1+ (1,0) [0|72057594037927935] ""  gtw
 SG_ CP_infoIndex M : 0|8@1+ (1,0) [0|255] ""  gtw

BO_ 611 VCRIGHT_logging10Hz: 8 VEH
 SG_ VCRIGHT_hvacFlashFoggingDetected m2 : 63|1@1+ (1,0) [0|1] ""  gtw
 SG_ VCRIGHT_hvacIntakeTarget m0 : 56|8@1+ (0.4,0) [0|100] "%"  gtw
 SG_ VCRIGHT_hvacIntakePosition m1 : 56|8@1+ (0.4,0) [0|100] "%"  gtw
 SG_ VCRIGHT_hvacCabinHumidityLevel m2 : 55|8@1+ (1,0) [0|100] "%"  gtw
 SG_ VCRIGHT_hvacLowerModePosition m1 : 48|8@1+ (0.4,0) [0|100] "%"  gtw
 SG_ VCRIGHT_hvacLowerModeTarget m0 : 48|8@1+ (0.4,0) [0|100] "%"  gtw
 SG_ VCRIGHT_hvacFoggingRiskLevel m2 : 47|8@1+ (1,0) [0|100] "%"  gtw
 SG_ VCRIGHT_hvacUpperModeTarget m0 : 40|8@1+ (0.4,0) [0|100] "%"  gtw
 SG_ VCRIGHT_hvacUpperModePosition m1 : 40|8@1+ (0.4,0) [0|100] "%"  gtw
 SG_ VCRIGHT_hvacEstimateWindshieldRH m2 : 39|8@1+ (1,0) [0|150] "%"  gtw
 SG_ VCRIGHT_hvacRHVaneTarget m0 : 32|8@1+ (0.4,0) [0|100] "%"  gtw
 SG_ VCRIGHT_hvacRHVanePosition m1 : 32|8@1+ (0.4,0) [0|100] "%"  gtw
 SG_ VCRIGHT_timeLeftToCabinModelInit m2 : 32|7@1+ (1,0) [0|127] ""  gtw
 SG_ VCRIGHT_hvacModelInitStatus m2 : 29|3@1+ (1,0) [0|5] ""  gtw
 SG_ VCRIGHT_hvacIntakeActuatorState m2 : 27|2@1+ (1,0) [0|2] ""  gtw
 SG_ VCRIGHT_hvacLowerModeActState m2 : 25|2@1+ (1,0) [0|2] ""  gtw
 SG_ VCRIGHT_hvacLHVanePosition m1 : 24|8@1+ (0.4,0) [0|100] "%"  gtw
 SG_ VCRIGHT_hvacLHVaneTarget m0 : 24|8@1+ (0.4,0) [0|100] "%"  gtw
 SG_ VCRIGHT_hvacUpperModeActState m2 : 23|2@1+ (1,0) [0|2] ""  gtw
 SG_ VCRIGHT_hvacRHVaneActuatorState m2 : 21|2@1+ (1,0) [0|2] ""  gtw
 SG_ VCRIGHT_hvacLHVaneActuatorState m2 : 19|2@1+ (1,0) [0|2] ""  gtw
 SG_ VCRIGHT_hvacRHBleedActuatorState m2 : 17|2@1+ (1,0) [0|2] ""  gtw
 SG_ VCRIGHT_hvacRHBleedPosition m1 : 16|8@1+ (0.4,0) [0|100] "%"  gtw
 SG_ VCRIGHT_hvacRHBleedTarget m0 : 16|8@1+ (0.4,0) [0|100] "%"  gtw
 SG_ VCRIGHT_hvacLHBleedActuatorState m2 : 15|2@1+ (1,0) [0|2] ""  gtw
 SG_ VCRIGHT_hvacIntakeOperationMode m2 : 14|1@1+ (1,0) [0|1] ""  gtw
 SG_ VCRIGHT_hvacLowerModeOpMode m2 : 13|1@1+ (1,0) [0|1] ""  gtw
 SG_ VCRIGHT_hvacUpperModeOpMode m2 : 12|1@1+ (1,0) [0|1] ""  gtw
 SG_ VCRIGHT_hvacRHVaneOperationMode m2 : 11|1@1+ (1,0) [0|1] ""  gtw
 SG_ VCRIGHT_hvacLHVaneOperationMode m2 : 10|1@1+ (1,0) [0|1] ""  gtw
 SG_ VCRIGHT_hvacRHBleedOperationMode m2 : 9|1@1+ (1,0) [0|1] ""  gtw
 SG_ VCRIGHT_hvacLHBleedPosition m1 : 8|8@1+ (0.4,0) [0|100] "%"  gtw
 SG_ VCRIGHT_hvacLHBleedTarget m0 : 8|8@1+ (0.4,0) [0|100] "%"  gtw
 SG_ VCRIGHT_hvacLHBleedOperationMode m2 : 8|1@1+ (1,0) [0|1] ""  gtw
 SG_ VCRIGHT_logging10HzIndex M : 0|2@1+ (1,0) [0|3] ""  X

BO_ 932 PCS_alertMatrix: 8 VEH
 SG_ PCS_a060_chgInputOvPeak m0 : 63|1@1+ (1,0) [0|1] ""  gtw
 SG_ PCS_a059_chgInputOvRms m0 : 62|1@1+ (1,0) [0|1] ""  gtw
 SG_ PCS_a058_chgInputUnderFreq m0 : 61|1@1+ (1,0) [0|1] ""  gtw
 SG_ PCS_a057_chgInputOverFreq m0 : 60|1@1+ (1,0) [0|1] ""  gtw
 SG_ PCS_a056_chgLineImedanceTooHigh m0 : 59|1@1+ (1,0) [0|1] ""  gtw
 SG_ PCS_a055_chgLineImedanceHigh m0 : 58|1@1+ (1,0) [0|1] ""  gtw
 SG_ PCS_a054_chgInputVDropTooHigh m0 : 57|1@1+ (1,0) [0|1] ""  gtw
 SG_ PCS_a053_chgInputVDropHigh m0 : 56|1@1+ (1,0) [0|1] ""  gtw
 SG_ PCS_a052_acVoltageNotPresent m0 : 55|1@1+ (1,0) [0|1] ""  gtw
 SG_ PCS_a051_chgIntBusUv m0 : 54|1@1+ (1,0) [0|1] ""  gtw
 SG_ PCS_a050_dcdc12VsupportFaulted m0 : 53|1@1+ (1,0) [0|1] ""  gtw
 SG_ PCS_a049_dcdcTempRationality m0 : 52|1@1+ (1,0) [0|1] ""  gtw
 SG_ PCS_a048_lvBusHighImpedance m0 : 51|1@1+ (1,0) [0|1] ""  gtw
 SG_ PCS_a047_lvBusLowImpedance m0 : 50|1@1+ (1,0) [0|1] ""  gtw
 SG_ PCS_a046_hvBusHighImpedence m0 : 49|1@1+ (1,0) [0|1] ""  gtw
 SG_ PCS_a045_hvBusLowImpedance m0 : 48|1@1+ (1,0) [0|1] ""  gtw
 SG_ PCS_a044_12vSupportRegulation m0 : 47|1@1+ (1,0) [0|1] ""  gtw
 SG_ PCS_a043_hvBusPrechargeFailure m0 : 46|1@1+ (1,0) [0|1] ""  gtw
 SG_ PCS_a042_dcdcEnableLineMismatch m0 : 45|1@1+ (1,0) [0|1] ""  gtw
 SG_ PCS_a041_dcdcOverTemp m0 : 44|1@1+ (1,0) [0|1] ""  gtw
 SG_ PCS_a040_dcdcMaxPowerReached m0 : 43|1@1+ (1,0) [0|1] ""  gtw
 SG_ PCS_a039_sdModuleClkFault m0 : 42|1@1+ (1,0) [0|1] ""  gtw
 SG_ PCS_a038_claFaulted m0 : 41|1@1+ (1,0) [0|1] ""  gtw
 SG_ PCS_a037_resonantTankOc m0 : 40|1@1+ (1,0) [0|1] ""  gtw
 SG_ PCS_a036_lvBusOv m0 : 39|1@1+ (1,0) [0|1] ""  gtw
 SG_ PCS_a035_lvBusUv m0 : 38|1@1+ (1,0) [0|1] ""  gtw
 SG_ PCS_a034_hvBusOv m0 : 37|1@1+ (1,0) [0|1] ""  gtw
 SG_ PCS_a033_hvBusUv m0 : 36|1@1+ (1,0) [0|1] ""  gtw
 SG_ PCS_a032_unused m0 : 35|1@1+ (1,0) [0|1] ""  gtw
 SG_ PCS_a091_chgIntBusRationality m1 : 34|1@1+ (1,0) [0|1] ""  gtw
 SG_ PCS_a031_uiMia m0 : 34|1@1+ (1,0) [0|1] ""  gtw
 SG_ PCS_a090_expectedAcVoltageSource m1 : 33|1@1+ (1,0) [0|1] ""  gtw
 SG_ PCS_a030_canRationality m0 : 33|1@1+ (1,0) [0|1] ""  gtw
 SG_ PCS_a089_hvBusDischargeIrrationa m1 : 32|1@1+ (1,0) [0|1] ""  gtw
 SG_ PCS_a029_chgPowerRationality m0 : 32|1@1+ (1,0) [0|1] ""  gtw
 SG_ PCS_a088_pchgParameters m1 : 31|1@1+ (1,0) [0|1] ""  gtw
 SG_ PCS_a028_chgOutputUv m0 : 31|1@1+ (1,0) [0|1] ""  gtw
 SG_ PCS_a087_nvramRecordStatusError m1 : 30|1@1+ (1,0) [0|1] ""  gtw
 SG_ PCS_a027_chgInsufficientCooling m0 : 30|1@1+ (1,0) [0|1] ""  gtw
 SG_ PCS_a086_dcdcInsufficientCooling m1 : 29|1@1+ (1,0) [0|1] ""  gtw
 SG_ PCS_a026_watchdogAlarmed m0 : 29|1@1+ (1,0) [0|1] ""  gtw
 SG_ PCS_a025_cpu2Malfunction m0 : 28|1@1+ (1,0) [0|1] ""  gtw
 SG_ PCS_a085_dcdcFetsNotSwitching m1 : 28|1@1+ (1,0) [0|1] ""  gtw
 SG_ PCS_a084_unused m1 : 27|1@1+ (1,0) [0|1] ""  gtw
 SG_ PCS_a024_vcfrontMia m0 : 27|1@1+ (1,0) [0|1] ""  gtw
 SG_ PCS_a023_cpMia m0 : 26|1@1+ (1,0) [0|1] ""  gtw
 SG_ PCS_a083_triggerOdin m1 : 26|1@1+ (1,0) [0|1] ""  gtw
 SG_ PCS_a022_bmsMia m0 : 25|1@1+ (1,0) [0|1] ""  gtw
 SG_ PCS_a082_dcdcPchgUnsafeDiVoltage m1 : 25|1@1+ (1,0) [0|1] ""  gtw
 SG_ PCS_a021_hvpMia m0 : 24|1@1+ (1,0) [0|1] ""  gtw
 SG_ PCS_a081_dcdcPchgTimeout m1 : 24|1@1+ (1,0) [0|1] ""  gtw
 SG_ PCS_a080_damagedPhaseDetected m1 : 23|1@1+ (1,0) [0|1] ""  gtw
 SG_ PCS_a020_chgEnableLineMismatch m0 : 23|1@1+ (1,0) [0|1] ""  gtw
 SG_ PCS_a019_acChargePowerLimited m0 : 22|1@1+ (1,0) [0|1] ""  gtw
 SG_ PCS_a079_eepromOperationError m1 : 22|1@1+ (1,0) [0|1] ""  gtw
 SG_ PCS_a018_chgUnknownGridConfig m0 : 21|1@1+ (1,0) [0|1] ""  gtw
 SG_ PCS_a078_chgStopDcdcTooHot m1 : 21|1@1+ (1,0) [0|1] ""  gtw
 SG_ PCS_a077_microGridEnergyLow m1 : 20|1@1+ (1,0) [0|1] ""  gtw
 SG_ PCS_a017_chgWallPowerRemoval m0 : 20|1@1+ (1,0) [0|1] ""  gtw
 SG_ PCS_a016_chgAllPhasesFaulted m0 : 19|1@1+ (1,0) [0|1] ""  gtw
 SG_ PCS_a076_dcdcEnDeassertedErr m1 : 19|1@1+ (1,0) [0|1] ""  gtw
 SG_ PCS_a075_hvBusDischargeTimeout m1 : 18|1@1+ (1,0) [0|1] ""  gtw
 SG_ PCS_a015_chg12vUv m0 : 18|1@1+ (1,0) [0|1] ""  gtw
 SG_ PCS_a014_chgTempRationality m0 : 17|1@1+ (1,0) [0|1] ""  gtw
 SG_ PCS_a074_hvBusDischargeFailure m1 : 17|1@1+ (1,0) [0|1] ""  gtw
 SG_ PCS_a073_unexpectedAcInputVoltag m1 : 16|1@1+ (1,0) [0|1] ""  gtw
 SG_ PCS_a013_chgPrechargeFailedBoost m0 : 16|1@1+ (1,0) [0|1] ""  gtw
 SG_ PCS_a012_chgPfcIBandTracerFault m0 : 15|1@1+ (1,0) [0|1] ""  gtw
 SG_ PCS_a072_cpu2ClaStopped m1 : 15|1@1+ (1,0) [0|1] ""  gtw
 SG_ PCS_a011_chgLlcCurrentRegulation m0 : 14|1@1+ (1,0) [0|1] ""  gtw
 SG_ PCS_a071_chgPfcILoopRationality m1 : 14|1@1+ (1,0) [0|1] ""  gtw
 SG_ PCS_a070_chgPfcLineDvdt m1 : 13|1@1+ (1,0) [0|1] ""  gtw
 SG_ PCS_a010_chgIntBusVRegulation m0 : 13|1@1+ (1,0) [0|1] ""  gtw
 SG_ PCS_a009_chgPfcCurrentRegulation m0 : 12|1@1+ (1,0) [0|1] ""  gtw
 SG_ PCS_a069_chgPfcLineDidt m1 : 12|1@1+ (1,0) [0|1] ""  gtw
 SG_ PCS_a008_chgPhaseOverTemp m0 : 11|1@1+ (1,0) [0|1] ""  gtw
 SG_ PCS_a068_dcdcTankvRationality m1 : 11|1@1+ (1,0) [0|1] ""  gtw
 SG_ PCS_a007_chgPhaseTempHot m0 : 10|1@1+ (1,0) [0|1] ""  gtw
 SG_ PCS_a067_dcdcLvRationality m1 : 10|1@1+ (1,0) [0|1] ""  gtw
 SG_ PCS_a006_chgPrechargeFailedScr m0 : 9|1@1+ (1,0) [0|1] ""  gtw
 SG_ PCS_a066_dcdcHvRationality m1 : 9|1@1+ (1,0) [0|1] ""  gtw
 SG_ PCS_a065_chgPllNotLocked m1 : 8|1@1+ (1,0) [0|1] ""  gtw
 SG_ PCS_a005_chgOutputOv m0 : 8|1@1+ (1,0) [0|1] ""  gtw
 SG_ PCS_a064_chgIOutRationality m1 : 7|1@1+ (1,0) [0|1] ""  gtw
 SG_ PCS_a004_chgHwIntBusOv m0 : 7|1@1+ (1,0) [0|1] ""  gtw
 SG_ PCS_a063_chgVOutRationality m1 : 6|1@1+ (1,0) [0|1] ""  gtw
 SG_ PCS_a003_chgHwInputOv m0 : 6|1@1+ (1,0) [0|1] ""  gtw
 SG_ PCS_a002_chgHwOutputOc m0 : 5|1@1+ (1,0) [0|1] ""  gtw
 SG_ PCS_a062_chgILineRationality m1 : 5|1@1+ (1,0) [0|1] ""  gtw
 SG_ PCS_a001_chgHwInputOc m0 : 4|1@1+ (1,0) [0|1] ""  gtw
 SG_ PCS_a061_chgVLineRationality m1 : 4|1@1+ (1,0) [0|1] ""  gtw
 SG_ PCS_matrixIndex M : 0|4@1+ (1,0) [0|15] ""  gtw

BO_ 1925 DBG_dynoOpenLoop: 8 VEH
 SG_ DBG_dynoOLGeneric8BitSignal7 m8 : 56|8@1+ (0.0039215687,0) [0|1] "1"  di
 SG_ DBG_dynoOLGeneric14BitSignal4 m7 : 50|14@1+ (6.1038881768e-05,0) [0|1] "1"  di
 SG_ DBG_dynoOLsineIAngleOffset m2 : 48|16@1- (9.58737992428526e-05,0) [-3.14159|3.1415] "rad"  di
 SG_ DBG_dynoOLsineVAngleOffset m4 : 48|16@1- (9.58737992428526e-05,0) [-3.14159|3.1415] "rad"  di
 SG_ DBG_dynoOLsineMAngleOffset m3 : 48|16@1- (9.58737992428526e-05,0) [-3.14159|3.1415] "rad"  di
 SG_ DBG_dynoOLParamScaleFactor3 m6 : 48|16@1+ (3.0517578125e-05,0) [0|2] "1"  di
 SG_ DBG_dynoOLGeneric8BitSignal6 m8 : 48|8@1+ (0.0039215687,0) [0|1] "1"  di
 SG_ DBG_dynoOLGeneric8BitSignal5 m8 : 40|8@1+ (0.0039215687,0) [0|1] "1"  di
 SG_ DBG_dynoOLGeneric14BitSignal3 m7 : 36|14@1+ (6.1038881768e-05,0) [0|1] "1"  di
 SG_ DBG_dynoOLsineMModIndexMag m3 : 32|16@1+ (1.52587890625e-05,0) [0|0.99998] "mindex"  di
 SG_ DBG_dynoOLGeneric8BitSignal4 m8 : 32|8@1+ (0.0039215687,0) [0|1] "1"  di
 SG_ DBG_dynoOLsineVVoltageMag m4 : 32|16@1+ (0.00762939453125,0) [0|499.99237] "V"  di
 SG_ DBG_dynoOLsineTTorqueMag m1 : 32|16@1+ (0.01068115234375,0) [0|700] "Nm"  di
 SG_ DBG_dynoOLParamScaleFactor2 m6 : 32|16@1+ (3.0517578125e-05,0) [0|2] "1"  di
 SG_ DBG_dynoOLsineICurrentMag m2 : 32|16@1+ (0.0274658203125,0) [0|1799.97253] "A"  di
 SG_ DBG_dynoOLGeneric8BitSignal3 m8 : 24|8@1+ (0.0039215687,0) [0|1] "1"  di
 SG_ DBG_dynoOLGeneric14BitSignal2 m7 : 22|14@1+ (6.1038881768e-05,0) [0|1] "1"  di
 SG_ DBG_dynoOLIQmaxTableOffset m5 : 16|16@1- (0.054931640625,0) [-1800|1799.94507] "A"  di
 SG_ DBG_dynoOLGeneric8BitSignal2 m8 : 16|8@1+ (0.0039215687,0) [0|1] "1"  di
 SG_ DBG_dynoOLParamScaleFactor1 m6 : 16|16@1+ (3.0517578125e-05,0) [0|2] "1"  di
 SG_ DBG_dynoOLsineTFrequency m1 : 16|16@1+ (0.00762939453125,0) [0|500] "Hz"  di
 SG_ DBG_dynoOLParamTuneSelector3 m6 : 13|3@1+ (1,0) [0|5] ""  di
 SG_ DBG_dynoOLParamTuneSelector2 m6 : 10|3@1+ (1,0) [0|5] ""  di
 SG_ DBG_dynoOLGeneric14BitSignal1 m7 : 8|14@1+ (6.1038881768e-05,0) [0|1] "1"  di
 SG_ DBG_dynoOLsineIFrequency m2 : 8|22@1- (0.00473804920399432,0) [-9936.40936|9936.40463] "Hz"  di
 SG_ DBG_dynoOLsineVFrequency m4 : 8|22@1- (0.00473804920399432,0) [-9936.40936|9936.40463] "Hz"  di
 SG_ DBG_dynoOLsineMFrequency m3 : 8|22@1- (0.00473804920399432,0) [-9936.40936|9936.40463] "Hz"  di
 SG_ DBG_dynoOLGeneric8BitSignal1 m8 : 8|8@1+ (0.0039215687,0) [0|1] "1"  di
 SG_ DBG_dynoOLParamTuneSelector1 m6 : 7|3@1+ (1,0) [0|5] ""  di
 SG_ DBG_dynoOLsineMPolarInputFlag m3 : 7|1@1+ (1,0) [0|1] ""  di
 SG_ DBG_dynoOLGeneric14BitFlag2 m7 : 7|1@1+ (1,0) [0|1] ""  di
 SG_ DBG_dynoOLsineVPolarInputFlag m4 : 7|1@1+ (1,0) [0|1] ""  di
 SG_ DBG_dynoOLGeneric8BitFlag2 m8 : 7|1@1+ (1,0) [0|1] ""  di
 SG_ DBG_dynoOLsineINoRotorSync m2 : 7|1@1+ (1,0) [0|1] ""  di
 SG_ DBG_dynoOLGeneric8BitFlag1 m8 : 6|1@1+ (1,0) [0|1] ""  di
 SG_ DBG_dynoOLsineMNoRotorSync m3 : 6|1@1+ (1,0) [0|1] ""  di
 SG_ DBG_dynoOLGenSineTFlag m1 : 6|1@1+ (1,0) [0|1] ""  di
 SG_ DBG_dynoOLsineIPolarInputFlag m2 : 6|1@1+ (1,0) [0|1] ""  di
 SG_ DBG_dynoOLIQmaxTuneFlag m5 : 6|1@1+ (1,0) [0|1] ""  di
 SG_ DBG_dynoOLNoParamSatFlag m6 : 6|1@1+ (1,0) [0|1] ""  di
 SG_ DBG_dynoOLGeneric14BitFlag1 m7 : 6|1@1+ (1,0) [0|1] ""  di
 SG_ DBG_dynoOLsineVNoRotorSync m4 : 6|1@1+ (1,0) [0|1] ""  di
 SG_ DBG_dynoOLSelector M : 0|4@1+ (1,0) [0|8] ""  di

BO_ 1885 CP_sensorData: 8 VEH
 SG_ CP_proxEn m8 : 57|1@1+ (1,0) [0|1] ""  gtw
 SG_ CP_proxConn1Sense m8 : 56|1@1+ (1,0) [0|1] ""  gtw
 SG_ CP_UHF_selfTestRssi m6 : 40|8@1+ (1,0) [0|255] ""  gtw
 SG_ CP_proximityV_intervalMax10s m8 : 40|16@1+ (0.0001,0) [0|6.5535] "V"  gtw
 SG_ CP_pilotHighValue m9 : 40|12@1- (0.01,0) [-20.48|20.47] "V"  X
 SG_ CP_pilotHighValue_intervalMin10s m10 : 40|12@1- (0.01,0) [-20.48|20.47] "V"  gtw
 SG_ CP_UHF_fifoData m6 : 32|8@1+ (1,0) [0|255] ""  X
 SG_ CP_pilotHighValue_intervalMax10s m10 : 28|12@1- (0.01,0) [-20.48|20.47] "V"  gtw
 SG_ CP_pilotLowValue m9 : 28|12@1- (0.01,0) [-20.48|20.47] "V"  X
 SG_ CP_doorLastRequestMaxI m2 : 28|12@1+ (0.0025,0) [0|10.2375] "A"  gtw
 SG_ CP_doorCountsDebounced m0 : 24|16@1+ (0.00152590219,0) [0|100.00000002165] "%"  X
 SG_ CP_pinTemperature3 m1 : 24|8@1+ (0.8039215686,-55) [-55|150] "C"  dbg
 SG_ CP_UHF_rxNumBytes m6 : 24|8@1+ (1,0) [0|255] ""  X
 SG_ CP_proximityV_intervalMin10s m8 : 24|16@1+ (0.0001,0) [0|6.5535] "V"  gtw
 SG_ CP_pinTemperature2 m1 : 16|8@1+ (0.8039215686,-55) [-55|150] "C"  dbg
 SG_ CP_latch2I m3 : 16|12@1+ (0.0025,0) [0|10.2375] "A"  X
 SG_ CP_pilotPeriod m9 : 16|12@1+ (1,0) [0|4095] ""  gtw
 SG_ CP_UHF_rxOverflow m6 : 16|1@1+ (1,0) [0|1] ""  X
 SG_ CP_doorI m2 : 16|12@1+ (0.0025,0) [0|10.2375] "A"  X
 SG_ CP_pilotLowValue_intervalMin10s m10 : 16|12@1- (0.01,0) [-20.48|20.47] "V"  X
 SG_ CP_pinTemperature1 m1 : 8|8@1+ (0.8039215686,-55) [-55|150] "C"  dbg
 SG_ CP_UHF_rssi m6 : 8|8@1+ (1,0) [0|255] ""  gtw
 SG_ CP_doorCountsFiltered m0 : 8|16@1+ (0.00152590219,0) [0|100.00000002165] "%"  X
 SG_ CP_refVoltage m7 : 8|8@1+ (0.0070588235,0) [0|1.8] "V"  X
 SG_ CP_proximityV m8 : 8|16@1+ (0.0001,0) [0|6.5535] "V"  X
 SG_ CP_faultLineV m5 : 4|12@1+ (0.00114,0) [0|4.65524] "V"  X
 SG_ CP_pilotLowValue_intervalMax10s m10 : 4|12@1- (0.01,0) [-20.48|20.47] "V"  gtw
 SG_ CP_UHF_chipState m6 : 4|3@1+ (1,0) [0|7] ""  X
 SG_ CP_inductiveSensor_raw m4 : 4|28@1+ (1,0) [0|268435455] ""  gtw
 SG_ CP_doorPot m2 : 4|12@1+ (0.025,0) [0|100] "%"  dbg
 SG_ CP_pilotPulseWidth m9 : 4|12@1+ (1,0) [0|4095] ""  gtw
 SG_ CP_latchI m3 : 4|12@1+ (0.0025,0) [0|10.2375] "A"  X
 SG_ CP_sensorDataSelect M : 0|4@1+ (1,0) [0|10] ""  dbg

BO_ 626 VCLEFT_epbmDebug: 8 VEH
 SG_ VCLEFT_epbFaultStatus m0 : 61|2@1+ (1,0) [0|3] ""  gtw
 SG_ VCLEFT_epbmFaultStatus m0 : 59|2@1+ (1,0) [0|3] ""  gtw
 SG_ VCLEFT_epbUnitStatus m0 : 54|5@1+ (1,0) [0|21] ""  gtw
 SG_ VCLEFT_epbmUnitStatus m0 : 49|5@1+ (1,0) [0|21] ""  gtw
 SG_ VCLEFT_epbmSummonState m0 : 46|3@1+ (1,0) [0|6] ""  gtw
 SG_ VCLEFT_epbSummonState m0 : 43|3@1+ (1,0) [0|6] ""  gtw
 SG_ VCLEFT_summonFaultReason m0 : 38|5@1+ (1,0) [0|28] ""  gtw
 SG_ VCLEFT_epbmReleaseVoltage m0 : 27|11@1+ (0.01,0) [0|20.47] "A"  X
 SG_ VCLEFT_cdpEnumDummy m1 : 24|2@1+ (1,0) [0|2] ""  X
 SG_ VCLEFT_summonUnavailableAllowed m1 : 22|1@1+ (1,0) [0|1] ""  X
 SG_ VCLEFT_summonFaultAllowed m1 : 21|1@1+ (1,0) [0|1] ""  X
 SG_ VCLEFT_summonCompleteAllowed m1 : 20|1@1+ (1,0) [0|1] ""  X
 SG_ VCLEFT_summonActiveAllowed m1 : 19|1@1+ (1,0) [0|1] ""  X
 SG_ VCLEFT_summonArmedAllowed m1 : 18|1@1+ (1,0) [0|1] ""  X
 SG_ VCLEFT_summonIdleAllowed m1 : 17|1@1+ (1,0) [0|1] ""  X
 SG_ VCLEFT_epbmApplyVoltage m0 : 16|11@1+ (0.01,0) [0|20.47] "A"  X
 SG_ VCLEFT_epbmUnknownAllowed m1 : 16|1@1+ (1,0) [0|1] ""  X
 SG_ VCLEFT_summonInitAllowed m1 : 15|1@1+ (1,0) [0|1] ""  X
 SG_ VCLEFT_epbmSummonReleaseAllowed m1 : 14|1@1+ (1,0) [0|1] ""  X
 SG_ VCLEFT_epbmSummonParkAllowed m1 : 13|1@1+ (1,0) [0|1] ""  X
 SG_ VCLEFT_epbmSummonAllowed m1 : 12|1@1+ (1,0) [0|1] ""  X
 SG_ VCLEFT_epbmFaultAllowed m1 : 11|1@1+ (1,0) [0|1] ""  X
 SG_ VCLEFT_epbmReleasingAllowed m1 : 10|1@1+ (1,0) [0|1] ""  X
 SG_ VCLEFT_epbmDynApplyingAllowed m1 : 9|1@1+ (1,0) [0|1] ""  X
 SG_ VCLEFT_epbmParkingAllowed m1 : 8|1@1+ (1,0) [0|1] ""  X
 SG_ VCLEFT_epbmWinchReleaseAllowed m1 : 7|1@1+ (1,0) [0|1] ""  X
 SG_ VCLEFT_epbmWinchAllowed m1 : 6|1@1+ (1,0) [0|1] ""  X
 SG_ VCLEFT_epbmServiceAllowed m1 : 5|1@1+ (1,0) [0|1] ""  X
 SG_ VCLEFT_epbMotorCurrent m0 : 5|11@1+ (0.01,0) [0|20.47] "A"  X
 SG_ VCLEFT_epbmStartAllowed m1 : 4|1@1+ (1,0) [0|1] ""  X
 SG_ VCLEFT_epbmMotorEnabled m0 : 4|1@1+ (1,0) [0|1] ""  X
 SG_ VCLEFT_epbmParkAllowed m1 : 3|1@1+ (1,0) [0|1] ""  X
 SG_ VCLEFT_epbmDynamicAllowed m1 : 2|1@1+ (1,0) [0|1] ""  X
 SG_ VCLEFT_epbmOpenAllowed m1 : 1|1@1+ (1,0) [0|1] ""  X
 SG_ VCLEFT_epbmCaliperState m0 : 1|3@1+ (1,0) [0|5] ""  X
 SG_ VCLEFT_epbmDebugIndex M : 0|1@1+ (1,0) [0|1] ""  X

BO_ 958 FC_alertMatrix5: 8 VEH
 SG_ FC_a312_GB_evseLimitsTimeout : 55|1@1+ (1,0) [0|1] ""  gtw
 SG_ FC_a311_GB_battParamsTimeout : 54|1@1+ (1,0) [0|1] ""  gtw
 SG_ FC_a310_GB_vehicleIdTimeout : 53|1@1+ (1,0) [0|1] ""  gtw
 SG_ FC_a309_GB_unused : 52|1@1+ (1,0) [0|1] ""  gtw
 SG_ FC_a308_GB_evseConLockTimeout : 51|1@1+ (1,0) [0|1] ""  gtw
 SG_ FC_a307_GB_fcContOpenTimeout : 50|1@1+ (1,0) [0|1] ""  gtw
 SG_ FC_a306_GB_vehReadyDeasserted : 49|1@1+ (1,0) [0|1] ""  gtw
 SG_ FC_a305_GB_posRecogTimeout : 48|1@1+ (1,0) [0|1] ""  gtw
 SG_ FC_a304_GB_evseIncompatible : 47|1@1+ (1,0) [0|1] ""  gtw
 SG_ FC_a303_GB_negRecogTimeout : 46|1@1+ (1,0) [0|1] ""  gtw
 SG_ FC_a302_GB_vRegBrownout : 45|1@1+ (1,0) [0|1] ""  gtw
 SG_ FC_a301_GB_chargingProblem : 44|1@1+ (1,0) [0|1] ""  gtw
 SG_ FC_a300_GB_startupProblem : 43|1@1+ (1,0) [0|1] ""  gtw
 SG_ FC_a299_GB_evseReadyTimeout : 42|1@1+ (1,0) [0|1] ""  gtw
 SG_ FC_a298_GB_bmsCtrCloseTimeout : 41|1@1+ (1,0) [0|1] ""  gtw
 SG_ FC_a297_GB_chargingBusTimeout : 40|1@1+ (1,0) [0|1] ""  gtw
 SG_ FC_a296_GB_evseIsoTestTimeout : 39|1@1+ (1,0) [0|1] ""  gtw
 SG_ FC_a295_GB_vehReadyTimeout : 38|1@1+ (1,0) [0|1] ""  gtw
 SG_ FC_a294_GB_evseDataTimeout : 37|1@1+ (1,0) [0|1] ""  gtw
 SG_ FC_a293_GB_ss2LowTimeout : 36|1@1+ (1,0) [0|1] ""  gtw
 SG_ FC_a292_GB_vehConLockTimeout : 35|1@1+ (1,0) [0|1] ""  gtw
 SG_ FC_a291_GB_vehDataTimeout : 34|1@1+ (1,0) [0|1] ""  gtw
 SG_ FC_a290_GB_pilotAcceptTimeout : 33|1@1+ (1,0) [0|1] ""  gtw
 SG_ FC_a289_GB_proxTimeout : 32|1@1+ (1,0) [0|1] ""  gtw
 SG_ FC_a288_GB_isoVoltageLow : 31|1@1+ (1,0) [0|1] ""  gtw
 SG_ FC_a287_GB_vehConnUnlocked : 30|1@1+ (1,0) [0|1] ""  gtw
 SG_ FC_a286_GB_evseConnUnlocked : 29|1@1+ (1,0) [0|1] ""  gtw
 SG_ FC_a285_GB_proxDisconnected : 28|1@1+ (1,0) [0|1] ""  gtw
 SG_ FC_a284_GB_pcbTempHiFoldBk : 27|1@1+ (1,0) [0|1] ""  gtw
 SG_ FC_a283_GB_posTempHiFoldBk : 26|1@1+ (1,0) [0|1] ""  gtw
 SG_ FC_a282_GB_negTempHiFoldBk : 25|1@1+ (1,0) [0|1] ""  gtw
 SG_ FC_a281_GB_ss2Deasserted : 24|1@1+ (1,0) [0|1] ""  gtw
 SG_ FC_a280_GB_unused : 23|1@1+ (1,0) [0|1] ""  gtw
 SG_ FC_a279_GB_evseOverCurrent : 22|1@1+ (1,0) [0|1] ""  gtw
 SG_ FC_a278_GB_unused : 21|1@1+ (1,0) [0|1] ""  gtw
 SG_ FC_a277_GB_posToPcbDeltaLo : 20|1@1+ (1,0) [0|1] ""  gtw
 SG_ FC_a276_GB_negToPcbDeltaLo : 19|1@1+ (1,0) [0|1] ""  gtw
 SG_ FC_a275_GB_posToPcbDeltaHi : 18|1@1+ (1,0) [0|1] ""  gtw
 SG_ FC_a274_GB_negToPcbDeltaHi : 17|1@1+ (1,0) [0|1] ""  gtw
 SG_ FC_a273_GB_negToPosDeltaLo : 16|1@1+ (1,0) [0|1] ""  gtw
 SG_ FC_a272_GB_negToPosDeltaHi : 15|1@1+ (1,0) [0|1] ""  gtw
 SG_ FC_a271_GB_unused : 14|1@1+ (1,0) [0|1] ""  gtw
 SG_ FC_a270_GB_unused : 13|1@1+ (1,0) [0|1] ""  gtw
 SG_ FC_a269_GB_unused : 12|1@1+ (1,0) [0|1] ""  gtw
 SG_ FC_a268_GB_pcb_OT : 11|1@1+ (1,0) [0|1] ""  gtw
 SG_ FC_a267_GB_posPin_OT : 10|1@1+ (1,0) [0|1] ""  gtw
 SG_ FC_a266_GB_negPin_OT : 9|1@1+ (1,0) [0|1] ""  gtw
 SG_ FC_a265_GB_bmsIncompatible : 8|1@1+ (1,0) [0|1] ""  gtw
 SG_ FC_a264_GB_ss2NotLow : 7|1@1+ (1,0) [0|1] ""  gtw
 SG_ FC_a263_GB_hwProxTrip : 6|1@1+ (1,0) [0|1] ""  gtw
 SG_ FC_a262_GB_evseRxBufOvf : 5|1@1+ (1,0) [0|1] ""  gtw
 SG_ FC_a261_GB_evseTxBufOvf : 4|1@1+ (1,0) [0|1] ""  gtw
 SG_ FC_a260_GB_vehRxBufOvf : 3|1@1+ (1,0) [0|1] ""  gtw
 SG_ FC_a259_GB_vehTxBufOvf : 2|1@1+ (1,0) [0|1] ""  gtw
 SG_ FC_a258_GB_evseMia : 1|1@1+ (1,0) [0|1] ""  gtw
 SG_ FC_a257_GB_bmsMia : 0|1@1+ (1,0) [0|1] ""  gtw

BO_ 1096 EPBR_vehNm: 6 VEH
 SG_ EPBR_nmDebugWakeUp : 16|32@1+ (1,0) [0|4294967295] ""  gtw
 SG_ EPBR_nmWakeUpReason : 8|2@1+ (1,0) [0|3] ""  gtw
 SG_ EPBR_nmKeepAwakeReason : 4|4@1+ (1,0) [0|15] ""  gtw
 SG_ EPBR_nmWakeUpBus : 1|1@1+ (1,0) [0|1] ""  X
 SG_ EPBR_nmGoingToSleep : 0|1@1+ (1,0) [0|1] ""  X

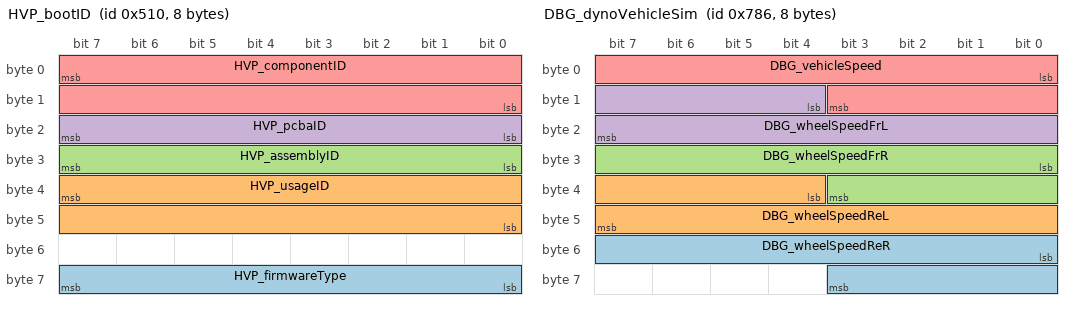
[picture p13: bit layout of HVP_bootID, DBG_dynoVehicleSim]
BO_ 1296 HVP_bootID: 8 VEH
 SG_ HVP_firmwareType : 56|8@1+ (1,0) [0|255] ""  gtwu
 SG_ HVP_usageID : 39|16@0+ (1,0) [0|65535] ""  gtwu
 SG_ HVP_assemblyID : 24|8@1+ (1,0) [0|255] ""  gtwu
 SG_ HVP_pcbaID : 16|8@1+ (1,0) [0|255] ""  gtw
 SG_ HVP_componentID : 7|16@0+ (1,0) [0|65535] ""  gtwu

BO_ 1891 VCRIGHT_xcpResponse: 8 VEH
 SG_ VCRIGHT_xcpResponseData : 0|64@1+ (1,0) [0|18446744073709551615] ""  X

BO_ 421 DIS_motorControl: 8 VEH
 SG_ DIS_limitClutch : 61|1@1+ (1,0) [0|1] ""  gtw
 SG_ DIS_limitStatorFrequency : 60|1@1+ (1,0) [0|1] ""  X
 SG_ DIS_limitOilPumpFluidTemp : 59|1@1+ (1,0) [0|1] ""  X
 SG_ DIS_limitShockTorque : 57|1@1+ (1,0) [0|1] ""  gtw
 SG_ DIS_limitIGBTJunctTemp : 56|1@1+ (1,0) [0|1] ""  gtw
 SG_ DIS_limitGracefulPowerOff : 55|1@1+ (1,0) [0|1] ""  X
 SG_ DIS_limitDiff : 54|1@1+ (1,0) [0|1] ""  gtw
 SG_ DIS_limitMotorSpeed : 52|1@1+ (1,0) [0|1] ""  gtw
 SG_ DIS_limitDcCapTemp : 49|1@1+ (1,0) [0|1] ""  X
 SG_ DIS_limitBaseSpeed : 47|1@1+ (1,0) [0|1] ""  X
 SG_ DIS_limitTCRegen : 45|1@1+ (1,0) [0|1] ""  gtw
 SG_ DIS_limitTCDrive : 44|1@1+ (1,0) [0|1] ""  gtw
 SG_ DIS_limitMotorVoltage : 41|1@1+ (1,0) [0|1] ""  X
 SG_ DIS_limitMotorCurrent : 40|1@1+ (1,0) [0|1] ""  gtw
 SG_ DIS_limitDischargePower : 38|1@1+ (1,0) [0|1] ""  gtw
 SG_ DIS_limitDeltaFluidTemp : 37|1@1+ (1,0) [0|1] ""  X
 SG_ DIS_limitLimpMode : 36|1@1+ (1,0) [0|1] ""  X
 SG_ DIS_limitPoleTemp : 35|1@1+ (1,0) [0|1] ""  gtw
 SG_ DIS_limitStatorTemp : 34|1@1+ (1,0) [0|1] ""  gtw
 SG_ DIS_limitInverterTemp : 33|1@1+ (1,0) [0|1] ""  gtw
 SG_ DIS_limitPCBTemp : 32|1@1+ (1,0) [0|1] ""  X
 SG_ DIS_motorCurrent : 16|11@1+ (1,0) [0|2047] "A"  gtw
 SG_ DIS_vBat : 0|10@1+ (0.5,0) [0|500] "V"  gtw

BO_ 1926 DBG_dynoVehicleSim: 8 VEH
 SG_ DBG_wheelSpeedReR : 48|12@1+ (0.08,-40) [-40|285] "km/h"  di
 SG_ DBG_wheelSpeedReL : 36|12@1+ (0.08,-40) [-40|285] "km/h"  di
 SG_ DBG_wheelSpeedFrR : 24|12@1+ (0.08,-40) [-40|285] "km/h"  di
 SG_ DBG_wheelSpeedFrL : 12|12@1+ (0.08,-40) [-40|285] "km/h"  di
 SG_ DBG_vehicleSpeed : 0|12@1+ (0.08,-40) [-40|285] "km/h"  di

BO_ 642 VCLEFT_hvacBlowerFeedback: 8 VEH
 SG_ VCLEFT_hvacBlowerSpiError m0 : 62|1@1+ (1,0) [0|1] ""  X
 SG_ VCLEFT_hvacBlowerPowerOn m0 : 61|1@1+ (1,0) [0|1] ""  gtw
 SG_ VCLEFT_hvacBlowerLimitFETTemps m0 : 60|1@1+ (1,0) [0|1] ""  gtw
 SG_ VCLEFT_hvacBlowerFault m0 : 59|1@1+ (1,0) [0|1] ""  gtw
 SG_ VCLEFT_hvacBlowerCBCCtrlState m1 : 58|3@1+ (1,0) [0|4] ""  gtw
 SG_ VCLEFT_hvacBlowerInitd m0 : 58|1@1+ (1,0) [0|1] ""  gtw
 SG_ VCLEFT_hvacBlowerCBCEstState m1 : 54|4@1+ (1,0) [0|14] ""  gtw
 SG_ VCLEFT_hvacBlowerITerm m0 : 51|7@1+ (0.05,-1.5) [-1.5|4.5] "Nm"  X
 SG_ VCLEFT_hvacBlower_IO_CBC_numUart m1 : 46|8@1+ (1,0) [0|255] ""  gtw
 SG_ VCLEFT_hvacBlowerFETTemp m0 : 44|7@1+ (1.5,-40) [-40|149] "degC"  gtw
 SG_ VCLEFT_hvacBlower_IO_CBC_Status m1 : 43|1@1+ (1,0) [0|1] ""  gtw
 SG_ VCLEFT_hvacBlower_IO_CBC_TAIL_va m1 : 42|1@1+ (1,0) [0|1] ""  gtw
 SG_ VCLEFT_hvacBlower_IO_CBC_TAIL m1 : 38|4@1+ (1,0) [0|15] ""  gtw
 SG_ VCLEFT_hvacBlower_IO_CBC_HEAD m1 : 34|4@1+ (1,0) [0|15] ""  gtw
 SG_ VCLEFT_hvacBlowerTorque m0 : 34|10@1+ (0.006,-1.5) [-1.5|4.5] "Nm"  gtw
 SG_ VCLEFT_hvacBlowerIPhase2 m1 : 26|8@1+ (0.2,0) [0|50] "A"  gtw
 SG_ VCLEFT_hvacBlowerRPMActual m0 : 20|10@1+ (10,0) [0|10000] "rpm"  gtw
 SG_ VCLEFT_hvacBlowerIPhase1 m1 : 18|8@1+ (0.2,0) [0|50] "A"  gtw
 SG_ VCLEFT_hvacBlowerIPhase0 m1 : 10|8@1+ (0.2,0) [0|50] "A"  gtw
 SG_ VCLEFT_hvacBlowerRPMTarget m0 : 10|10@1+ (10,0) [0|10000] "rpm"  gtw
 SG_ VCLEFT_hvacBlowerOutputDuty m0 : 3|7@1+ (1,0) [0|100] "%"  gtw
 SG_ VCLEFT_hvacBlowerEnabled m0 : 2|1@1+ (1,0) [0|1] ""  gtw
 SG_ VCLEFT_hvacBlowerRs m1 : 2|8@1+ (0.0025,0) [0|0.6] "Ohm"  gtw
 SG_ VCLEFT_blowerIndex M : 0|2@1+ (1,0) [0|1] ""  X

BO_ 525 TAS_states: 8 VEH
 SG_ TAS_statesChecksum : 56|8@1+ (1,0) [0|255] ""  vcfront
 SG_ TAS_statesCounter : 52|4@1+ (1,0) [0|15] ""  vcfront
 SG_ TAS_limpHomeMode : 48|3@1+ (1,0) [0|4] ""  X
 SG_ TAS_targetLevel : 45|3@1+ (1,0) [0|4] ""  X
 SG_ TAS_currentLevel : 42|3@1+ (1,0) [0|4] ""  X
 SG_ TAS_spinnerUI : 41|1@1+ (1,0) [0|1] ""  X
 SG_ TAS_redWarningLamp : 40|1@1+ (1,0) [0|1] ""  X
 SG_ TAS_yellowWarningLamp : 39|1@1+ (1,0) [0|1] ""  X
 SG_ TAS_jackMode : 38|1@1+ (1,0) [0|1] ""  X
 SG_ TAS_veryHighAllowed : 37|1@1+ (1,0) [0|1] ""  X
 SG_ TAS_highAllowed : 36|1@1+ (1,0) [0|1] ""  X
 SG_ TAS_standardAllowed : 35|1@1+ (1,0) [0|1] ""  X
 SG_ TAS_lowAllowed : 34|1@1+ (1,0) [0|1] ""  X
 SG_ TAS_veryLowAllowed : 33|1@1+ (1,0) [0|1] ""  X
 SG_ TAS_leanDetected : 32|1@1+ (1,0) [0|1] ""  X
 SG_ TAS_twistDetected : 31|1@1+ (1,0) [0|1] ""  X
 SG_ TAS_compressorRun : 30|1@1+ (1,0) [0|1] ""  vcfront
 SG_ TAS_filterMode : 27|3@1+ (1,0) [0|7] ""  X
 SG_ TAS_runMode : 24|3@1+ (1,0) [0|6] ""  X
 SG_ TAS_pressureReservoir : 16|8@1+ (0.1,0) [0|25.5] "bar"  X
 SG_ TAS_pressureGallery : 8|8@1+ (0.1,0) [0|25.5] "bar"  X
 SG_ TAS_levelingType : 4|4@1+ (1,0) [0|15] ""  X
 SG_ TAS_levelingState : 0|4@1+ (1,0) [0|12] ""  X

BO_ 986 VCSEC_BLEUnexpectedEvent: 8 VEH
 SG_ VCSEC_BLEUnexpectedEventBytes : 0|64@1+ (1,0) [0|18446744073709551615] ""  gtw

BO_ 1906 BMS_bmbDebugInfo_10Hz: 8 VEH
 SG_ BMS_dieTemperature3 m0 : 48|16@1- (0.01,0) [-327.68|327.67] "C"  dbg
 SG_ BMS_dieTemperature6 m1 : 48|16@1- (0.01,0) [-327.68|327.67] "C"  dbg
 SG_ BMS_BMBHostErrorCount4 m3 : 40|16@1+ (1,0) [0|65535] ""  dbg
 SG_ BMS_BMBDeviceErrorCount5 m6 : 40|16@1+ (1,0) [0|65535] ""  dbg
 SG_ BMS_BMBDeviceErrorCount8 m7 : 40|16@1+ (1,0) [0|65535] ""  dbg
 SG_ BMS_BMBHostErrorCount7 m4 : 40|16@1+ (1,0) [0|65535] ""  dbg
 SG_ BMS_BMBDeviceErrorCount2 m5 : 40|16@1+ (1,0) [0|65535] ""  dbg
 SG_ BMS_BMBHostErrorCount1 m2 : 40|16@1+ (1,0) [0|65535] ""  dbg
 SG_ BMS_dieTemperature2 m0 : 32|16@1- (0.01,0) [-327.68|327.67] "C"  dbg
 SG_ BMS_dieTemperature5 m1 : 32|16@1- (0.01,0) [-327.68|327.67] "C"  dbg
 SG_ BMS_BMBDeviceErrorCount7 m7 : 24|16@1+ (1,0) [0|65535] ""  dbg
 SG_ BMS_dieTemperature8 m2 : 24|16@1- (0.01,0) [-327.68|327.67] "C"  dbg
 SG_ BMS_BMBDeviceErrorCount1 m5 : 24|16@1+ (1,0) [0|65535] ""  dbg
 SG_ BMS_BMBDeviceErrorCount4 m6 : 24|16@1+ (1,0) [0|65535] ""  dbg
 SG_ BMS_BMBHostErrorCount3 m3 : 24|16@1+ (1,0) [0|65535] ""  dbg
 SG_ BMS_BMBHostErrorCount6 m4 : 24|16@1+ (1,0) [0|65535] ""  dbg
 SG_ BMS_dieTemperature1 m0 : 16|16@1- (0.01,0) [-327.68|327.67] "C"  dbg
 SG_ BMS_dieTemperature4 m1 : 16|16@1- (0.01,0) [-327.68|327.67] "C"  dbg
 SG_ BMS_BMBDeviceErrorCount3 m6 : 8|16@1+ (1,0) [0|65535] ""  dbg
 SG_ BMS_BMBDeviceErrorCount6 m7 : 8|16@1+ (1,0) [0|65535] ""  dbg
 SG_ BMS_BMBHostErrorCount5 m4 : 8|16@1+ (1,0) [0|65535] ""  dbg
 SG_ BMS_dieTemperatureStatus3 m0 : 8|2@1+ (1,0) [0|3] ""  dbg
 SG_ BMS_BMBHostErrorCount8 m5 : 8|16@1+ (1,0) [0|65535] ""  dbg
 SG_ BMS_BMBHostErrorCount2 m3 : 8|16@1+ (1,0) [0|65535] ""  dbg
 SG_ BMS_dieTemperature7 m2 : 8|16@1- (0.01,0) [-327.68|327.67] "C"  dbg
 SG_ BMS_dieTemperatureStatus6 m1 : 8|2@1+ (1,0) [0|3] ""  dbg
 SG_ BMS_dieTemperatureStatus2 m0 : 6|2@1+ (1,0) [0|3] ""  dbg
 SG_ BMS_dieTemperatureStatus8 m2 : 6|2@1+ (1,0) [0|3] ""  dbg
 SG_ BMS_dieTemperatureStatus5 m1 : 6|2@1+ (1,0) [0|3] ""  dbg
 SG_ BMS_dieTemperatureStatus4 m1 : 4|2@1+ (1,0) [0|3] ""  dbg
 SG_ BMS_dieTemperatureStatus1 m0 : 4|2@1+ (1,0) [0|3] ""  dbg
 SG_ BMS_dieTemperatureStatus7 m2 : 4|2@1+ (1,0) [0|3] ""  dbg
 SG_ BMS_10HzBmbDebug_Id M : 0|4@1+ (1,0) [0|8] ""  dbg

BO_ 1074 BMS_hvsNm: 2 VEH
 SG_ BMS_nmHeartbeatCounter : 1|4@1+ (1,0) [0|15] ""  X
 SG_ BMS_hvsGoToSleep : 0|1@1+ (1,0) [0|1] ""  gtw

BO_ 842 VCSEC_NFCDebug: 8 VEH
 SG_ VCSEC_CenterNFCStateReason m3 : 60|4@1+ (1,0) [0|10] ""  gtw
 SG_ VCSEC_BPillarNFCStateReason m0 : 60|3@1+ (1,0) [0|6] ""  gtw
 SG_ VCSEC_BPillarNFCReaderIdentity m0 : 52|8@1+ (1,0) [0|255] ""  gtw
 SG_ VCSEC_CenterNFCReaderIdentity m3 : 52|8@1+ (1,0) [0|255] ""  gtw
 SG_ VCSEC_CenterNFCDevLayerState m3 : 44|8@1+ (1,0) [0|255] ""  gtw
 SG_ VCSEC_BPillarNFCDevLayerState m0 : 44|8@1+ (1,0) [0|255] ""  gtw
 SG_ VCSEC_CenterNFCAmplitude m3 : 36|8@1+ (1,0) [0|255] ""  gtw
 SG_ VCSEC_BPillarNFCAmplitude m0 : 36|8@1+ (1,0) [0|255] ""  gtw
 SG_ VCSEC_BPillarNFCReaderState m0 : 28|2@1+ (1,0) [0|3] ""  gtw
 SG_ VCSEC_CenterNFCReaderState m3 : 28|2@1+ (1,0) [0|3] ""  gtw
 SG_ VCSEC_CenterNFCCardATQa m3 : 12|16@1+ (1,0) [0|65535] ""  X
 SG_ VCSEC_BPillarNFCWakeUpCounter m0 : 12|16@1+ (1,0) [0|65535] ""  gtw
 SG_ VCSEC_CenterNFCCardUIDSize m3 : 4|8@1+ (1,0) [0|255] ""  X
 SG_ VCSEC_BPillarNFCCardUIDSize m0 : 4|8@1+ (1,0) [0|255] ""  X
 SG_ VCSEC_BPillarNFCCardCollision m0 : 3|1@1+ (1,0) [0|1] ""  gtw
 SG_ VCSEC_CenterNFCCardCollision m3 : 3|1@1+ (1,0) [0|1] ""  gtw
 SG_ VCSEC_NFCReaderIndexDebug M : 0|2@1+ (1,0) [0|3] ""  X

BO_ 930 VCLEFT_status: 8 VEH
 SG_ VCLEFT_swcPCBATemperature m0 : 55|8@1- (1,-40) [-40|150] "degC"  gtw
 SG_ VCLEFT_swcInputVoltage m0 : 47|8@1+ (0.1,0) [0|25.4] "V"  gtw
 SG_ VCLEFT_footwellLightCurrent m0 : 35|12@1- (0.1,0) [-204.8|204.7] "mA"  X
 SG_ VCLEFT_tlcPCBATemperature m1 : 32|8@1- (1,-40) [-40|150] "degC"  gtw
 SG_ VCLEFT_DIeFuseFault m1 : 24|1@1+ (1,0) [0|1] ""  gtw
 SG_ VCLEFT_vbatProt m0 : 23|12@1+ (0.005443676098,0) [0|22.29185] "V"  gtw
 SG_ VCLEFT_5AVoltage m0 : 13|10@1+ (0.005443676098,0) [0|5.56888] "V"  gtw
 SG_ VCLEFT_DIeFuseCurrent m1 : 12|12@1- (0.1,0) [-204.8|204.7] "A"  X
 SG_ VCLEFT_OTAState m0 : 12|1@1+ (1,0) [0|1] ""  gtw
 SG_ VCLEFT_consoleDoorAssist m0 : 11|1@1+ (1,0) [0|1] ""  X
 SG_ VCLEFT_vehiclePowerStateDBG m0 : 9|2@1+ (1,0) [0|3] ""  gtw
 SG_ VCLEFT_loadShedPriority m0 : 1|8@1+ (1,0) [0|255] ""  X
 SG_ VCLEFT_pcbaTemperature m1 : 1|11@1+ (0.125,-40) [-40|150] "degC"  gtw
 SG_ VCLEFT_statusIndex M : 0|1@1+ (1,0) [0|1] ""  X

BO_ 1862 DBG_dynoControl: 8 VEH
 SG_ DBG_dynoTorqueCmd : 48|16@1+ (0.035,-1025.01) [-1025|1250] "Nm"  di
 SG_ DBG_dynoTorquePMT m1 : 47|1@1+ (1,0) [0|1] ""  di
 SG_ DBG_dynoSpeedCmd m2 : 32|16@1- (2.000030518509476,0.0) [-32768|32767] "RPM"  di
 SG_ DBG_dynoManualFluxRef m3 : 32|16@1+ (2e-05,0) [0|1] "Wb"  di
 SG_ DBG_dynoTorqueCmdLimit m2 : 16|16@1+ (0.035,0) [0|1250] "Nm"  di
 SG_ DBG_dynoCtrlSelector M : 8|2@1+ (1,0) [0|3] ""  di
 SG_ DBG_dynoSoptBypass : 7|1@1+ (1,0) [0|1] ""  di
 SG_ DBG_dynoIBatLimit : 6|1@1+ (1,0) [0|1] ""  di
 SG_ DBG_dynoTorqueCtrlFlag m1 : 5|1@1+ (1,0) [0|1] ""  di
 SG_ DBG_dynoSpeedCtrlFlag m2 : 5|1@1+ (1,0) [0|1] ""  di
 SG_ DBG_dynoManFluxRefFlag m3 : 5|1@1+ (1,0) [0|1] ""  di
 SG_ DBG_dynoTorqueCmdLimitFlag m2 : 4|1@1+ (1,0) [0|1] ""  di
 SG_ DBG_dynoStateRequest : 0|3@1+ (1,0) [0|4] ""  di

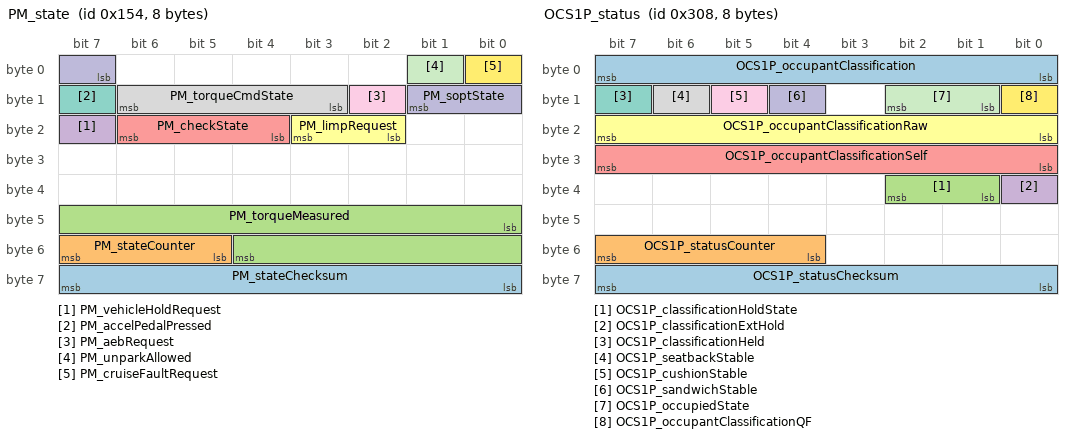
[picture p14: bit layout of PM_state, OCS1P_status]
BO_ 340 PM_state: 8 VEH
 SG_ PM_stateChecksum : 56|8@1+ (1,0) [0|255] ""  dbg
 SG_ PM_stateCounter : 53|3@1+ (1,0) [0|7] ""  dbg
 SG_ PM_torqueMeasured : 40|13@1- (0.25,0) [-1024|1023.75] "Nm"  di
 SG_ PM_vehicleHoldRequest : 23|1@1+ (1,0) [0|1] ""  di
 SG_ PM_checkState : 20|3@1+ (1,0) [0|4] ""  dbg
 SG_ PM_limpRequest : 18|2@1+ (1,0) [0|2] ""  di
 SG_ PM_accelPedalPressed : 15|1@1+ (1,0) [0|1] ""  gtw
 SG_ PM_torqueCmdState : 11|4@1+ (1,0) [0|8] ""  dis
 SG_ PM_aebRequest : 10|1@1+ (1,0) [0|1] ""  di
 SG_ PM_soptState : 7|3@1+ (1,0) [0|7] ""  di
 SG_ PM_unparkAllowed : 1|1@1+ (1,0) [0|1] ""  epbl
 SG_ PM_cruiseFaultRequest : 0|1@1+ (1,0) [0|1] ""  di

BO_ 776 OCS1P_status: 8 VEH
 SG_ OCS1P_statusChecksum : 56|8@1+ (1,0) [0|255] ""  X
 SG_ OCS1P_statusCounter : 52|4@1+ (1,0) [0|15] ""  X
 SG_ OCS1P_classificationHoldState : 33|2@1+ (1,0) [0|3] ""  X
 SG_ OCS1P_classificationExtHold : 32|1@1+ (1,0) [0|1] ""  X
 SG_ OCS1P_occupantClassificationSelf : 24|8@1+ (1,0) [0|255] ""  X
 SG_ OCS1P_occupantClassificationRaw : 16|8@1+ (1,0) [0|255] ""  X
 SG_ OCS1P_classificationHeld : 15|1@1+ (1,0) [0|1] ""  X
 SG_ OCS1P_seatbackStable : 14|1@1+ (1,0) [0|1] ""  X
 SG_ OCS1P_cushionStable : 13|1@1+ (1,0) [0|1] ""  X
 SG_ OCS1P_sandwichStable : 12|1@1+ (1,0) [0|1] ""  X
 SG_ OCS1P_occupiedState : 9|2@1+ (1,0) [0|3] ""  vcfront
 SG_ OCS1P_occupantClassificationQF : 8|1@1+ (1,0) [0|1] ""  X
 SG_ OCS1P_occupantClassification : 0|8@1+ (1,0) [0|255] ""  vcfront

BO_ 535 FC_status3: 8 VEH
 SG_ FC_uiStopType m0 : 24|4@1+ (1,0) [0|2] ""  gtw
 SG_ FC_coolingType m0 : 20|4@1+ (1,0) [0|2] ""  gtw
 SG_ FC_brand m0 : 16|4@1+ (1,0) [0|1] ""  gtw
 SG_ FC_class m0 : 8|8@1+ (1,0) [0|2] ""  gtw
 SG_ FC_status3DummySig : 7|1@1+ (1,0) [0|1] ""  X
 SG_ FC_status3DataSelect M : 0|7@1+ (1,0) [0|0] ""  X

BO_ 513 VCFRONT_loggingAndVitals10Hz: 8 VEH
 SG_ VCFRONT_fiveWayValveMode m1 : 59|1@1+ (1,0) [0|1] ""  gtw
 SG_ VCFRONT_exvFlowTarget m0 : 53|10@1+ (0.1,0) [0|100] "%"  gtw
 SG_ VCFRONT_pressureRefrigDischargeV m1 : 51|8@1+ (0.125,0) [0|31.75] "bar"  gtw
 SG_ VCFRONT_tempSuperheatTarget m0 : 43|10@1+ (0.1,0) [0|60] "degC"  gtw
 SG_ VCFRONT_pressureRefrigSuctionVit m1 : 43|7@1+ (0.125,0) [0|11.5] "bar"  gtw
 SG_ VCFRONT_compDemandChiller m1 : 35|7@1+ (1,0) [0|100] "%"  gtw
 SG_ VCFRONT_solenoidEvapState m1 : 33|2@1+ (1,0) [0|3] ""  gtw
 SG_ VCFRONT_tempSuperheatActual m0 : 33|10@1+ (0.1,-20) [-20|80] "degC"  gtw
 SG_ VCFRONT_exvState m1 : 30|3@1+ (1,0) [0|5] ""  dbg
 SG_ VCFRONT_compDemandEvap m1 : 23|7@1+ (1,0) [0|100] "%"  gtw
 SG_ VCFRONT_radiatorFanRPMActual m0 : 23|10@1+ (10,0) [0|10000] "rpm"  gtw
 SG_ VCFRONT_compressorState m1 : 21|2@1+ (1,0) [0|3] ""  gtw
 SG_ VCFRONT_fanDemand m1 : 14|7@1+ (1,0) [0|100] "%"  gtw
 SG_ VCFRONT_pumpPowertrainRPMActual m0 : 13|10@1+ (10,0) [0|10000] "rpm"  gtw
 SG_ VCFRONT_tempRefrigDischarge m1 : 3|11@1+ (0.125,-40) [-40|150] "degC"  gtw
 SG_ VCFRONT_pumpBatteryRPMActual m0 : 3|10@1+ (10,0) [0|10000] "rpm"  gtw
 SG_ VCFRONT_loggingAndVitals10HzInde M : 0|2@1+ (1,0) [0|2] ""  X

BO_ 1573 EPBL_udsResponse: 8 VEH
 SG_ EPBL_udsResponseData_L : 39|32@0+ (1,0) [0|4294967295] ""  gtw
 SG_ EPBL_udsResponseData_H : 7|32@0+ (1,0) [0|4294967295] ""  gtw

BO_ 1877 XCP_vcsecRequest: 8 VEH
 SG_ XCP_vcsecRequestData : 7|64@0+ (1,0) [0|18446744073709551615] ""  vcsec

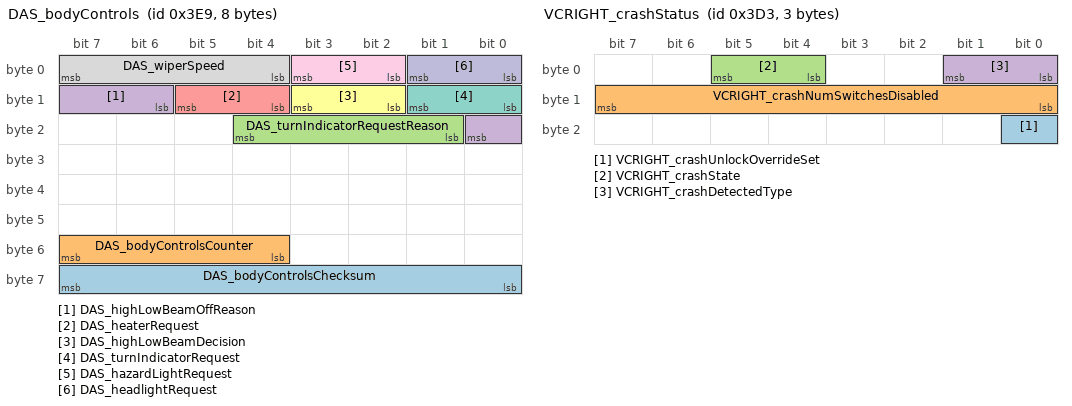
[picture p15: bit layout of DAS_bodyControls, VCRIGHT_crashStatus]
BO_ 1001 DAS_bodyControls: 8 VEH
 SG_ DAS_bodyControlsChecksum : 56|8@1+ (1,0) [0|255] ""  aps
 SG_ DAS_bodyControlsCounter : 52|4@1+ (1,0) [0|15] ""  aps
 SG_ DAS_turnIndicatorRequestReason : 17|4@1+ (1,0) [0|8] ""  aps
 SG_ DAS_highLowBeamOffReason : 14|3@1+ (1,0) [0|5] ""  aps
 SG_ DAS_heaterRequest : 12|2@1+ (1,0) [0|2] ""  aps
 SG_ DAS_highLowBeamDecision : 10|2@1+ (1,0) [0|3] ""  aps
 SG_ DAS_turnIndicatorRequest : 8|2@1+ (1,0) [0|3] ""  aps
 SG_ DAS_wiperSpeed : 4|4@1+ (1,0) [0|15] ""  aps
 SG_ DAS_hazardLightRequest : 2|2@1+ (1,0) [0|3] ""  aps
 SG_ DAS_headlightRequest : 0|2@1+ (1,0) [0|3] ""  aps

BO_ 979 VCRIGHT_crashStatus: 3 VEH
 SG_ VCRIGHT_crashUnlockOverrideSet : 16|1@1+ (1,0) [0|1] ""  gtw
 SG_ VCRIGHT_crashNumSwitchesDisabled : 8|8@1+ (1,0) [0|255] ""  gtw
 SG_ VCRIGHT_crashState : 4|2@1+ (1,0) [0|2] ""  gtw
 SG_ VCRIGHT_crashDetectedType : 0|2@1+ (1,0) [0|2] ""  gtw

BA_DEF_ SG_  "SystemSignalLongSymbol" STRING ;
BA_DEF_DEF_  "SystemSignalLongSymbol" "";
BA_ "SystemSignalLongSymbol" SG_ 738 VCLEFT_rearCenterOccupancyVoltag "VCLEFT_rearCenterOccupancyVoltage";
BA_ "SystemSignalLongSymbol" SG_ 1359 SCCM_a028_parkButtonShortToGroun "SCCM_a028_parkButtonShortToGround";
BA_ "SystemSignalLongSymbol" SG_ 1359 SCCM_a026_parkButtonInvalidSigna "SCCM_a026_parkButtonInvalidSignal";
BA_ "SystemSignalLongSymbol" SG_ 864 VCLEFT_a294_occupancyFaultedRear "VCLEFT_a294_occupancyFaultedRearR";
BA_ "SystemSignalLongSymbol" SG_ 864 VCLEFT_a293_occupancyFaultedRear "VCLEFT_a293_occupancyFaultedRearC";
BA_ "SystemSignalLongSymbol" SG_ 864 VCLEFT_a292_occupancyFaultedRear "VCLEFT_a292_occupancyFaultedRearL";
BA_ "SystemSignalLongSymbol" SG_ 864 VCLEFT_a290_occupancyFaultedFron "VCLEFT_a290_occupancyFaultedFront";
BA_ "SystemSignalLongSymbol" SG_ 864 VCLEFT_a304_frontIntHandleShorte "VCLEFT_a304_frontIntHandleShorted";
BA_ "SystemSignalLongSymbol" SG_ 960 VCRIGHT_a180_frontDoorLatchRehom "VCRIGHT_a180_frontDoorLatchRehome";
BA_ "SystemSignalLongSymbol" SG_ 960 VCRIGHT_a290_occupancyFaultedFro "VCRIGHT_a290_occupancyFaultedFront";
BA_ "SystemSignalLongSymbol" SG_ 960 VCRIGHT_a278_hvacPtcHeatingUnava "VCRIGHT_a278_hvacPtcHeatingUnavailable";
BA_ "SystemSignalLongSymbol" SG_ 960 VCRIGHT_a277_BLERightUnderVoltag "VCRIGHT_a277_BLERightUnderVoltage";
BA_ "SystemSignalLongSymbol" SG_ 960 VCRIGHT_a215_currentDesyncWarnin "VCRIGHT_a215_currentDesyncWarning";
BA_ "SystemSignalLongSymbol" SG_ 960 VCRIGHT_a267_seatTrackHCEncStlDb "VCRIGHT_a267_seatTrackHCEncStlDbg";
BA_ "SystemSignalLongSymbol" SG_ 960 VCRIGHT_a143_mirrorManuallyFolde "VCRIGHT_a143_mirrorManuallyFolded";
BA_ "SystemSignalLongSymbol" SG_ 960 VCRIGHT_a305_rearIntHandleShorte "VCRIGHT_a305_rearIntHandleShorted";
BA_ "SystemSignalLongSymbol" SG_ 960 VCRIGHT_a304_frontIntHandleShort "VCRIGHT_a304_frontIntHandleShorted";
BA_ "SystemSignalLongSymbol" SG_ 960 VCRIGHT_a183_doorStateFactoryTes "VCRIGHT_a183_doorStateFactoryTest";
BA_ "SystemSignalLongSymbol" SG_ 691 VCRIGHT_hvacCabOvrheatProtAllowe "VCRIGHT_hvacCabOvrheatProtAllowed";
BA_ "SystemSignalLongSymbol" SG_ 691 VCRIGHT_ptcHeaterReqAirpathBlock "VCRIGHT_ptcHeaterReqAirpathBlocked";
BA_ "SystemSignalLongSymbol" SG_ 932 PCS_a090_expectedAcVoltageSource "PCS_a090_expectedAcVoltageSourceMissing";
BA_ "SystemSignalLongSymbol" SG_ 932 PCS_a089_hvBusDischargeIrrationa "PCS_a089_hvBusDischargeIrrational";
BA_ "SystemSignalLongSymbol" SG_ 932 PCS_a073_unexpectedAcInputVoltag "PCS_a073_unexpectedAcInputVoltage";
BA_ "SystemSignalLongSymbol" SG_ 642 VCLEFT_hvacBlower_IO_CBC_numUart "VCLEFT_hvacBlower_IO_CBC_numUartErr";
BA_ "SystemSignalLongSymbol" SG_ 642 VCLEFT_hvacBlower_IO_CBC_TAIL_va "VCLEFT_hvacBlower_IO_CBC_TAIL_valid";
BA_ "SystemSignalLongSymbol" SG_ 513 VCFRONT_pressureRefrigDischargeV "VCFRONT_pressureRefrigDischargeVitals";
BA_ "SystemSignalLongSymbol" SG_ 513 VCFRONT_pressureRefrigSuctionVit "VCFRONT_pressureRefrigSuctionVitals";
BA_ "SystemSignalLongSymbol" SG_ 513 VCFRONT_loggingAndVitals10HzInde "VCFRONT_loggingAndVitals10HzIndex";
VAL_ 470 DI_wasteState 2 "DI_WASTE_ON" 1 "DI_WASTE_AVAILABLE" 0 "DI_WASTE_UNAVAILABLE" ;
VAL_ 659 UI_selfParkTune 15 "SNA" ;
VAL_ 659 UI_redLightStopSignEnable 3 "SNA" 1 "RLSSW_ON" 0 "RLSSW_OFF" ;
VAL_ 659 UI_pedalSafetyEnable 3 "SNA" 0 "PEDAL_SAFETY_OFF" 1 "PEDAL_SAFETY_ON" ;
VAL_ 659 UI_ldwEnable 3 "SNA" 1 "LDW_TRIGGERS_HAPTIC" 0 "NO_HAPTIC" ;
VAL_ 659 UI_latControlEnable 3 "LATERAL_CONTROL_SNA" 2 "LATERAL_CONTROL_UNAVAILABLE" 1 "LATERAL_CONTROL_ON" 0 "LATERAL_CONTROL_OFF" ;
VAL_ 659 UI_fcwSensitivity 3 "SNA" 2 "AEB_SENSITIVITY_LATE" 1 "AEB_SENSITIVITY_AVERAGE" 0 "AEB_SENSITIVITY_EARLY" ;
VAL_ 659 UI_fcwEnable 3 "SNA" 1 "FCW_ON" 0 "FCW_OFF" ;
VAL_ 659 UI_bsdEnable 3 "SNA" 0 "BSD_OFF" 1 "BSD_ON" ;
VAL_ 659 UI_autoLaneChangeEnable 3 "SNA" 0 "OFF" 1 "ON" ;
VAL_ 659 UI_autoParkRequest 15 "SNA" 7 "ABORT" 0 "NONE" 2 "PARK_LEFT_CROSS" 1 "PARK_LEFT_PARALLEL" 5 "PARALLEL_PULL_OUT_TO_LEFT" 6 "PARALLEL_PULL_OUT_TO_RIGHT" 10 "PAUSE" 3 "PARK_RIGHT_PARALLEL" 9 "SEARCH" 4 "PARK_RIGHT_CROSS" 8 "COMPLETE" 11 "RESUME" ;
VAL_ 659 UI_ahlbEnable 3 "SNA" 0 "AHLB_OFF" 1 "AHLB_ON" ;
VAL_ 659 UI_aesEnable 3 "SNA" 0 "AES_OFF" 1 "AES_ON" ;
VAL_ 659 UI_aebEnable 3 "SNA" 1 "AEB_ON" 0 "AEB_OFF" ;
VAL_ 659 UI_accOvertakeEnable 3 "SNA" 1 "ACC_OVERTAKE_ON" 0 "ACC_OVERTAKE_OFF" ;
VAL_ 659 UI_distanceUnits 0 "DISTANCEUNITS_KM" 1 "DISTANCEUNITS_MILES" ;
VAL_ 659 UI_suspensionLevelRequest 7 "REQUEST_VERY_LOW_LEVEL" 5 "TOGGLE_JACK_MODE" 4 "REQUEST_VERY_HIGH_LEVEL" 2 "REQUEST_NORMAL_LEVEL" 6 "SWITCH_DEFECT" 0 "NO_CHANGE_SNA" 1 "REQUEST_LOW_LEVEL" 3 "REQUEST_HIGH_LEVEL" ;
VAL_ 659 UI_trailerMode 1 "TRAILER_MODE_ON" 0 "TRAILER_MODE_OFF" ;
VAL_ 659 UI_zeroSpeedConfirmed 0 "ZERO_SPEED_CANCELED" 1 "ZERO_SPEED_CONFIRMED" 3 "ZERO_SPEED_SNA" 2 "ZERO_SPEED_UNUSED" ;
VAL_ 659 UI_winchModeRequest 0 "WINCH_MODE_IDLE" 2 "WINCH_MODE_EXIT" 1 "WINCH_MODE_ENTER" ;
VAL_ 659 UI_parkBrakeRequest 1 "PARK_BRAKE_REQUEST_PRESSED" 3 "PARK_BRAKE_REQUEST_SNA" 0 "PARK_BRAKE_REQUEST_IDLE" ;
VAL_ 659 UI_tractionControlMode 4 "TC_ROLLS_MODE_SELECTED" 1 "TC_SLIP_START_SELECTED" 0 "TC_NORMAL_SELECTED" 3 "TC_DEV_MODE_2_SELECTED" 2 "TC_DEV_MODE_1_SELECTED" 5 "TC_DYNO_MODE_SELECTED" ;
VAL_ 659 UI_steeringTuneRequest 1 "STEERING_TUNE_STANDARD" 2 "STEERING_TUNE_SPORT" 0 "STEERING_TUNE_COMFORT" ;
VAL_ 790 PM_hardwareId 252 "CONFIGURABLE_HWID_PLACEHOLDER" ;
VAL_ 790 PM_diNodeBuildType 1 "INFO_PLATFORM_BUILD" 3 "INFO_TRACEABLE_CI_BUILD" 4 "INFO_MFG_BUILD" 2 "INFO_LOCAL_BUILD" 0 "INFO_UNKNOWN_BUILD" ;
VAL_ 790 PM_buildType 1 "INFO_PLATFORM_BUILD" 3 "INFO_TRACEABLE_CI_BUILD" 4 "INFO_MFG_BUILD" 2 "INFO_LOCAL_BUILD" 0 "INFO_UNKNOWN_BUILD" ;
VAL_ 790 PM_infoIndex 1 "PM_INFO_DEPRECATED_1" 19 "PM_INFO_VERSION_DEPRECATED" 7 "PM_INFO_DEPRECATED_7" 10 "PM_INFO_BUILD_HWID_COMPONENTID" 0 "PM_INFO_DEPRECATED_0" 14 "PM_INFO_BOOTLOADER_SVN" 21 "PM_INFO_DI_BUILD_DATA" 6 "PM_INFO_DEPRECATED_6" 20 "PM_INFO_UDS_PROTOCOL_BOOTCRC" 3 "PM_INFO_DEPRECATED_3" 255 "PM_INFO_END" 9 "PM_INFO_DEPRECATED_9" 2 "PM_INFO_DEPRECATED_2" 13 "PM_INFO_APP_CRC" 8 "PM_INFO_DEPRECATED_8" 17 "PM_INFO_APP_GITHASH" 5 "PM_INFO_DEPRECATED_5" 16 "PM_INFO_SUBCOMPONENT" 18 "PM_INFO_BOOTLOADER_GITHASH" 11 "PM_INFO_PCBAID_ASSYID_USAGEID" 4 "PM_INFO_DEPRECATED_4" 15 "PM_INFO_BOOTLOADER_CRC" ;
VAL_ 1622 DI_hardwareId 252 "CONFIGURABLE_HWID_PLACEHOLDER" ;
VAL_ 1622 DI_oilPumpBuildType 1 "INFO_PLATFORM_BUILD" 3 "INFO_TRACEABLE_CI_BUILD" 4 "INFO_MFG_BUILD" 2 "INFO_LOCAL_BUILD" 0 "INFO_UNKNOWN_BUILD" ;
VAL_ 1622 DI_buildType 1 "INFO_PLATFORM_BUILD" 3 "INFO_TRACEABLE_CI_BUILD" 4 "INFO_MFG_BUILD" 2 "INFO_LOCAL_BUILD" 0 "INFO_UNKNOWN_BUILD" ;
VAL_ 1622 DI_infoIndex 25 "INFO_PACKAGE_PN_1_7" 30 "INFO_PACKAGE_SN_8_14" 27 "INFO_PACKAGE_PN_15_20" 0 "INFO_DEPRECATED_0" 29 "INFO_PACKAGE_SN_1_7" 10 "INFO_BUILD_HWID_COMPONENTID" 14 "INFO_BOOTLOADER_SVN" 31 "INFO_SUBCOMPONENT_GITHASH" 19 "INFO_VERSION_DEPRECATED" 7 "INFO_DEPRECATED_7" 255 "INFO_END" 9 "INFO_DEPRECATED_9" 6 "INFO_DEPRECATED_6" 20 "INFO_UDS_PROTOCOL_BOOTCRC" 3 "INFO_DEPRECATED_3" 22 "INFO_VARIANTCRC" 17 "INFO_APP_GITHASH" 8 "INFO_DEPRECATED_8" 26 "INFO_PACKAGE_PN_8_14" 5 "INFO_DEPRECATED_5" 16 "INFO_SUBCOMPONENT" 13 "INFO_APP_CRC" 2 "INFO_DEPRECATED_2" 4 "INFO_DEPRECATED_4" 15 "INFO_BOOTLOADER_CRC" 1 "INFO_DEPRECATED_1" 11 "INFO_PCBAID_ASSYID_USAGEID" 18 "INFO_BOOTLOADER_GITHASH" ;
VAL_ 738 VCLEFT_seatStatus2Index 0 "VCLEFT_SEAT_HEAT_FRONT" 1 "VCLEFT_SEAT_HEAT_REARL_BACKREST" 2 "VCLEFT_OCCUPANCY" 3 "VCLEFT_SEAT_STATUS_2_INDEX_COUNT" ;
VAL_ 1800 EPBL_CPULoad1000msTask 255 "SNA" ;
VAL_ 1800 EPBL_CPULoad100msTask 255 "SNA" ;
VAL_ 1800 EPBL_CPULoad10msTask 255 "SNA" ;
VAL_ 1800 EPBL_CPULoad1msTask 255 "SNA" ;
VAL_ 1800 EPBL_CPULoadTotal 255 "SNA" ;
VAL_ 922 VCSEC_RSSIChannelIndex 0 "Mux0" 1 "Mux1" ;
VAL_ 1366 DI_torqueWearTotal 255 "SNA" ;
VAL_ 1366 DI_IGBTJunctTemp 255 "SNA" ;
VAL_ 2024 EPBR_infoAssemblyId 1 "ASSEMBLY1" 255 "ASSEMBLY_SNA" ;
VAL_ 2024 EPBR_infoBuildType 1 "INFO_PLATFORM_BUILD" 3 "INFO_TRACEABLE_CI_BUILD" 4 "INFO_MFG_BUILD" 2 "INFO_LOCAL_BUILD" 0 "INFO_UNKNOWN_BUILD" ;
VAL_ 2024 EPBR_infoIndex 14 "BC_INFO_BOOTLOADER_SVN" 6 "BC_INFO_DEPRECATED_6" 20 "BC_INFO_UDS_PROTOCOL_BOOTCRC" 24 "BC_INFO_SUBCOMPONENT3" 1 "BC_INFO_DEPRECATED_1" 31 "BC_INFO_SUBCOMPONENT4" 19 "BC_INFO_VERSION_DEPRECATED" 10 "BC_INFO_BUILD_HWID_COMPONENTID" 0 "BC_INFO_DEPRECATED_0" 5 "BC_INFO_DEPRECATED_5" 11 "BC_INFO_PCBAID_ASSYID_USAGEID" 18 "BC_INFO_BOOTLOADER_GITHASH" 3 "BC_INFO_DEPRECATED_3" 15 "BC_INFO_BOOTLOADER_CRC" 4 "BC_INFO_DEPRECATED_4" 16 "BC_INFO_SUBCOMPONENT1" 255 "BC_INFO_END" 9 "BC_INFO_DEPRECATED_9" 13 "BC_INFO_APP_CRC" 2 "BC_INFO_DEPRECATED_2" 23 "BC_INFO_SUBCOMPONENT2" 7 "BC_INFO_DEPRECATED_7" 8 "BC_INFO_DEPRECATED_8" 17 "BC_INFO_APP_GITHASH" ;
VAL_ 533 FC_externalIsolationResistance 255 "SNA" ;
VAL_ 1359 SCCM_matrixIndex 0 "SCCM_AlertMatrix0" ;
VAL_ 904 EPBL_csmState 8 "CSM_WAIT_FOR_ENDSTOP" 9 "CSM_RELEASE_COMPLETE" 12 "CSM_FAULT" 5 "CSM_APPLY_COMPLETE" 7 "CSM_RELEASE_NOLOAD" 14 "CSM_HOLD_CLAMP" 4 "CSM_WAIT_FOR_CLAMP" 6 "CSM_RELEASE_INRUSH" 13 "CSM_STATIONARY_FAULT" 2 "CSM_APPLY_INRUSH" 10 "CSM_CALIBRATE" 1 "CSM_STANDBY" 0 "CSM_INIT" 11 "CSM_HALT" 3 "CSM_APPLY_NOLOAD" ;
VAL_ 904 EPBL_esmStateRequest 11 "ESM_PARK_PENDING" 1 "ESM_PARK" 3 "ESM_OPEN" 5 "ESM_SUMMON" 0 "ESM_INIT" 6 "ESM_WINCHMODE" 13 "ESM_SUMMON_PARK" 18 "ESM_DYNAMIC_EXTERNAL_EXIT" 19 "ESM_UNKNOWN" 12 "ESM_WINCHMODE_PENDING" 8 "ESM_DIAGNOSTIC_PARK" 16 "ESM_LATCHED_DYNAMIC_EXTERNAL" 2 "ESM_REAPPLY" 9 "ESM_DIAGNOSTIC_OPEN" 14 "ESM_DYNAMIC_EXTERNAL" 10 "ESM_DYNAMIC_PARK" 17 "ESM_SERVICE_PENDING" 15 "ESM_DYNAMIC_PENDING" 7 "ESM_SERVICE" 4 "ESM_DYNAMIC" ;
VAL_ 904 EPBL_esmState 11 "ESM_PARK_PENDING" 1 "ESM_PARK" 3 "ESM_OPEN" 5 "ESM_SUMMON" 0 "ESM_INIT" 6 "ESM_WINCHMODE" 13 "ESM_SUMMON_PARK" 18 "ESM_DYNAMIC_EXTERNAL_EXIT" 19 "ESM_UNKNOWN" 12 "ESM_WINCHMODE_PENDING" 8 "ESM_DIAGNOSTIC_PARK" 16 "ESM_LATCHED_DYNAMIC_EXTERNAL" 2 "ESM_REAPPLY" 9 "ESM_DIAGNOSTIC_OPEN" 14 "ESM_DYNAMIC_EXTERNAL" 10 "ESM_DYNAMIC_PARK" 17 "ESM_SERVICE_PENDING" 15 "ESM_DYNAMIC_PENDING" 7 "ESM_SERVICE" 4 "ESM_DYNAMIC" ;
VAL_ 708 PCS_chgPhCInputFreqWobble 0 "FREQUENCY_UNKNOWN" ;
VAL_ 708 PCS_chgInternalPhaseConfig 3 "PHASE_CONFIG_THREE_PHASE_DELTA" 1 "PHASE_CONFIG_SINGLE_PHASE" 4 "PHASE_CONFIG_SINGLE_PHASE_IEC_GB" 5 "PHASE_CONFIG_MFG_TEST_CONFIG_1" 2 "PHASE_CONFIG_THREE_PHASE" 0 "PHASE_CONFIG_SNA" 7 "PHASE_CONFIG_RELIABILITY_SINGLE_PHASE" 6 "PHASE_CONFIG_MFG_TEST_CONFIG_2" 8 "PHASE_CONFIG_TOTAL_NUM" ;
VAL_ 708 PCS_chgPhBInputFreqWobble 0 "FREQUENCY_UNKNOWN" ;
VAL_ 708 PCS_chgInputFrequencyL3N 0 "FREQUENCY_UNKNOWN" ;
VAL_ 708 PCS_chgPhAInputFreqWobble 0 "FREQUENCY_UNKNOWN" ;
VAL_ 708 PCS_chgPhCLastShutdownReason 8 "PCS_PH_SHUTDOWN_OUTPUT_UV" 7 "PCS_PH_SHUTDOWN_INPUT_OV" 15 "PCS_PH_SHUTDOWN_SENSOR_IRRATIONAL" 13 "PCS_PH_SHUTDOWN_OVER_TEMPERATURE" 1 "PCS_PH_SHUTDOWN_SW_ENABLE" 4 "PCS_PH_SHUTDOWN_HW_FAULT" 6 "PCS_PH_SHUTDOWN_INPUT_UV" 11 "PCS_PH_SHUTDOWN_INT_BUS_UV" 0 "PCS_PH_SHUTDOWN_REASON_NONE" 10 "PCS_PH_SHUTDOWN_PRECHARGE_TIMEOUT" 3 "PCS_PH_SHUTDOWN_SW_FAULT" 17 "PCS_PH_SHUTDOWN_LINE_TRANSIENT_FAULT" 14 "PCS_PH_SHUTDOWN_TEMP_IRRATIONAL" 16 "PCS_PH_SHUTDOWN_FREQ_OUT_OF_RANGE" 5 "PCS_PH_SHUTDOWN_PLL_NOT_LOCKED" 12 "PCS_PH_SHUTDOWN_CONTROL_REGULATION_FAULT" 2 "PCS_PH_SHUTDOWN_HW_ENABLE" 9 "PCS_PH_SHUTDOWN_OUTPUT_OV" ;
VAL_ 708 PCS_dcdcTankVoltage -1024 "TANK_VOLTAGE_SNA" ;
VAL_ 708 PCS_chgPhBLastShutdownReason 8 "PCS_PH_SHUTDOWN_OUTPUT_UV" 7 "PCS_PH_SHUTDOWN_INPUT_OV" 15 "PCS_PH_SHUTDOWN_SENSOR_IRRATIONAL" 13 "PCS_PH_SHUTDOWN_OVER_TEMPERATURE" 1 "PCS_PH_SHUTDOWN_SW_ENABLE" 4 "PCS_PH_SHUTDOWN_HW_FAULT" 6 "PCS_PH_SHUTDOWN_INPUT_UV" 11 "PCS_PH_SHUTDOWN_INT_BUS_UV" 0 "PCS_PH_SHUTDOWN_REASON_NONE" 10 "PCS_PH_SHUTDOWN_PRECHARGE_TIMEOUT" 3 "PCS_PH_SHUTDOWN_SW_FAULT" 17 "PCS_PH_SHUTDOWN_LINE_TRANSIENT_FAULT" 14 "PCS_PH_SHUTDOWN_TEMP_IRRATIONAL" 16 "PCS_PH_SHUTDOWN_FREQ_OUT_OF_RANGE" 5 "PCS_PH_SHUTDOWN_PLL_NOT_LOCKED" 12 "PCS_PH_SHUTDOWN_CONTROL_REGULATION_FAULT" 2 "PCS_PH_SHUTDOWN_HW_ENABLE" 9 "PCS_PH_SHUTDOWN_OUTPUT_OV" ;
VAL_ 708 PCS_chgInputFrequencyL2N 0 "FREQUENCY_UNKNOWN" ;
VAL_ 708 PCS_chgPhALastShutdownReason 8 "PCS_PH_SHUTDOWN_OUTPUT_UV" 7 "PCS_PH_SHUTDOWN_INPUT_OV" 15 "PCS_PH_SHUTDOWN_SENSOR_IRRATIONAL" 13 "PCS_PH_SHUTDOWN_OVER_TEMPERATURE" 1 "PCS_PH_SHUTDOWN_SW_ENABLE" 4 "PCS_PH_SHUTDOWN_HW_FAULT" 6 "PCS_PH_SHUTDOWN_INPUT_UV" 11 "PCS_PH_SHUTDOWN_INT_BUS_UV" 0 "PCS_PH_SHUTDOWN_REASON_NONE" 10 "PCS_PH_SHUTDOWN_PRECHARGE_TIMEOUT" 3 "PCS_PH_SHUTDOWN_SW_FAULT" 17 "PCS_PH_SHUTDOWN_LINE_TRANSIENT_FAULT" 14 "PCS_PH_SHUTDOWN_TEMP_IRRATIONAL" 16 "PCS_PH_SHUTDOWN_FREQ_OUT_OF_RANGE" 5 "PCS_PH_SHUTDOWN_PLL_NOT_LOCKED" 12 "PCS_PH_SHUTDOWN_CONTROL_REGULATION_FAULT" 2 "PCS_PH_SHUTDOWN_HW_ENABLE" 9 "PCS_PH_SHUTDOWN_OUTPUT_OV" ;
VAL_ 708 PCS_chgPhCState 4 "PCS_PH_STATE_FAULT" 2 "PCS_PH_STATE_PRECHARGE" 1 "PCS_PH_STATE_IDLE" 5 "PCS_PH_STATE_CLEAR_FAULTS" 0 "PCS_PH_STATE_INIT" 6 "PCS_PH_STATE_SHUTTING_DOWN" 3 "PCS_PH_STATE_ENABLE" ;
VAL_ 708 PCS_dLogPhCChannel4Content 1 "PCS_DLOG_INPUT_CURRENT" 2 "PCS_DLOG_OUTPUT_CURRENT" 3 "PCS_DLOG_INT_BUS_VOLTAGE" 0 "PCS_DLOG_INPUT_VOLTAGE" ;
VAL_ 708 PCS_dLogPhCChannel1Content 1 "PCS_DLOG_INPUT_CURRENT" 2 "PCS_DLOG_OUTPUT_CURRENT" 3 "PCS_DLOG_INT_BUS_VOLTAGE" 0 "PCS_DLOG_INPUT_VOLTAGE" ;
VAL_ 708 PCS_dLogPhCChannel2Content 1 "PCS_DLOG_INPUT_CURRENT" 2 "PCS_DLOG_OUTPUT_CURRENT" 3 "PCS_DLOG_INT_BUS_VOLTAGE" 0 "PCS_DLOG_INPUT_VOLTAGE" ;
VAL_ 708 PCS_dLogPhCChannel3Content 1 "PCS_DLOG_INPUT_CURRENT" 2 "PCS_DLOG_OUTPUT_CURRENT" 3 "PCS_DLOG_INT_BUS_VOLTAGE" 0 "PCS_DLOG_INPUT_VOLTAGE" ;
VAL_ 708 PCS_chgPhBState 4 "PCS_PH_STATE_FAULT" 2 "PCS_PH_STATE_PRECHARGE" 1 "PCS_PH_STATE_IDLE" 5 "PCS_PH_STATE_CLEAR_FAULTS" 0 "PCS_PH_STATE_INIT" 6 "PCS_PH_STATE_SHUTTING_DOWN" 3 "PCS_PH_STATE_ENABLE" ;
VAL_ 708 PCS_dLogPhBChannel1Content 1 "PCS_DLOG_INPUT_CURRENT" 2 "PCS_DLOG_OUTPUT_CURRENT" 3 "PCS_DLOG_INT_BUS_VOLTAGE" 0 "PCS_DLOG_INPUT_VOLTAGE" ;
VAL_ 708 PCS_chgInputFrequencyL1N 0 "FREQUENCY_UNKNOWN" ;
VAL_ 708 PCS_dLogPhBChannel3Content 1 "PCS_DLOG_INPUT_CURRENT" 2 "PCS_DLOG_OUTPUT_CURRENT" 3 "PCS_DLOG_INT_BUS_VOLTAGE" 0 "PCS_DLOG_INPUT_VOLTAGE" ;
VAL_ 708 PCS_dLogPhBChannel4Content 1 "PCS_DLOG_INPUT_CURRENT" 2 "PCS_DLOG_OUTPUT_CURRENT" 3 "PCS_DLOG_INT_BUS_VOLTAGE" 0 "PCS_DLOG_INPUT_VOLTAGE" ;
VAL_ 708 PCS_dLogPhBChannel2Content 1 "PCS_DLOG_INPUT_CURRENT" 2 "PCS_DLOG_OUTPUT_CURRENT" 3 "PCS_DLOG_INT_BUS_VOLTAGE" 0 "PCS_DLOG_INPUT_VOLTAGE" ;
VAL_ 708 PCS_acChargeSelfTestState 1 "PCS_SELF_TEST_STARTED" 0 "PCS_SELF_TEST_IDLE" ;
VAL_ 708 PCS_dLogPhAChannel2Content 1 "PCS_DLOG_INPUT_CURRENT" 2 "PCS_DLOG_OUTPUT_CURRENT" 3 "PCS_DLOG_INT_BUS_VOLTAGE" 0 "PCS_DLOG_INPUT_VOLTAGE" ;
VAL_ 708 PCS_chgPhAState 4 "PCS_PH_STATE_FAULT" 2 "PCS_PH_STATE_PRECHARGE" 1 "PCS_PH_STATE_IDLE" 5 "PCS_PH_STATE_CLEAR_FAULTS" 0 "PCS_PH_STATE_INIT" 6 "PCS_PH_STATE_SHUTTING_DOWN" 3 "PCS_PH_STATE_ENABLE" ;
VAL_ 708 PCS_cpu2BootState 1 "CPU2_STATE_BOOTLOADER" 0 "CPU2_STATE_BOOTROM" 3 "CPU2_STATE_ERROR" 2 "CPU2_STATE_APPLICATION" ;
VAL_ 708 PCS_dLogPhAChannel3Content 1 "PCS_DLOG_INPUT_CURRENT" 2 "PCS_DLOG_OUTPUT_CURRENT" 3 "PCS_DLOG_INT_BUS_VOLTAGE" 0 "PCS_DLOG_INPUT_VOLTAGE" ;
VAL_ 708 PCS_dLogPhAChannel4Content 1 "PCS_DLOG_INPUT_CURRENT" 2 "PCS_DLOG_OUTPUT_CURRENT" 3 "PCS_DLOG_INT_BUS_VOLTAGE" 0 "PCS_DLOG_INPUT_VOLTAGE" ;
VAL_ 708 PCS_dLogPhAChannel1Content 1 "PCS_DLOG_INPUT_CURRENT" 2 "PCS_DLOG_OUTPUT_CURRENT" 3 "PCS_DLOG_INT_BUS_VOLTAGE" 0 "PCS_DLOG_INPUT_VOLTAGE" ;
VAL_ 708 PCS_logMessageSelect 5 "PCS_LOG_CHG_3" 18 "PCS_LOG_DCDC_4" 12 "PCS_LOG_PHC_2" 14 "PCS_LOG_DLOG_1" 4 "PCS_LOG_CHG_2" 8 "PCS_LOG_DCDC_3" 11 "PCS_LOG_PHB_2" 13 "PCS_LOG_CHG_4" 0 "PCS_LOG_PHA_1" 3 "PCS_LOG_CHG_1" 22 "PCS_LOG_DCDC_STATISTICS" 7 "PCS_LOG_DCDC_2" 9 "PCS_LOG_SYSTEM_1" 26 "PCS_LOG_NUM_MSGS" 17 "PCS_LOG_DLOG_4" 6 "PCS_LOG_DCDC_1" 25 "PCS_LOG_DCDC_IMPEDANCE_EST" 23 "PCS_LOG_CHG_STATISTICS" 24 "PCS_LOG_DCDC_HVBUS_PCHG_DATA" 10 "PCS_LOG_PHA_2" 1 "PCS_LOG_PHB_1" 16 "PCS_LOG_DLOG_3" 20 "PCS_LOG_CHG_NO_FLOW" 21 "PCS_LOG_CHG_LINE_OFFSET" 19 "PCS_LOG_DCDC_5" 15 "PCS_LOG_DLOG_2" 2 "PCS_LOG_PHC_1" ;
VAL_ 864 VCLEFT_matrixIndex 0 "VCLEFT_AlertMatrix0" 1 "VCLEFT_AlertMatrix1" 2 "VCLEFT_AlertMatrix2" 3 "VCLEFT_AlertMatrix3" 4 "VCLEFT_AlertMatrix4" 5 "VCLEFT_AlertMatrix5" ;
VAL_ 1930 HVP_pyroAoutMultiplexer 8 "PYRO_AOUT_RREF" 5 "PYRO_AOUT_IGL1" 0 "PYRO_AOUT_VST1" 6 "PYRO_AOUT_GND" 7 "PYRO_AOUT_RM" 4 "PYRO_AOUT_IGH1" 2 "PYRO_AOUT_ER1" 1 "PYRO_AOUT_VST2" 3 "PYRO_AOUT_ER2" ;
VAL_ 1930 HVP_pyroFiringHandle 10 "PYRO_HANDLE_ENS_CRASH" 5 "PYRO_HANDLE_OVER_VOLTAGE" 2 "PYRO_HANDLE_OVER_DISCHARGE_CURRENT" 12 "PYRO_HANDLE_PACK_NEGATIVE_CTR_ARC" 4 "PYRO_HANDLE_OVER_CURRENT" 7 "PYRO_HANDLE_TEMPERATURE" 1 "PYRO_HANDLE_HVP" 9 "PYRO_HANDLE_SHUNT_MIA" 3 "PYRO_HANDLE_OVER_CHARGE_CURRENT" 6 "PYRO_HANDLE_UNDER_VOLTAGE" 11 "PYRO_HANDLE_PACK_POSITIVE_CTR_ARC" 8 "PYRO_HANDLE_OPEN_IMMEDIATELY" ;
VAL_ 1930 HVP_pyroStatus 0 "STATUS_UNKNOWN" 1 "STATUS_OK" 3 "STATUS_ACTIVATED" 2 "STATUS_FAULT" ;
VAL_ 931 VCRIGHT_gloveboxSelfTest 2 "GLOVEBOX_EFUSE_TESTSTATE_COMPLETE" 0 "GLOVEBOX_EFUSE_TESTSTATE_INIT" 3 "GLOVEBOX_EFUSE_TESTSTATE_FAIL" 1 "GLOVEBOX_EFUSE_TESTSTATE_RUN" ;
VAL_ 12 UI_cellSignalBars 5 "FIVE" 7 "SNA" 1 "ONE" 2 "TWO" 0 "ZERO" 4 "FOUR" 3 "THREE" ;
VAL_ 12 UI_cellNetworkTechnology 15 "CELL_NETWORK_SNA" 5 "CELL_NETWORK_HSUPA" 3 "CELL_NETWORK_UMTS" 0 "CELL_NETWORK_NONE" 6 "CELL_NETWORK_HSPA" 7 "CELL_NETWORK_LTE" 1 "CELL_NETWORK_GPRS" 2 "CELL_NETWORK_EDGE" 4 "CELL_NETWORK_HSDPA" ;
VAL_ 12 UI_factoryReset 0 "NONE_SNA" 3 "CUSTOMER" 2 "DIAGNOSTIC" 1 "DEVELOPER" ;
VAL_ 12 UI_autopilotTrial 0 "NONE" 1 "START" 3 "ACTIVE" 2 "STOP" ;
VAL_ 960 VCRIGHT_matrixIndex 3 "VCRIGHT_AlertMatrix3" 5 "VCRIGHT_AlertMatrix5" 2 "VCRIGHT_AlertMatrix2" 4 "VCRIGHT_AlertMatrix4" 1 "VCRIGHT_AlertMatrix1" 0 "VCRIGHT_AlertMatrix0" ;
VAL_ 609 VCFRONT_IBSTemperature 32767 "VCFRONT_IBS_TEMPERATURE_SNA" ;
VAL_ 530 BMS_smStateRequest 5 "BMS_CLEAR_FAULT" 6 "BMS_FAULT" 4 "BMS_FEIM" 0 "BMS_STANDBY" 2 "BMS_SUPPORT" 9 "BMS_SNA" 1 "BMS_DRIVE" 8 "BMS_TEST" 7 "BMS_WELD" 3 "BMS_CHARGE" ;
VAL_ 530 BMS_chgPowerAvailable 2047 "SNA" ;
VAL_ 530 BMS_diLimpRequest 1 "LIMP_REQUEST_WELDED" 0 "LIMP_REQUEST_NONE" ;
VAL_ 530 BMS_state 5 "BMS_CLEAR_FAULT" 6 "BMS_FAULT" 4 "BMS_FEIM" 0 "BMS_STANDBY" 2 "BMS_SUPPORT" 9 "BMS_SNA" 1 "BMS_DRIVE" 8 "BMS_TEST" 7 "BMS_WELD" 3 "BMS_CHARGE" ;
VAL_ 530 BMS_isolationResistance 1023 "SNA" ;
VAL_ 530 BMS_hvState 6 "HV_UP" 5 "HV_UP_FOR_DC_CHARGE" 0 "HV_DOWN" 2 "HV_GOING_DOWN" 1 "HV_COMING_UP" 4 "HV_UP_FOR_CHARGE" 3 "HV_UP_FOR_DRIVE" ;
VAL_ 530 BMS_ecuLogUploadRequest 3 "REQUEST_PRIORITY_3" 2 "REQUEST_PRIORITY_2" 0 "REQUEST_PRIORITY_NONE" 1 "REQUEST_PRIORITY_1" ;
VAL_ 530 BMS_uiChargeStatus 3 "BMS_CHARGING" 4 "BMS_CHARGE_COMPLETE" 0 "BMS_DISCONNECTED" 2 "BMS_ABOUT_TO_CHARGE" 5 "BMS_CHARGE_STOPPED" 1 "BMS_NO_POWER" ;
VAL_ 530 BMS_contactorState 0 "BMS_CTRSET_SNA" 1 "BMS_CTRSET_OPEN" 3 "BMS_CTRSET_CLOSING" 2 "BMS_CTRSET_OPENING" 5 "BMS_CTRSET_WELDED" 6 "BMS_CTRSET_BLOCKED" 4 "BMS_CTRSET_CLOSED" ;
VAL_ 739 VCRIGHT_seatStatus2Index 4 "VCRIGHT_OCCUPANCY" 0 "VCRIGHT_SEAT_HEAT_FRONT" 2 "VCRIGHT_SEAT_HEAT_REARC" 3 "VCRIGHT_SEAT_HEAT_REARR" 5 "VCRIGHT_SEAT_STATUS_2_INDEX_COUNT" 1 "VCRIGHT_SEAT_HEAT_REARL_CUSHION" ;
VAL_ 615 DI_massConfidence 1 "MASS_CONFIDED" 0 "MASS_NOT_CONFIDED" ;
VAL_ 615 DI_trailerDetected 0 "TRAILER_NOT_DETECTED" 1 "TRAILER_DETECTED" ;
VAL_ 615 DI_tireFitment 0 "FITMENT_SQUARE" 3 "FITMENT_SNA" 1 "FITMENT_STAGGERED" ;
VAL_ 1314 VCLEFT_alertClearedID 295 "VCLEFT_a295_buckleFaultedRearL" 293 "VCLEFT_a293_occupancyFaultedRearC" 189 "VCLEFT_a189_latchUnableToRearmR" 237 "VCLEFT_a237_lumbarOverPresB" 130 "VCLEFT_a130_blowerICWarning" 215 "VCLEFT_a215_currentDesyncWarning" 202 "VCLEFT_a202_epbmUnderIStatic" 320 "VCLEFT_a320_windowPwrDerivFDBG" 100 "VCLEFT_a100_CANbus_MIA" 321 "VCLEFT_a321_windowPwrDeriv2FDBG" 46 "VCLEFT_a046_Task1000msError" 181 "VCLEFT_a181_rearDoorLatchRehome" 284 "VCLEFT_a284_blowerFbkSanity" 12 "VCLEFT_a012_CPUReset" 277 "VCLEFT_a277_BLELeftUnderVoltage" 305 "VCLEFT_a305_rearIntHandleShorted" 163 "VCLEFT_a163_windowEncoderStallR" 185 "VCLEFT_a185_summonAborted" 114 "VCLEFT_a114_ESP_MIA" 252 "VCLEFT_a252_seatUncalBack" 107 "VCLEFT_a107_BMS_MIA" 62 "VCLEFT_a062_XCPWasConnected" 268 "VCLEFT_a268_seatBackHCEncStlDbg" 322 "VCLEFT_a322_windowPwrDerivRDBG" 108 "VCLEFT_a108_DIS_MIA" 136 "VCLEFT_a136_brakeSwitchMismatch" 119 "VCLEFT_a119_SCCM_MIA" 294 "VCLEFT_a294_occupancyFaultedRearR" 287 "VCLEFT_a287_windowSpeedInvalidR" 150 "VCLEFT_a150_windowPinchFront" 106 "VCLEFT_a106_PCS_MIA" 307 "VCLEFT_a307_handleDisconnectedR" 13 "VCLEFT_a013_AlertManagerFault" 206 "VCLEFT_a206_epbWrongDirection" 113 "VCLEFT_a113_UI_MIA" 283 "VCLEFT_a283_latchUnexpectedArmR" 228 "VCLEFT_a228_seatEncOverTrack" 15 "VCLEFT_a015_NVMMAlert" 133 "VCLEFT_a133_blowerLowRPMCBang" 153 "VCLEFT_a153_windowUncalRear" 269 "VCLEFT_a269_seatTiltHCEncStlDbg" 275 "VCLEFT_a275_leftTurnLightFault" 10 "VCLEFT_a010_ExtSupplyVoltError" 99 "VCLEFT_a099_PARK_MIA" 231 "VCLEFT_a231_seatEncOverLift" 139 "VCLEFT_a139_BLERearPowerCycled" 264 "VCLEFT_a264_seatBackStallDebug" 253 "VCLEFT_a253_seatUncalTilt" 101 "VCLEFT_a101_PM_MIA" 59 "VCLEFT_a059_inputResistanceHigh" 219 "VCLEFT_a219_motorCurrentDropout" 120 "VCLEFT_a120_DI_DRIVE_MIA" 160 "VCLEFT_a160_windowUndercurrentF" 220 "VCLEFT_a220_seatCurrStallTrack" 203 "VCLEFT_a203_epbmOverIStatic" 310 "VCLEFT_a310_mirrorFoldStall" 222 "VCLEFT_a222_seatCurrStallTilt" 243 "VCLEFT_a243_seatHeatShortRearL" 197 "VCLEFT_a197_VEHCANUndertrminate" 158 "VCLEFT_a158_windowPinchOverideF" 129 "VCLEFT_a129_blowerICLatchFault" 230 "VCLEFT_a230_seatEncOverTilt" 236 "VCLEFT_a236_lumbarOverPresA" 116 "VCLEFT_a116_VCRIGHT_MIA" 205 "VCLEFT_a205_epbmOverIDyn" 260 "VCLEFT_a260_latchDisarmDelayR" 221 "VCLEFT_a221_seatCurrStallBack" 209 "VCLEFT_a209_epbStateMisTime" 104 "VCLEFT_a104_DAS_MIA" 161 "VCLEFT_a161_windowUndercurrentR" 301 "VCLEFT_a301_swcOverVoltage" 232 "VCLEFT_a232_seatCurrUnderTrack" 183 "VCLEFT_a183_doorStateFactoryTest" 151 "VCLEFT_a151_windowPinchRear" 132 "VCLEFT_a132_blowerSoftStall" 159 "VCLEFT_a159_windowPinchOverideR" 60 "VCLEFT_a060_engineeringBuild" 137 "VCLEFT_a137_VCSECPowerCycled" 170 "VCLEFT_a170_windowCurrentPeakR" 290 "VCLEFT_a290_occupancyFaultedFront" 210 "VCLEFT_a210_epbStateTime" 152 "VCLEFT_a152_windowUncalFront" 242 "VCLEFT_a242_seatHeatIRearL" 240 "VCLEFT_a240_seatHeatShortFront" 30 "VCLEFT_a030_ECULogUploadRequest" 102 "VCLEFT_a102_PTC_MIA" 235 "VCLEFT_a235_seatCurrUnderLift" 300 "VCLEFT_a300_swcUnderVoltage" 204 "VCLEFT_a204_epbmUnderIDyn" 323 "VCLEFT_a323_windowPwrDeriv2RDBG" 111 "VCLEFT_a111_EPBR_MIA" 45 "VCLEFT_a045_Task100msError" 112 "VCLEFT_a112_EPBL_MIA" 276 "VCLEFT_a276_mirrorDebug" 190 "VCLEFT_a190_eFuseMgmtVbatFused" 117 "VCLEFT_a117_VCLEFT_MIA" 42 "VCLEFT_a042_HighStackUsage" 225 "VCLEFT_a225_seatEncStallBack" 2 "VCLEFT_a002_PowerLossReset" 182 "VCLEFT_a182_emergencyLatchRel" 41 "VCLEFT_a041_HighCPULoad" 103 "VCLEFT_a103_CP_MIA" 61 "VCLEFT_a061_XCPConnected" 239 "VCLEFT_a239_seatHeatIFront" 285 "VCLEFT_a285_blowerChipComms" 278 "VCLEFT_a278_BLERearUnderVoltage" 306 "VCLEFT_a306_handleDisconnectedF" 156 "VCLEFT_a156_windowNoInputFront" 131 "VCLEFT_a131_blowerICTransFault" 105 "VCLEFT_a105_TAS_MIA" 265 "VCLEFT_a265_seatTiltStallDebug" 270 "VCLEFT_a270_seatLiftHCEncStlDbg" 286 "VCLEFT_a286_windowSpeedInvalidF" 272 "VCLEFT_a272_vhclPwrStateMsmtch" 303 "VCLEFT_a303_eFuseMgmtWindowLift" 241 "VCLEFT_a241_seatHeatMIAFront" 212 "VCLEFT_a212_epbmOverIStaticNew" 143 "VCLEFT_a143_mirrorManuallyFolded" 217 "VCLEFT_a217_SPI_MIA_debugData2" 207 "VCLEFT_a207_epbmEnableWrong" 164 "VCLEFT_a164_windowFactoryTest" 292 "VCLEFT_a292_occupancyFaultedRearL" 211 "VCLEFT_a211_epbmUnderIStaticNew" 227 "VCLEFT_a227_seatEncStallLift" 43 "VCLEFT_a043_Task1msError" 141 "VCLEFT_a141_12VAuxPowerTrip" 234 "VCLEFT_a234_seatCurrUnderTilt" 63 "VCLEFT_a063_SwitchFault" 201 "VCLEFT_a201_motorDutyEncDisabl" 214 "VCLEFT_a214_epbmOverIDynNew" 162 "VCLEFT_a162_windowEncoderStallF" 3 "VCLEFT_a003_SWAssertion" 191 "VCLEFT_a191_TLCOvercurrent" 308 "VCLEFT_a308_sirenMIA" 254 "VCLEFT_a254_seatUncalLift" 216 "VCLEFT_a216_SPI_MIA_debugData1" 98 "VCLEFT_a098_DI_THERMAL_MIA" 280 "VCLEFT_a280_latchDidNotDisarmF" 155 "VCLEFT_a155_windowThermalRear" 44 "VCLEFT_a044_Task10msError" 97 "VCLEFT_a097_CMP_MIA" 169 "VCLEFT_a169_windowCurrentPeakF" 229 "VCLEFT_a229_seatEncOverBack" 259 "VCLEFT_a259_latchDisarmDelayF" 251 "VCLEFT_a251_seatUncalTrack" 115 "VCLEFT_a115_VCSEC_MIA" 223 "VCLEFT_a223_seatCurrStallLift" 22 "VCLEFT_a022_TaskInitError" 281 "VCLEFT_a281_latchDidNotDisarmR" 167 "VCLEFT_a167_windowDebugPinchF" 282 "VCLEFT_a282_latchUnexpectedArmF" 0 "VCLEFT_ALERT_DO_NOT_USE_ZERO" 274 "VCLEFT_a274_handleStuckActiveR" 138 "VCLEFT_a138_consoleDoorAssist" 31 "VCLEFT_a031_UDSActive" 244 "VCLEFT_a244_seatHeatMIARearL" 187 "VCLEFT_a187_latchReleaseFailedR" 64 "VCLEFT_a064_busSleepReqTimeout" 304 "VCLEFT_a304_frontIntHandleShorted" 157 "VCLEFT_a157_windowNoInputRear" 263 "VCLEFT_a263_seatTrackStallDebug" 309 "VCLEFT_a309_brakeSwitchFaulted" 302 "VCLEFT_a302_blowerGeneralFault" 273 "VCLEFT_a273_handleStuckActiveF" 166 "VCLEFT_a166_windowDebug" 172 "VCLEFT_a172_SPI_MIA" 180 "VCLEFT_a180_frontDoorLatchRehome" 213 "VCLEFT_a213_epbmUnderIDynNew" 168 "VCLEFT_a168_windowDebugPinchR" 218 "VCLEFT_a218_motorDriverFault" 233 "VCLEFT_a233_seatCurrUnderBack" 200 "VCLEFT_a200_motorPhantomEncoder" 238 "VCLEFT_a238_lumbarValveMIA" 266 "VCLEFT_a266_seatLiftStallDebug" 186 "VCLEFT_a186_latchReleaseFailedF" 1 "VCLEFT_a001_WatchdogReset" 134 "VCLEFT_a134_SteerColUpDownUnCal" 21 "VCLEFT_a021_TaskSchedulerError" 224 "VCLEFT_a224_seatEncStallTrack" 188 "VCLEFT_a188_latchUnableToRearmF" 291 "VCLEFT_a291_buckleFaultedFront" 154 "VCLEFT_a154_windowThermalFront" 226 "VCLEFT_a226_seatEncStallTilt" 279 "VCLEFT_a279_VCSECUnderVoltage" 109 "VCLEFT_a109_RCM_MIA" 165 "VCLEFT_a165_windowFactoryTest2" 135 "VCLEFT_a135_SteerColInOutUnCal" 208 "VCLEFT_a208_epbFaulted" 110 "VCLEFT_a110_GTW_MIA" 196 "VCLEFT_a196_VEHCANOverterminate" 267 "VCLEFT_a267_seatTrackHCEncStlDbg" 140 "VCLEFT_a140_BLELeftPowerCycled" 324 "VCLEFT_a324_mirrorHeatFault" 118 "VCLEFT_a118_VCFRONT_MIA" ;
VAL_ 784 HVP_buildType 1 "INFO_PLATFORM_BUILD" 3 "INFO_TRACEABLE_CI_BUILD" 4 "INFO_MFG_BUILD" 2 "INFO_LOCAL_BUILD" 0 "INFO_UNKNOWN_BUILD" ;
VAL_ 784 HVP_infoIndex 25 "INFO_PACKAGE_PN_1_7" 30 "INFO_PACKAGE_SN_8_14" 27 "INFO_PACKAGE_PN_15_20" 0 "INFO_DEPRECATED_0" 29 "INFO_PACKAGE_SN_1_7" 10 "INFO_BUILD_HWID_COMPONENTID" 14 "INFO_BOOTLOADER_SVN" 31 "INFO_SUBCOMPONENT_GITHASH" 19 "INFO_VERSION_DEPRECATED" 7 "INFO_DEPRECATED_7" 255 "INFO_END" 9 "INFO_DEPRECATED_9" 6 "INFO_DEPRECATED_6" 20 "INFO_UDS_PROTOCOL_BOOTCRC" 3 "INFO_DEPRECATED_3" 22 "INFO_VARIANTCRC" 17 "INFO_APP_GITHASH" 8 "INFO_DEPRECATED_8" 26 "INFO_PACKAGE_PN_8_14" 5 "INFO_DEPRECATED_5" 16 "INFO_SUBCOMPONENT" 13 "INFO_APP_CRC" 2 "INFO_DEPRECATED_2" 4 "INFO_DEPRECATED_4" 15 "INFO_BOOTLOADER_CRC" 1 "INFO_DEPRECATED_1" 11 "INFO_PCBAID_ASSYID_USAGEID" 18 "INFO_BOOTLOADER_GITHASH" ;
VAL_ 962 VCLEFT_rearRightOccupancySwitch 2 "SWITCH_ON" 0 "SWITCH_SNA" 3 "SWITCH_FAULT" 1 "SWITCH_OFF" ;
VAL_ 962 VCLEFT_rearLeftOccupancySwitch 2 "SWITCH_ON" 0 "SWITCH_SNA" 3 "SWITCH_FAULT" 1 "SWITCH_OFF" ;
VAL_ 962 VCLEFT_rearCenterOccupancySwitch 2 "SWITCH_ON" 0 "SWITCH_SNA" 3 "SWITCH_FAULT" 1 "SWITCH_OFF" ;
VAL_ 962 VCLEFT_rearLeftBuckleSwitch 2 "SWITCH_ON" 0 "SWITCH_SNA" 3 "SWITCH_FAULT" 1 "SWITCH_OFF" ;
VAL_ 962 VCLEFT_frontOccupancySwitch 2 "SWITCH_ON" 0 "SWITCH_SNA" 3 "SWITCH_FAULT" 1 "SWITCH_OFF" ;
VAL_ 962 VCLEFT_frontBuckleSwitch 2 "SWITCH_ON" 0 "SWITCH_SNA" 3 "SWITCH_FAULT" 1 "SWITCH_OFF" ;
VAL_ 962 VCLEFT_frontSeatLumbarOut 2 "SWITCH_ON" 0 "SWITCH_SNA" 3 "SWITCH_FAULT" 1 "SWITCH_OFF" ;
VAL_ 962 VCLEFT_frontSeatLumbarIn 2 "SWITCH_ON" 0 "SWITCH_SNA" 3 "SWITCH_FAULT" 1 "SWITCH_OFF" ;
VAL_ 962 VCLEFT_frontSeatLumbarUp 2 "SWITCH_ON" 0 "SWITCH_SNA" 3 "SWITCH_FAULT" 1 "SWITCH_OFF" ;
VAL_ 962 VCLEFT_frontSeatLumbarDown 2 "SWITCH_ON" 0 "SWITCH_SNA" 3 "SWITCH_FAULT" 1 "SWITCH_OFF" ;
VAL_ 962 VCLEFT_frontSeatBackrestForward 2 "SWITCH_ON" 0 "SWITCH_SNA" 3 "SWITCH_FAULT" 1 "SWITCH_OFF" ;
VAL_ 962 VCLEFT_frontSeatBackrestBack 2 "SWITCH_ON" 0 "SWITCH_SNA" 3 "SWITCH_FAULT" 1 "SWITCH_OFF" ;
VAL_ 962 VCLEFT_frontSeatLiftUp 2 "SWITCH_ON" 0 "SWITCH_SNA" 3 "SWITCH_FAULT" 1 "SWITCH_OFF" ;
VAL_ 962 VCLEFT_frontSeatLiftDown 2 "SWITCH_ON" 0 "SWITCH_SNA" 3 "SWITCH_FAULT" 1 "SWITCH_OFF" ;
VAL_ 962 VCLEFT_frontSeatTiltUp 2 "SWITCH_ON" 0 "SWITCH_SNA" 3 "SWITCH_FAULT" 1 "SWITCH_OFF" ;
VAL_ 962 VCLEFT_swcLeftTiltLeft 2 "SWITCH_ON" 0 "SWITCH_SNA" 3 "SWITCH_FAULT" 1 "SWITCH_OFF" ;
VAL_ 962 VCLEFT_swcRightPressed 2 "SWITCH_ON" 0 "SWITCH_SNA" 3 "SWITCH_FAULT" 1 "SWITCH_OFF" ;
VAL_ 962 VCLEFT_frontSeatTiltDown 2 "SWITCH_ON" 0 "SWITCH_SNA" 3 "SWITCH_FAULT" 1 "SWITCH_OFF" ;
VAL_ 962 VCLEFT_frontSeatTrackForward 2 "SWITCH_ON" 0 "SWITCH_SNA" 3 "SWITCH_FAULT" 1 "SWITCH_OFF" ;
VAL_ 962 VCLEFT_swcRightTiltRight 2 "SWITCH_ON" 0 "SWITCH_SNA" 3 "SWITCH_FAULT" 1 "SWITCH_OFF" ;
VAL_ 962 VCLEFT_swcRightTiltLeft 2 "SWITCH_ON" 0 "SWITCH_SNA" 3 "SWITCH_FAULT" 1 "SWITCH_OFF" ;
VAL_ 962 VCLEFT_frontSeatTrackBack 2 "SWITCH_ON" 0 "SWITCH_SNA" 3 "SWITCH_FAULT" 1 "SWITCH_OFF" ;
VAL_ 962 VCLEFT_swcLeftPressed 2 "SWITCH_ON" 0 "SWITCH_SNA" 3 "SWITCH_FAULT" 1 "SWITCH_OFF" ;
VAL_ 962 VCLEFT_rightMirrorTilt 4 "MIRROR_TILT_LEFT" 2 "MIRROR_TILT_UP" 3 "MIRROR_TILT_RIGHT" 0 "MIRROR_TILT_STOP" 1 "MIRROR_TILT_DOWN" ;
VAL_ 962 VCLEFT_swcLeftTiltRight 2 "SWITCH_ON" 0 "SWITCH_SNA" 3 "SWITCH_FAULT" 1 "SWITCH_OFF" ;
VAL_ 962 VCLEFT_switchStatusIndex 1 "VCLEFT_SWITCH_STATUS_INDEX_1" 2 "VCLEFT_SWITCH_STATUS_INDEX_INVALID" 0 "VCLEFT_SWITCH_STATUS_INDEX_0" ;
VAL_ 816 SCCM_infoBuildType 1 "INFO_PLATFORM_BUILD" 3 "INFO_TRACEABLE_CI_BUILD" 4 "INFO_MFG_BUILD" 2 "INFO_LOCAL_BUILD" 0 "INFO_UNKNOWN_BUILD" ;
VAL_ 816 SCCM_infoIndex 17 "SCCM_INFO_APP_SVNHASH" 10 "SCCM_INFO_BUILD_HWID_COMPONENTID" 13 "SCCM_INFO_APP_CRC" 255 "SCCM_INFO_END" 16 "SCCM_INFO_SUBCOMPONENT1" 20 "SCCM_INFO_UDS_PROTOCOL_BOOTCRC" 11 "SCCM_INFO_PCBAID_ASSYID_USAGEID" 14 "SCCM_INFO_BOOTLOADER_SVN" 18 "SCCM_INFO_BOOTLOADER_SVNHASH" ;
VAL_ 529 RCM_driverOrientationInitStatus 7 "SNA" 4 "RCM_DRIVER_ORIENTATION_MISMATCH_DEFAULT_RHD" 2 "RCM_DRIVER_ORIENTATION_MATCHED_RHD" 1 "RCM_DRIVER_ORIENTATION_MATCHED_LHD" 3 "RCM_DRIVER_ORIENTATION_MISMATCH_DEFAULT_LHD" 0 "RCM_DRIVER_ORIENTATION_INIT_NOT_COMPLETE" ;
VAL_ 529 RCM_imuOffsetLearnState 0 "IMU_OFFSET_LEARNING_OFF" 2 "IMU_FAST_LEARNING_TIME" 1 "IMU_SLOW_LEARNING_DISTANCE" 3 "IMU_OFFSETS_UNABLE_TO_LEARN" ;
VAL_ 529 RCM_keepPowerReason 7 "RCM_INVALID_POWER_OFF_REQUEST" 4 "RCM_EDR_UPLOADING" 6 "RCM_INITIALIZATION_PHASE" 1 "RCM_IN_IDLE_MODE" 2 "RCM_CRASH_ALGO_ACTIVE" 5 "RCM_CANNOT_POWER_DOWN" 0 "RCM_NO_KEEP_POWER_REQUEST" 3 "RCM_EDR_STORING_TO_EEPROM" ;
VAL_ 529 RCM_edr2State 1 "RCM_EDR_STORED" 0 "RCM_EDR_EMPTY" 3 "RCM_EDR_UNAVAILABLE" 2 "RCM_EDR_LOCKED" ;
VAL_ 529 RCM_edr1State 1 "RCM_EDR_STORED" 0 "RCM_EDR_EMPTY" 3 "RCM_EDR_UNAVAILABLE" 2 "RCM_EDR_LOCKED" ;
VAL_ 529 RCM_seatTrackPositionPass 3 "SNA" 0 "RCM_SEAT_POSITION_NEAR" 1 "RCM_SEAT_POSITION_FAR" 2 "RCM_SEAT_POSITION_FAULTED" ;
VAL_ 529 RCM_seatTrackPositionDrvr 3 "SNA" 0 "RCM_SEAT_POSITION_NEAR" 1 "RCM_SEAT_POSITION_FAR" 2 "RCM_SEAT_POSITION_FAULTED" ;
VAL_ 529 RCM_vinLearnFlag 0 "RCM_VIN_NOT_STORED" 3 "SNA" 2 "RCM_VIN_STORED_MISMATCH" 1 "RCM_VIN_STORED" ;
VAL_ 529 RCM_alrSwitchStatus 3 "SNA" 0 "RCM_ALR_NOT_ENGAGED" 1 "RCM_ALR_ENGAGED" 2 "RCM_ALR_FAULTED" ;
VAL_ 529 RCM_airbagCutoffStatus 3 "SNA" 1 "RCM_PASSENGER_AIRBAG_DISABLED" 0 "RCM_PASSENGER_AIRBAG_ENABLED" ;
VAL_ 529 RCM_passAirbagIndicatorRequest 3 "SNA" 0 "RCM_PASSENGER_AIRBAG_INDICATOR_ON" 1 "RCM_PASSENGER_AIRBAG_INDICATOR_OFF" ;
VAL_ 529 RCM_warningIndicatorState 3 "SNA" 0 "RCM_WARNING_INDICATOR_OFF" 1 "RCM_WARNING_INDICATOR_ON" ;
VAL_ 529 RCM_armStatus 3 "SNA" 2 "ARMED_WITH_NOFIRE_CAL" 1 "RCM_ARMED" 0 "RCM_UNARMED" ;
VAL_ 577 VCFRONT_coolantAirPurgeBatState 4 "AIR_PURGE_STATE_PENDING" 1 "AIR_PURGE_STATE_ACTIVE" 3 "AIR_PURGE_STATE_INTERRUPTED" 0 "AIR_PURGE_STATE_INACTIVE" 2 "AIR_PURGE_STATE_COMPLETE" ;
VAL_ 577 VCFRONT_wasteHeatRequestType 2 "WASTE_TYPE_FULL" 1 "WASTE_TYPE_PARTIAL" 0 "WASTE_TYPE_NONE" ;
VAL_ 577 VCFRONT_coolantFlowPTReason 13 "DIS_FLOW_REQ" 0 "NONE" 1 "COOLANT_AIR_PURGE" 4 "ACTIVE_MANAGER_BATT" 11 "PCS_FLOW_REQ" 10 "PASSIVE_MANAGER_PT" 8 "OVERRIDE_PT" 7 "DAS_FLOW_REQ" 2 "NO_FLOW_REQ" 3 "OVERRIDE_BATT" 6 "BMS_FLOW_REQ" 9 "ACTIVE_MANAGER_PT" 5 "PASSIVE_MANAGER_BATT" 12 "DI_FLOW_REQ" ;
VAL_ 577 VCFRONT_coolantFlowBatReason 13 "DIS_FLOW_REQ" 0 "NONE" 1 "COOLANT_AIR_PURGE" 4 "ACTIVE_MANAGER_BATT" 11 "PCS_FLOW_REQ" 10 "PASSIVE_MANAGER_PT" 8 "OVERRIDE_PT" 7 "DAS_FLOW_REQ" 2 "NO_FLOW_REQ" 3 "OVERRIDE_BATT" 6 "BMS_FLOW_REQ" 9 "ACTIVE_MANAGER_PT" 5 "PASSIVE_MANAGER_BATT" 12 "DI_FLOW_REQ" ;
VAL_ 770 VCLEFT_infoAssemblyId 1 "ASSEMBLY1" 255 "ASSEMBLY_SNA" ;
VAL_ 770 VCLEFT_infoBuildType 1 "INFO_PLATFORM_BUILD" 3 "INFO_TRACEABLE_CI_BUILD" 4 "INFO_MFG_BUILD" 2 "INFO_LOCAL_BUILD" 0 "INFO_UNKNOWN_BUILD" ;
VAL_ 770 VCLEFT_infoIndex 14 "BC_INFO_BOOTLOADER_SVN" 6 "BC_INFO_DEPRECATED_6" 20 "BC_INFO_UDS_PROTOCOL_BOOTCRC" 24 "BC_INFO_SUBCOMPONENT3" 1 "BC_INFO_DEPRECATED_1" 31 "BC_INFO_SUBCOMPONENT4" 19 "BC_INFO_VERSION_DEPRECATED" 10 "BC_INFO_BUILD_HWID_COMPONENTID" 0 "BC_INFO_DEPRECATED_0" 5 "BC_INFO_DEPRECATED_5" 11 "BC_INFO_PCBAID_ASSYID_USAGEID" 18 "BC_INFO_BOOTLOADER_GITHASH" 3 "BC_INFO_DEPRECATED_3" 15 "BC_INFO_BOOTLOADER_CRC" 4 "BC_INFO_DEPRECATED_4" 16 "BC_INFO_SUBCOMPONENT1" 255 "BC_INFO_END" 9 "BC_INFO_DEPRECATED_9" 13 "BC_INFO_APP_CRC" 2 "BC_INFO_DEPRECATED_2" 23 "BC_INFO_SUBCOMPONENT2" 7 "BC_INFO_DEPRECATED_7" 8 "BC_INFO_DEPRECATED_8" 17 "BC_INFO_APP_GITHASH" ;
VAL_ 1081 VCSEC_nmWakeUpReason 5 "VCSEC_WAKEUP_REASON_LOCK_STATE_CHANGE" 0 "VCSEC_WAKEUP_REASON_NONE" 6 "VCSEC_WAKEUP_REASON_FLASHERS" 1 "VCSEC_WAKEUP_REASON_ECU_SPECIFIC" 7 "VCSEC_WAKEUP_REASON_CABIN_HOT" 2 "VCSEC_WAKEUP_REASON_SWITCH_INPUT" 3 "VCSEC_WAKEUP_REASON_RESET" 4 "VCSEC_WAKEUP_REASON_RKE_ACTION" ;
VAL_ 1081 VCSEC_nmKeepAwakeReason 2 "VCSEC_KEEPAWAKE_REASON_ALARM_TRIGGERED" 0 "VCSEC_KEEPAWAKE_REASON_NONE_SNA" 1 "VCSEC_KEEPAWAKE_REASON_WALK_AWAY_LOCK_ACTIVE" 15 "VCSEC_KEEPAWAKE_REASON_MULTIPLE" 3 "VCSEC_KEEPAWAKE_REASON_CABIN_HOT" 4 "VCSEC_KEEPAWAKE_REASON_UDS_ACTIVE" ;
VAL_ 405 DIS_wasteState 2 "DI_WASTE_ON" 1 "DI_WASTE_AVAILABLE" 0 "DI_WASTE_UNAVAILABLE" ;
VAL_ 982 DI_oilPumpFetCTemp 255 "SNA" ;
VAL_ 982 DI_oilPumpFetBTemp 255 "SNA" ;
VAL_ 982 DI_oilPumpFetATemp 255 "SNA" ;
VAL_ 1321 SCCM_firmwareType 0 "APPLICATION" 2 "BOOTLOADER_UPDATER" 1 "BOOTLOADER" ;
VAL_ 264 DI_axleSpeed -32768 "SNA" ;
VAL_ 264 DI_torqueActual -4096 "SNA" ;
VAL_ 264 DI_torqueCommand -4096 "SNA" ;
VAL_ 691 VCRIGHT_cabinTempBreathLevel 255 "SNA" ;
VAL_ 691 VCRIGHT_solarLoadOnVehicle 255 "SNA" ;
VAL_ 691 VCRIGHT_cabinTempInteriorSunnyL2 240 "SNA" ;
VAL_ 691 VCRIGHT_cabinTempTopPadAir 240 "SNA" ;
VAL_ 691 VCRIGHT_cabinTempSideGlassRight 255 "SNA" ;
VAL_ 691 VCRIGHT_solarLoadLeftOccupant 127 "SNA" ;
VAL_ 691 VCRIGHT_cabinTempInteriorL2 240 "SNA" ;
VAL_ 691 VCRIGHT_hvacAirflowReason 0 "HVAC_OFF" 8 "COLD_DUCT_LOCKOUT" 12 "EVAP_DRYING" 13 "NONE" 10 "CABIN_OVERHEAT_PROTECT" 7 "OCCUPANT_CONVECTION_REQUIREMENT" 5 "STRATIFICATION_GLASS_ROOF" 3 "CABIN_TEMPERATURE_CONTROL" 1 "MANUAL_FAN_SPEED" 9 "CABIN_PURGE" 11 "SCREEN_PROTECTION" 2 "UI_SHORTCUT" 6 "STRATIFICATION_INTERIOR_SURFACES" 4 "MINIMUM_AUTO_AIRFLOW" ;
VAL_ 691 VCRIGHT_cabinTempInteriorSunnyL3 240 "SNA" ;
VAL_ 691 VCRIGHT_solarLoadRightOccupant 127 "SNA" ;
VAL_ 691 VCRIGHT_cabinTempSideGlassLeft 255 "SNA" ;
VAL_ 691 VCRIGHT_tempIncarCabinDeep 255 "SNA" ;
VAL_ 691 VCRIGHT_cabinTempInteriorL3 240 "SNA" ;
VAL_ 691 VCRIGHT_convectionDeliveredRight 255 "SNA" ;
VAL_ 691 VCRIGHT_hvacAirFlowModeRow2 6 "DEFROST_PANEL" 5 "DEFROST_FLOOR" 0 "NONE" 4 "DEFROST" 1 "FLOOR" 7 "DEFROST_PANEL_FLOOR" 3 "PANEL_FLOOR" 2 "PANEL" ;
VAL_ 691 VCRIGHT_cabinTempInteriorSunny 240 "SNA" ;
VAL_ 691 VCRIGHT_tempIncarCabinMid 250 "SNA" ;
VAL_ 691 VCRIGHT_tempHtrSurfaceModeledR 511 "SNA" ;
VAL_ 691 VCRIGHT_hvacAirFlowModeRow1 6 "DEFROST_PANEL" 5 "DEFROST_FLOOR" 0 "NONE" 4 "DEFROST" 1 "FLOOR" 7 "DEFROST_PANEL_FLOOR" 3 "PANEL_FLOOR" 2 "PANEL" ;
VAL_ 691 VCRIGHT_hvacAutoTransitionReason 16 "HVAC_OFF" 11 "DEFOG_OVERRIDE" 13 "SET_TEMP_HI" 15 "EVAP_DRYING" 0 "NONE" 3 "HUMIDITY_LOW" 7 "OCCUPANT_CONVECTION_REQUIREMENT" 1 "HUMIDITY_HIGH" 4 "TEMP_TARGET_BELOW_THRESHOLD" 6 "EXCESS_OCCUPANT_CONVECTION" 2 "HUMIDITY_MODERATE" 17 "END" 5 "TEMP_TARGET_ABOVE_THRESHOLD" 10 "BI_LEVEL_LANDING" 12 "SET_TEMP_LO" 14 "CABIN_PURGE" 9 "DUCTS_COLD" 8 "TEMP_TARGET_LOW" ;
VAL_ 691 VCRIGHT_cabinTempInterior 240 "SNA" ;
VAL_ 691 VCRIGHT_convectionDeliveredLeft 255 "SNA" ;
VAL_ 691 VCRIGHT_tempIncarCabinProbe 255 "SNA" ;
VAL_ 691 VCRIGHT_tempHtrSurfaceModeledL 511 "SNA" ;
VAL_ 691 VCRIGHT_hvacDuctTargetRight 255 "SNA" ;
VAL_ 691 VCRIGHT_solarLoadOnVehFiltered 255 "SNA" ;
VAL_ 691 VCRIGHT_cabinTempWindshield 255 "SNA" ;
VAL_ 691 VCRIGHT_convectionTargetRight 255 "SNA" ;
VAL_ 691 VCRIGHT_tempDuctModeledRight 511 "SNA" ;
VAL_ 691 VCRIGHT_tempDuctRight 511 "SNA" ;
VAL_ 691 VCRIGHT_hvacDuctTargetLeft 255 "SNA" ;
VAL_ 691 VCRIGHT_convectionTargetLeft 255 "SNA" ;
VAL_ 691 VCRIGHT_cabinTempGlassRoof 255 "SNA" ;
VAL_ 691 VCRIGHT_tempDuctLeft 511 "SNA" ;
VAL_ 691 VCRIGHT_tempDuctModeledLeft 511 "SNA" ;
VAL_ 691 VCRIGHT_logging1HzIndex 10 "HVAC_MISCELLANEOUS_2" 2 "HVAC_HUMIDITY_HEATER" 8 "HVAC_ACTUATOR_ZEROSTOP" 4 "HVAC_COMFORT_SOLAR" 9 "HVAC_MISCELLANEOUS_1" 5 "HEATER_AND_DUCT_TARGETS" 11 "END" 0 "HVAC_TEMP_SENSORS_AND_ESTIMATES_1" 3 "HVAC_STATUS_AIRFLOW" 7 "HVAC_ACTUATOR_ENDSTOP" 1 "HVAC_TEMP_SENSORS_AND_ESTIMATES_2" 6 "HVAC_ACTUATOR_VOLTAGES" ;
VAL_ 1736 EPBL_statsOutput 0 "EPB_STATIC_COUNT" 1 "EPB_DYNAMIC_COUNT" 2 "EPB_MAX_DATA" ;
VAL_ 1029 GTW_vinIndex 16 "Mux16" 17 "Mux17" 18 "Mux18" ;
VAL_ 1928 EPBL_learnedBrakeHWType 1 "EPB_BRAKE_HARDWARE_MANDO" 0 "EPB_BRAKE_HARDWARE_UNKNOWN" 2 "EPB_BRAKE_HARDWARE_BREMBO" ;
VAL_ 1928 EPBL_caliperState 5 "EPB_SAVED_CALIPERSTATE_SERVICE" 1 "EPB_SAVED_CALIPERSTATE_UNKNOWN" 4 "EPB_SAVED_CALIPERSTATE_OPEN" 2 "EPB_SAVED_CALIPERSTATE_REAPPLY" 0 "EPB_SAVED_CALIPERSTATE_UNSAVED" 3 "EPB_SAVED_CALIPERSTATE_PARK" ;
VAL_ 1928 EPBL_debugOutput 1 "EPB_DEBUG_1" 2 "EPB_DEBUG_2" 0 "EPB_DEBUG_0" ;
VAL_ 803 VCRIGHT_CPULoad1000msTask 255 "SNA" ;
VAL_ 803 VCRIGHT_CPULoad100msTask 255 "SNA" ;
VAL_ 803 VCRIGHT_CPULoad10msTask 255 "SNA" ;
VAL_ 803 VCRIGHT_CPULoad1msTask 255 "SNA" ;
VAL_ 803 VCRIGHT_CPULoadTotal 255 "SNA" ;
VAL_ 1342 CP_buildType 1 "INFO_PLATFORM_BUILD" 3 "INFO_TRACEABLE_CI_BUILD" 4 "INFO_MFG_BUILD" 2 "INFO_LOCAL_BUILD" 0 "INFO_UNKNOWN_BUILD" ;
VAL_ 1342 CP_infoIndex 25 "INFO_PACKAGE_PN_1_7" 30 "INFO_PACKAGE_SN_8_14" 27 "INFO_PACKAGE_PN_15_20" 0 "INFO_DEPRECATED_0" 29 "INFO_PACKAGE_SN_1_7" 10 "INFO_BUILD_HWID_COMPONENTID" 14 "INFO_BOOTLOADER_SVN" 31 "INFO_SUBCOMPONENT_GITHASH" 19 "INFO_VERSION_DEPRECATED" 7 "INFO_DEPRECATED_7" 255 "INFO_END" 9 "INFO_DEPRECATED_9" 6 "INFO_DEPRECATED_6" 20 "INFO_UDS_PROTOCOL_BOOTCRC" 3 "INFO_DEPRECATED_3" 22 "INFO_VARIANTCRC" 17 "INFO_APP_GITHASH" 8 "INFO_DEPRECATED_8" 26 "INFO_PACKAGE_PN_8_14" 5 "INFO_DEPRECATED_5" 16 "INFO_SUBCOMPONENT" 13 "INFO_APP_CRC" 2 "INFO_DEPRECATED_2" 4 "INFO_DEPRECATED_4" 15 "INFO_BOOTLOADER_CRC" 1 "INFO_DEPRECATED_1" 11 "INFO_PCBAID_ASSYID_USAGEID" 18 "INFO_BOOTLOADER_GITHASH" ;
VAL_ 611 VCRIGHT_hvacModelInitStatus 4 "INIT_FORWARD_CALC" 3 "INIT_FROM_SENSORS_PREDICTION_ERROR" 0 "NOT_INIT_WAIT_FOR_SENSORS" 5 "INIT_WAITING_FOR_SENSORS" 1 "NOT_INIT_WAIT_FOR_GTW" 2 "INIT_FROM_SENSORS" ;
VAL_ 611 VCRIGHT_hvacIntakeActuatorState 2 "HVACACTUATOR_STATE_COASTING" 1 "HVACACTUATOR_STATE_RUNNING" 0 "HVACACTUATOR_STATE_BRAKING" ;
VAL_ 611 VCRIGHT_hvacLowerModeActState 2 "HVACACTUATOR_STATE_COASTING" 1 "HVACACTUATOR_STATE_RUNNING" 0 "HVACACTUATOR_STATE_BRAKING" ;
VAL_ 611 VCRIGHT_hvacUpperModeActState 2 "HVACACTUATOR_STATE_COASTING" 1 "HVACACTUATOR_STATE_RUNNING" 0 "HVACACTUATOR_STATE_BRAKING" ;
VAL_ 611 VCRIGHT_hvacRHVaneActuatorState 2 "HVACACTUATOR_STATE_COASTING" 1 "HVACACTUATOR_STATE_RUNNING" 0 "HVACACTUATOR_STATE_BRAKING" ;
VAL_ 611 VCRIGHT_hvacLHVaneActuatorState 2 "HVACACTUATOR_STATE_COASTING" 1 "HVACACTUATOR_STATE_RUNNING" 0 "HVACACTUATOR_STATE_BRAKING" ;
VAL_ 611 VCRIGHT_hvacRHBleedActuatorState 2 "HVACACTUATOR_STATE_COASTING" 1 "HVACACTUATOR_STATE_RUNNING" 0 "HVACACTUATOR_STATE_BRAKING" ;
VAL_ 611 VCRIGHT_hvacLHBleedActuatorState 2 "HVACACTUATOR_STATE_COASTING" 1 "HVACACTUATOR_STATE_RUNNING" 0 "HVACACTUATOR_STATE_BRAKING" ;
VAL_ 611 VCRIGHT_hvacIntakeOperationMode 0 "HVACACTUATOR_OPERATION_MODE_NORMAL" 1 "HVACACTUATOR_OPERATION_MODE_CALIBRATION" ;
VAL_ 611 VCRIGHT_hvacLowerModeOpMode 0 "HVACACTUATOR_OPERATION_MODE_NORMAL" 1 "HVACACTUATOR_OPERATION_MODE_CALIBRATION" ;
VAL_ 611 VCRIGHT_hvacUpperModeOpMode 0 "HVACACTUATOR_OPERATION_MODE_NORMAL" 1 "HVACACTUATOR_OPERATION_MODE_CALIBRATION" ;
VAL_ 611 VCRIGHT_hvacRHVaneOperationMode 0 "HVACACTUATOR_OPERATION_MODE_NORMAL" 1 "HVACACTUATOR_OPERATION_MODE_CALIBRATION" ;
VAL_ 611 VCRIGHT_hvacLHVaneOperationMode 0 "HVACACTUATOR_OPERATION_MODE_NORMAL" 1 "HVACACTUATOR_OPERATION_MODE_CALIBRATION" ;
VAL_ 611 VCRIGHT_hvacRHBleedOperationMode 0 "HVACACTUATOR_OPERATION_MODE_NORMAL" 1 "HVACACTUATOR_OPERATION_MODE_CALIBRATION" ;
VAL_ 611 VCRIGHT_hvacLHBleedOperationMode 0 "HVACACTUATOR_OPERATION_MODE_NORMAL" 1 "HVACACTUATOR_OPERATION_MODE_CALIBRATION" ;
VAL_ 611 VCRIGHT_logging10HzIndex 1 "HVAC_ACTUATOR_POSITIONS" 0 "HVAC_ACTUATOR_TARGETS" 3 "END" 2 "HVAC_ACTUATOR_STATE" ;
VAL_ 932 PCS_matrixIndex 0 "PCS_AlertMatrix0" 1 "PCS_AlertMatrix1" ;
VAL_ 1925 DBG_dynoOLParamTuneSelector3 0 "None" 2 "Rr" 3 "Lm" 1 "Rs" 5 "Llr" 4 "Lls" ;
VAL_ 1925 DBG_dynoOLParamTuneSelector2 0 "None" 2 "Rr" 3 "Lm" 1 "Rs" 5 "Llr" 4 "Lls" ;
VAL_ 1925 DBG_dynoOLParamTuneSelector1 0 "None" 2 "Rr" 3 "Lm" 1 "Rs" 5 "Llr" 4 "Lls" ;
VAL_ 1925 DBG_dynoOLSelector 5 "IQmax" 2 "GenSineI" 0 "Normal" 7 "Generic14BitSignals" 1 "GenSineT" 6 "ParamTune" 3 "GenSineM" 4 "GenSineV" 8 "Generic8BitSignals" ;
VAL_ 1885 CP_sensorDataSelect 0 "CP_SENSOR_DOOR_COUNTS" 7 "CP_SENSOR_RAILS" 2 "CP_SENSOR_DOOR" 4 "CP_SENSOR_INDUCTIVE_DOOR" 3 "CP_SENSOR_LATCH" 8 "CP_SENSOR_PROX" 9 "CP_SENSOR_PILOT" 5 "CP_SENSOR_FAULT_LINE" 6 "CP_SENSOR_UHF" 1 "CP_SENSOR_PIN_TEMP" 10 "CP_SENSOR_PILOT2" ;
VAL_ 626 VCLEFT_epbFaultStatus 1 "EPB_STATUS_RETRY" 3 "EPB_STATUS_FAULT_IDLE" 0 "EPB_STATUS_NOMINAL" 2 "EPB_STATUS_FAULT" ;
VAL_ 626 VCLEFT_epbmFaultStatus 1 "EPB_STATUS_RETRY" 3 "EPB_STATUS_FAULT_IDLE" 0 "EPB_STATUS_NOMINAL" 2 "EPB_STATUS_FAULT" ;
VAL_ 626 VCLEFT_epbUnitStatus 14 "EPB_STATUS_SUMMON" 1 "EPB_STATUS_OPEN" 9 "EPB_STATUS_DYNAMIC_APPLYING" 21 "EPB_STATUS_COUNT" 12 "EPB_STATUS_PARK_PENDING" 13 "EPB_STATUS_WINCHMODE_PENDING" 6 "EPB_STATUS_WINCHMODE" 3 "EPB_STATUS_PARK" 0 "EPB_STATUS_UNKNOWN" 4 "EPB_STATUS_START" 18 "EPB_STATUS_RELEASING_FOR_EXTERNAL_PARK" 19 "EPB_STATUS_EXTERNAL_PARKING" 17 "EPB_STATUS_EXTERNAL_DYNAMIC" 10 "EPB_STATUS_RELEASING" 15 "EPB_STATUS_SUMMON_RELEASING" 11 "EPB_STATUS_SERVICE_RELEASING" 7 "EPB_STATUS_WINCHMODE_RELEASING" 16 "EPB_STATUS_SUMMON_PARKING" 8 "EPB_STATUS_PARKING" 2 "EPB_STATUS_DYNAMIC" 5 "EPB_STATUS_SERVICE" 20 "EPB_STATUS_DYNAMIC_PARKING" ;
VAL_ 626 VCLEFT_epbmUnitStatus 14 "EPB_STATUS_SUMMON" 1 "EPB_STATUS_OPEN" 9 "EPB_STATUS_DYNAMIC_APPLYING" 21 "EPB_STATUS_COUNT" 12 "EPB_STATUS_PARK_PENDING" 13 "EPB_STATUS_WINCHMODE_PENDING" 6 "EPB_STATUS_WINCHMODE" 3 "EPB_STATUS_PARK" 0 "EPB_STATUS_UNKNOWN" 4 "EPB_STATUS_START" 18 "EPB_STATUS_RELEASING_FOR_EXTERNAL_PARK" 19 "EPB_STATUS_EXTERNAL_PARKING" 17 "EPB_STATUS_EXTERNAL_DYNAMIC" 10 "EPB_STATUS_RELEASING" 15 "EPB_STATUS_SUMMON_RELEASING" 11 "EPB_STATUS_SERVICE_RELEASING" 7 "EPB_STATUS_WINCHMODE_RELEASING" 16 "EPB_STATUS_SUMMON_PARKING" 8 "EPB_STATUS_PARKING" 2 "EPB_STATUS_DYNAMIC" 5 "EPB_STATUS_SERVICE" 20 "EPB_STATUS_DYNAMIC_PARKING" ;
VAL_ 626 VCLEFT_epbmSummonState 3 "EPB_SUMMON_ACTIVE" 6 "EPB_SUMMON_UNAVAILABLE" 5 "EPB_SUMMON_FAULT" 4 "EPB_SUMMON_COMPLETE" 1 "EPB_SUMMON_IDLE" 2 "EPB_SUMMON_ARMED" 0 "EPB_SUMMON_INIT" ;
VAL_ 626 VCLEFT_epbSummonState 3 "EPB_SUMMON_ACTIVE" 6 "EPB_SUMMON_UNAVAILABLE" 5 "EPB_SUMMON_FAULT" 4 "EPB_SUMMON_COMPLETE" 1 "EPB_SUMMON_IDLE" 2 "EPB_SUMMON_ARMED" 0 "EPB_SUMMON_INIT" ;
VAL_ 626 VCLEFT_summonFaultReason 9 "EPB_SUMMONFAULT_VEH_CAN_FAULT" 21 "EPB_SUMMONFAULT_PASSIVE_REQUEST" 26 "EPB_SUMMONFAULT_START_IN_UNAVAILABLE" 5 "EPB_SUMMONFAULT_DI_FAULT" 4 "EPB_SUMMONFAULT_EPBM_MIA" 12 "EPB_SUMMONFAULT_SPEED" 14 "EPB_SUMMONFAULT_PARK_MIA" 19 "EPB_SUMMONFAULT_EPB_FAULT" 25 "EPB_SUMMONFAULT_REMOTE_UNIT_FAULTED" 11 "EPB_SUMMONFAULT_EPBM_REQUEST" 16 "EPB_SUMMONFAULT_PM_REQUEST" 6 "EPB_SUMMONFAULT_DI_APC_FAULT" 13 "EPB_SUMMONFAULT_EXTERNAL" 23 "EPB_SUMMONFAULT_REMOTE_SUMMON_FAULTED" 24 "EPB_SUMMONFAULT_LOCAL_UNIT_FAULTED" 28 "EPB_SUMMONFAULT_REMOTE_DID_NOT_START" 1 "EPB_SUMMONFAULT_DI_MIA" 15 "EPB_SUMMONFAULT_PM_MIA" 27 "EPB_SUMMONFAULT_INVALID_REMOTE_STATE" 0 "EPB_SUMMONFAULT_NONE" 10 "EPB_SUMMONFAULT_EAC_NOT_ALLOWED" 22 "EPB_SUMMONFAULT_EPBREMOTE_MIA" 18 "EPB_SUMMONFAULT_MISMATCH" 3 "EPB_SUMMONFAULT_ESP_MIA" 2 "EPB_SUMMONFAULT_DAS_MIA" 20 "EPB_SUMMONFAULT_DI_STATE_INVALID" 8 "EPB_SUMMONFAULT_ESP_FAULT" 17 "EPB_SUMMONFAULT_OOC" 7 "EPB_SUMMONFAULT_DAS_FAULT" ;
VAL_ 626 VCLEFT_cdpEnumDummy 0 "EPB_EXTERNAL_APPLY_IDLE" 1 "EPB_EXTERNAL_APPLY_VALID" 2 "EPB_EXTERNAL_APPLY_INVALID" ;
VAL_ 626 VCLEFT_epbmCaliperState 5 "EPB_SAVED_CALIPERSTATE_SERVICE" 1 "EPB_SAVED_CALIPERSTATE_UNKNOWN" 4 "EPB_SAVED_CALIPERSTATE_OPEN" 2 "EPB_SAVED_CALIPERSTATE_REAPPLY" 0 "EPB_SAVED_CALIPERSTATE_UNSAVED" 3 "EPB_SAVED_CALIPERSTATE_PARK" ;
VAL_ 626 VCLEFT_epbmDebugIndex 0 "EPBM_STATES" 1 "EPBM_TRANSITIONS" ;
VAL_ 1096 EPBR_nmWakeUpReason 0 "EPB3_WAKEUP_REASON_NONE" 3 "EPB3_WAKEUP_REASON_RESET" 1 "EPB3_WAKEUP_REASON_ECU_SPECIFIC" 2 "EPB3_WAKEUP_REASON_SWITCH_INPUT" ;
VAL_ 1096 EPBR_nmKeepAwakeReason 0 "EPB3_KEEPAWAKE_REASON_NONE_SNA" 1 "EPB3_KEEPAWAKE_REASON_EPB_STATE_NOT_SAVED" 15 "EPB3_KEEPAWAKE_REASON_MULTIPLE" 2 "EPB3_KEEPAWAKE_REASON_EPB_NOT_SECURE" 5 "EPB3_KEEPAWAKE_REASON_UDS_ACTIVE" 3 "EPB3_KEEPAWAKE_REASON_EPB_LOCKOUT_PENDING" 4 "EPB3_KEEPAWAKE_REASON_EPB_SUMMON_ACTIVE" ;
VAL_ 642 VCLEFT_hvacBlowerCBCCtrlState 1 "IDLE" 3 "ONLINE" 0 "ERROR" 4 "COUNT" 2 "OFFLINE" ;
VAL_ 642 VCLEFT_hvacBlowerCBCEstState 1 "IDLE" 8 "RAMPDOWN" 13 "ONLINE" 2 "ROVERL" 0 "ERROR" 14 "COUNT" 5 "IDRATED" 4 "RAMPUP" 3 "RS" 12 "MOTOR_IDENTIFIED" 9 "LOCKROTOR" 10 "INDUCTANCE_EST" 6 "RATEDFLUX_OL" 11 "ROTOR_RESISTANCE" 7 "RATEDFLUX" ;
VAL_ 642 VCLEFT_hvacBlowerITerm 127 "SNA" ;
VAL_ 642 VCLEFT_hvacBlowerFETTemp 127 "SNA" ;
VAL_ 642 VCLEFT_hvacBlower_IO_CBC_Status 0 "IDLE" 1 "RX" ;
VAL_ 642 VCLEFT_hvacBlowerTorque 1023 "SNA" ;
VAL_ 642 VCLEFT_hvacBlowerIPhase2 255 "SNA" ;
VAL_ 642 VCLEFT_hvacBlowerIPhase1 255 "SNA" ;
VAL_ 642 VCLEFT_hvacBlowerIPhase0 255 "SNA" ;
VAL_ 642 VCLEFT_hvacBlowerRPMTarget 1023 "SNA" ;
VAL_ 642 VCLEFT_hvacBlowerOutputDuty 127 "SNA" ;
VAL_ 642 VCLEFT_hvacBlowerRs 255 "SNA" ;
VAL_ 642 VCLEFT_blowerIndex 1 "HVAC_VARS" 0 "HVAC_FEEDBACK_SIGNALS" ;
VAL_ 525 TAS_limpHomeMode 4 "LIMP_HOME_MODE_40" 1 "LIMP_HOME_MODE_10" 0 "LIMP_HOME_MODE_0" 2 "LIMP_HOME_MODE_20" 3 "LIMP_HOME_MODE_30" ;
VAL_ 525 TAS_targetLevel 3 "LOW" 2 "STANDARD" 0 "VERY_HIGH" 4 "VERY_LOW" 1 "HIGH" ;
VAL_ 525 TAS_currentLevel 3 "LOW" 2 "STANDARD" 0 "VERY_HIGH" 4 "VERY_LOW" 1 "HIGH" ;
VAL_ 525 TAS_filterMode 6 "MODE_DRIVE" 2 "MODE_CALIBRATE" 7 "MODE_STOPPING" 4 "MODE_READY" 5 "MODE_LOADING" 3 "MODE_TEST" 0 "MODE_NONE" 1 "MODE_INIT" ;
VAL_ 525 TAS_runMode 3 "RUN_MODE_ASSEMBLY" 2 "RUN_MODE_SERVICE" 0 "RUN_MODE_INIT" 1 "RUN_MODE_SYSTEM_CHECK" 6 "RUN_MODE_LOW_POWER" 5 "RUN_MODE_NORMAL" 4 "RUN_MODE_DAN" ;
VAL_ 525 TAS_pressureReservoir 255 "SNA" ;
VAL_ 525 TAS_pressureGallery 255 "SNA" ;
VAL_ 525 TAS_levelingState 5 "LEVELING_STATE_COMPRESSOR_PREFILL_GALLERY" 1 "LEVELING_STATE_READ_P_RESERVOIR" 2 "LEVELING_STATE_MANUAL_SPRING_CONTROL" 7 "LEVELING_STATE_FILL_SPRING_FROM_COMPRESSOR" 3 "LEVELING_STATE_EXHAUST_GALLERY" 11 "LEVELING_STATE_LOWER_SPRING" 9 "LEVELING_STATE_FILL_SPRING_FROM_RESERVOIR" 12 "LEVELING_STATE_EMPTY_RESERVOIR" 0 "LEVELING_STATE_IDLE" 6 "LEVELING_STATE_FILL_RESERVOIR_FROM_COMPRESSOR" 10 "LEVELING_STATE_FILL_SPRING_RESERVOIR_FROM_COMPRESSOR" 8 "LEVELING_STATE_FILL_SPRING_FROM_BOOST" 4 "LEVELING_STATE_COMPRESSOR_RAMPUP" ;
VAL_ 1906 BMS_dieTemperatureStatus3 0 "SENSOR_SNA" 1 "SENSOR_BAD" 2 "SENSOR_NOMINAL" 3 "SENSOR_BYPASSED" ;
VAL_ 1906 BMS_dieTemperatureStatus6 0 "SENSOR_SNA" 1 "SENSOR_BAD" 2 "SENSOR_NOMINAL" 3 "SENSOR_BYPASSED" ;
VAL_ 1906 BMS_dieTemperatureStatus2 0 "SENSOR_SNA" 1 "SENSOR_BAD" 2 "SENSOR_NOMINAL" 3 "SENSOR_BYPASSED" ;
VAL_ 1906 BMS_dieTemperatureStatus8 0 "SENSOR_SNA" 1 "SENSOR_BAD" 2 "SENSOR_NOMINAL" 3 "SENSOR_BYPASSED" ;
VAL_ 1906 BMS_dieTemperatureStatus5 0 "SENSOR_SNA" 1 "SENSOR_BAD" 2 "SENSOR_NOMINAL" 3 "SENSOR_BYPASSED" ;
VAL_ 1906 BMS_dieTemperatureStatus4 0 "SENSOR_SNA" 1 "SENSOR_BAD" 2 "SENSOR_NOMINAL" 3 "SENSOR_BYPASSED" ;
VAL_ 1906 BMS_dieTemperatureStatus1 0 "SENSOR_SNA" 1 "SENSOR_BAD" 2 "SENSOR_NOMINAL" 3 "SENSOR_BYPASSED" ;
VAL_ 1906 BMS_dieTemperatureStatus7 0 "SENSOR_SNA" 1 "SENSOR_BAD" 2 "SENSOR_NOMINAL" 3 "SENSOR_BYPASSED" ;
VAL_ 1906 BMS_10HzBmbDebug_Id 8 "BMS_10HZ_DBG_BMB_END" 4 "BMS_10HZ_DBG_BMB_MUX4" 3 "BMS_10HZ_DBG_BMB_MUX3" 2 "BMS_10HZ_DBG_BMB_MUX2" 7 "BMS_10HZ_DBG_BMB_MUX7" 1 "BMS_10HZ_DBG_BMB_MUX1" 6 "BMS_10HZ_DBG_BMB_MUX6" 0 "BMS_10HZ_DBG_BMB_MUX0" 5 "BMS_10HZ_DBG_BMB_MUX5" ;
VAL_ 842 VCSEC_CenterNFCStateReason 1 "NFC_CENTER_OFF_REASON_TRANSPORT_MODE_SLEEP" 10 "NFC_CENTER_ON_OFF_REASON_NONE" 2 "NFC_CENTER_OFF_REASON_CAR_IN_DRIVE" 3 "NFC_CENTER_ON_REASON_LOCKSTATE_PANEL_ACTIVE" 9 "NFC_CENTER_OFF_REASON_KEY_ALREADY_AUTHENTICATED_AVOID_APPLE_PAY_POP_UP" 0 "NFC_CENTER_ON_OFF_REASON_UDS_OVERRIDE" 6 "NFC_CENTER_ON_REASON_IMMOBILIZERFAULT_SET" 7 "NFC_CENTER_ON_REASON_KEYPAIRING_IN_PROGRESS" 8 "NFC_CENTER_OFF_REASON_ACCESSORY_RAIL_OFF" 5 "NFC_CENTER_ON_REASON_ACC_RAIL_ON_AND_NOT_AUTHENTICATED" 4 "NFC_CENTER_ON_REASON_PRESSING_BRAKE_TO_SHIFT_TO_DRIVE" ;
VAL_ 842 VCSEC_BPillarNFCStateReason 4 "NFC_B_PILLAR_ON_REASON_DRIVER_JUST_LEFT" 0 "NFC_B_PILLAR_ON_OFF_REASON_UDS_OVERRIDE" 2 "NFC_B_PILLAR_OFF_REASON_CAR_IN_DRIVE" 5 "NFC_B_PILLAR_ON_REASON_CAR_IN_CONDITIONING" 3 "NFC_B_PILLAR_ON_REASON_EXTERIOR_HANDLE_PULLED" 1 "NFC_B_PILLAR_OFF_REASON_TRANSPORT_MODE_SLEEP" 6 "NFC_B_PILLAR_ON_OFF_REASON_NONE" ;
VAL_ 842 VCSEC_BPillarNFCReaderState 1 "NFC_READER_STATE_ALWAYS_READ" 3 "NFC_READER_STATE_CHANGE" 0 "NFC_READER_STATE_READING_DISABLED" 2 "NFC_READER_STATE_READ_ON_WAKE" ;
VAL_ 842 VCSEC_CenterNFCReaderState 1 "NFC_READER_STATE_ALWAYS_READ" 3 "NFC_READER_STATE_CHANGE" 0 "NFC_READER_STATE_READING_DISABLED" 2 "NFC_READER_STATE_READ_ON_WAKE" ;
VAL_ 842 VCSEC_NFCReaderIndexDebug 0 "BLEENDPOINT_LEFT_B_PILLAR" 3 "BLEENDPOINT_CENTER_CONSOLE" 2 "BLEENDPOINT_REAR_BUMPER" 1 "BLEENDPOINT_RIGHT_B_PILLAR" ;
VAL_ 930 VCLEFT_swcPCBATemperature -128 "SNA" ;
VAL_ 930 VCLEFT_swcInputVoltage 255 "SNA" ;
VAL_ 930 VCLEFT_tlcPCBATemperature -128 "SNA" ;
VAL_ 930 VCLEFT_vehiclePowerStateDBG 3 "VEHICLE_POWER_STATE_DRIVE" 1 "VEHICLE_POWER_STATE_CONDITIONING" 2 "VEHICLE_POWER_STATE_ACCESSORY" 0 "VEHICLE_POWER_STATE_OFF" ;
VAL_ 930 VCLEFT_statusIndex 0 "MUX0" 1 "MUX1" ;
VAL_ 1862 DBG_dynoCtrlSelector 3 "MAN_FLUX_REF_TORQUE_MODE" 0 "DISABLED" 1 "TORQUE_MODE" 2 "SPEED_MODE" ;
VAL_ 1862 DBG_dynoStateRequest 1 "DI_STATE_STANDBY" 3 "DI_STATE_ABORT" 4 "DI_STATE_ENABLE" 0 "DI_STATE_UNAVAILABLE" 2 "DI_STATE_FAULT" ;
VAL_ 340 PM_vehicleHoldRequest 1 "PM_VHLD_OFF_REQUEST" 0 "PM_NO_VHLD_REQUEST" ;
VAL_ 340 PM_checkState 1 "TRQ_CHECK_POLICING" 4 "TRQ_CHECK_CANNOT_POLICE_AT_ALL" 2 "TRQ_CHECK_CANNOT_POLICE_COMMAND" 3 "TRQ_CHECK_CANNOT_POLICE_MEASUREMENT" 0 "TRQ_CHECK_START" ;
VAL_ 340 PM_limpRequest 2 "PM_LIMP_SYSTEM" 1 "PM_LIMP_UNIT" 0 "PM_LIMP_OK" ;
VAL_ 340 PM_torqueCmdState 8 "TorqueCmd_Invalid" 6 "TorqueCmd_Valid" 0 "TorqueCmd_SNA" ;
VAL_ 340 PM_aebRequest 0 "PM_NO_AEB_REQUEST" 1 "PM_AEB_OFF_REQUEST" ;
VAL_ 340 PM_soptState 3 "SOPT_CURRENT_TEST" 1 "SOPT_PSTG_BRING_UP" 7 "SOPT_SNA" 2 "SOPT_ASC_TEST" 0 "SOPT_INIT" 6 "SOPT_TEST_FAILED" 5 "SOPT_TEST_SKIPPED" 4 "SOPT_TEST_PASSED" ;
VAL_ 776 OCS1P_classificationHoldState 1 "OCCUPANCY_HOLD_BASIC" 2 "OCCUPANCY_HOLD_EXTERNAL" 0 "OCCUPANCY_HOLD_OFF" 3 "OCCUPANCY_HOLD_FAULT" ;
VAL_ 776 OCS1P_occupantClassificationSelf 4 "OCCUPANT_CLASSIFICATION_INIT" 2 "OCCUPANT_CLASSIFICATION_OCCUPIED_ALLOW_SMALL" 3 "OCCUPANT_CLASSIFICATION_OCCUPIED_ALLOW_LARGE" 0 "OCCUPANT_CLASSIFICATION_EMPTY" 255 "OCCUPANT_CLASSIFICATION_SNA" 1 "OCCUPANT_CLASSIFICATION_OCCUPIED_INHIBIT" ;
VAL_ 776 OCS1P_occupantClassificationRaw 4 "OCCUPANT_CLASSIFICATION_INIT" 2 "OCCUPANT_CLASSIFICATION_OCCUPIED_ALLOW_SMALL" 3 "OCCUPANT_CLASSIFICATION_OCCUPIED_ALLOW_LARGE" 0 "OCCUPANT_CLASSIFICATION_EMPTY" 255 "OCCUPANT_CLASSIFICATION_SNA" 1 "OCCUPANT_CLASSIFICATION_OCCUPIED_INHIBIT" ;
VAL_ 776 OCS1P_occupiedState 0 "OCCUPIED_STATE_UNOCCUPIED" 3 "OCCUPIED_STATE_SNA" 1 "OCCUPIED_STATE_OCCUPIED" ;
VAL_ 776 OCS1P_occupantClassificationQF 1 "OCCUPANT_CLASSIFICATION_NOT_FAULTED" 0 "OCCUPANT_CLASSIFICATION_FAULTED" ;
VAL_ 776 OCS1P_occupantClassification 4 "OCCUPANT_CLASSIFICATION_INIT" 2 "OCCUPANT_CLASSIFICATION_OCCUPIED_ALLOW_SMALL" 3 "OCCUPANT_CLASSIFICATION_OCCUPIED_ALLOW_LARGE" 0 "OCCUPANT_CLASSIFICATION_EMPTY" 255 "OCCUPANT_CLASSIFICATION_SNA" 1 "OCCUPANT_CLASSIFICATION_OCCUPIED_INHIBIT" ;
VAL_ 535 FC_uiStopType 1 "FC_UI_STOP_TYPE_TOGGLE" 0 "FC_UI_STOP_TYPE_SNA" 2 "FC_UI_STOP_TYPE_MOMENTARY" ;
VAL_ 535 FC_coolingType 0 "FC_COOLING_TYPE_SNA" 1 "FC_COOLING_TYPE_CONVECTION" 2 "FC_COOLING_TYPE_LIQUID" ;
VAL_ 535 FC_brand 0 "FC_BRAND_SNA" 1 "FC_BRAND_TESLA" ;
VAL_ 535 FC_class 0 "FC_CLASS_SNA" 1 "FC_CLASS_SUPERCHARGER" 2 "FC_CLASS_URBANCHARGER" ;
VAL_ 535 FC_status3DataSelect 0 "Mux0" ;
VAL_ 513 VCFRONT_fiveWayValveMode 0 "SERIES" 1 "PARALLEL" ;
VAL_ 513 VCFRONT_pressureRefrigDischargeV 255 "SNA" ;
VAL_ 513 VCFRONT_pressureRefrigSuctionVit 127 "SNA" ;
VAL_ 513 VCFRONT_solenoidEvapState 2 "CLOSED" 1 "OPENED" 3 "FAULTED" 0 "UNDEFINED" ;
VAL_ 513 VCFRONT_tempSuperheatActual 1023 "SNA" ;
VAL_ 513 VCFRONT_exvState 5 "WAIT" 4 "FAULTED" 1 "INIT_OPEN" 3 "READY" 2 "INIT_CLOSE" 0 "UNINIT" ;
VAL_ 513 VCFRONT_radiatorFanRPMActual 1023 "SNA" ;
VAL_ 513 VCFRONT_compressorState 0 "STANDBY" 2 "RUNNING" 3 "FAULT" 1 "READY" ;
VAL_ 513 VCFRONT_pumpPowertrainRPMActual 1023 "SNA" ;
VAL_ 513 VCFRONT_tempRefrigDischarge 2047 "SNA" ;
VAL_ 513 VCFRONT_pumpBatteryRPMActual 1023 "SNA" ;
VAL_ 513 VCFRONT_loggingAndVitals10HzInde 0 "TARGETS_AND_ACTUALS" 2 "END" 1 "STATES_AND_SENSORS" ;
VAL_ 1001 DAS_turnIndicatorRequestReason 8 "DAS_ACTIVE_COMMANDED_LANE_CHANGE" 4 "DAS_CANCEL_LANE_CHANGE" 6 "DAS_ACTIVE_MERGE" 2 "DAS_ACTIVE_SPEED_LANE_CHANGE" 5 "DAS_CANCEL_FORK" 0 "DAS_NONE" 3 "DAS_ACTIVE_FORK" 7 "DAS_CANCEL_MERGE" 1 "DAS_ACTIVE_NAV_LANE_CHANGE" ;
VAL_ 1001 DAS_highLowBeamOffReason 0 "HIGH_BEAM_ON" 3 "HIGH_BEAM_OFF_REASON_AMBIENT_LIGHT" 1 "HIGH_BEAM_OFF_REASON_MOVING_VISION_TARGET" 2 "HIGH_BEAM_OFF_REASON_MOVING_RADAR_TARGET" 4 "HIGH_BEAM_OFF_REASON_HEAD_LIGHT" 5 "HIGH_BEAM_OFF_REASON_SNA" ;
VAL_ 1001 DAS_heaterRequest 0 "DAS_HEATER_SNA" 2 "DAS_HEATER_ON" 1 "DAS_HEATER_OFF" ;
VAL_ 1001 DAS_highLowBeamDecision 2 "DAS_HIGH_BEAM_ON" 1 "DAS_HIGH_BEAM_OFF" 3 "DAS_HIGH_BEAM_SNA" 0 "DAS_HIGH_BEAM_UNDECIDED" ;
VAL_ 1001 DAS_turnIndicatorRequest 0 "DAS_TURN_INDICATOR_NONE" 2 "DAS_TURN_INDICATOR_RIGHT" 3 "DAS_TURN_INDICATOR_CANCEL" 1 "DAS_TURN_INDICATOR_LEFT" ;
VAL_ 1001 DAS_wiperSpeed 3 "DAS_WIPER_SPEED_3" 12 "DAS_WIPER_SPEED_12" 8 "DAS_WIPER_SPEED_8" 14 "DAS_WIPER_SPEED_14" 5 "DAS_WIPER_SPEED_5" 13 "DAS_WIPER_SPEED_13" 2 "DAS_WIPER_SPEED_2" 0 "DAS_WIPER_SPEED_OFF" 4 "DAS_WIPER_SPEED_4" 1 "DAS_WIPER_SPEED_1" 15 "DAS_WIPER_SPEED_INVALID" 10 "DAS_WIPER_SPEED_10" 11 "DAS_WIPER_SPEED_11" 7 "DAS_WIPER_SPEED_7" 9 "DAS_WIPER_SPEED_9" 6 "DAS_WIPER_SPEED_6" ;
VAL_ 1001 DAS_hazardLightRequest 3 "DAS_REQUEST_HAZARDS_SNA" 2 "DAS_REQUEST_HAZARDS_UNUSED" 0 "DAS_REQUEST_HAZARDS_OFF" 1 "DAS_REQUEST_HAZARDS_ON" ;
VAL_ 1001 DAS_headlightRequest 3 "DAS_HEADLIGHT_REQUEST_INVALID" 1 "DAS_HEADLIGHT_REQUEST_ON" 0 "DAS_HEADLIGHT_REQUEST_OFF" ;
VAL_ 979 VCRIGHT_crashState 2 "CRASH_STATE_SEVERE" 0 "CRASH_STATE_IDLE" 1 "CRASH_STATE_MINOR" ;
VAL_ 979 VCRIGHT_crashDetectedType 1 "CRASH_DETECTED_TYPE_MINOR" 0 "CRASH_DETECTED_TYPE_NONE" 2 "CRASH_DETECTED_TYPE_SEVERE" ;
